VERSION ""

NS_ :

BS_:

BU_: LMFS RMFS TPMS TCU_ERAGLONASS E_APU PCCM NOX_2 NOX_1 ENGINE_CONTROL_MODULE TRANSMISSION INTARDER EBS TACHOGRAPH INSTRUMENT_CLUSTER CAMERA RADAR BCM

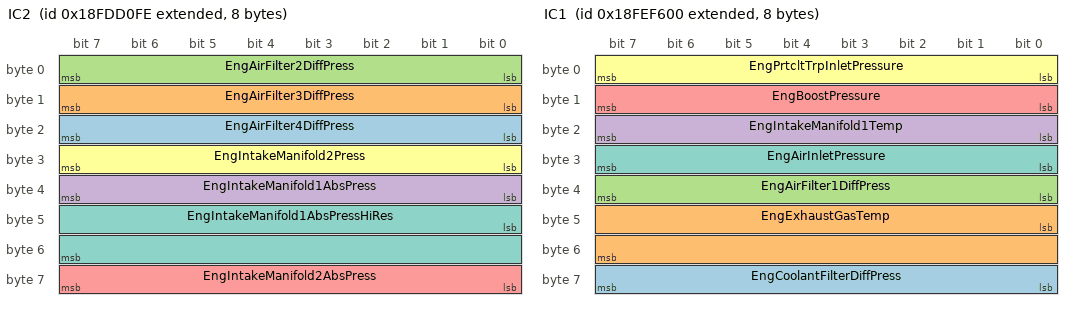
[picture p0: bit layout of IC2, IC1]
BO_ 2566770942 IC2: 8 Vector__XXX
 SG_ EngAirFilter4DiffPress : 16|8@1+ (0.05,0) [0|12.5] "kPa" Vector__XXX
 SG_ EngAirFilter3DiffPress : 8|8@1+ (0.05,0) [0|12.5] "kPa" Vector__XXX
 SG_ EngAirFilter2DiffPress : 0|8@1+ (0.05,0) [0|12.5] "kPa" Vector__XXX
 SG_ EngIntakeManifold1AbsPress : 32|8@1+ (0.1,0) [0|25.5] "kPa" Vector__XXX
 SG_ EngIntakeManifold2AbsPress : 56|8@1+ (2,0) [0|500] "kPa" Vector__XXX
 SG_ EngIntakeManifold2Press : 24|8@1+ (2,0) [0|500] "kPa" Vector__XXX
 SG_ EngIntakeManifold1AbsPressHiRes : 40|16@1+ (0.1,0) [0|6425.5] "kPa" Vector__XXX

BO_ 2566845952 IC1: 8 ENGINE_CONTROL_MODULE
 SG_ EngCoolantFilterDiffPress : 56|8@1+ (0.5,0) [0|125] "kPa"  PCCM,BCM
 SG_ EngExhaustGasTemp : 40|16@1+ (0.03125,-271) [-271|1715] "deg C"  PCCM,BCM
 SG_ EngAirFilter1DiffPress : 32|8@1+ (0.05,0) [0|12.5] "kPa"  PCCM,BCM
 SG_ EngIntakeManifold1Temp : 16|8@1+ (1,-40) [-40|210] "deg C"  PCCM,BCM
 SG_ EngBoostPressure : 8|8@1+ (2,0) [0|500] "kPa"  PCCM,BCM
 SG_ EngPrtcltTrpInletPressure : 0|8@1+ (0.5,0) [0|125] "kPa"  PCCM,BCM
 SG_ EngAirInletPressure : 24|8@1+ (2,0) [0|500] "kPa"  PCCM,BCM

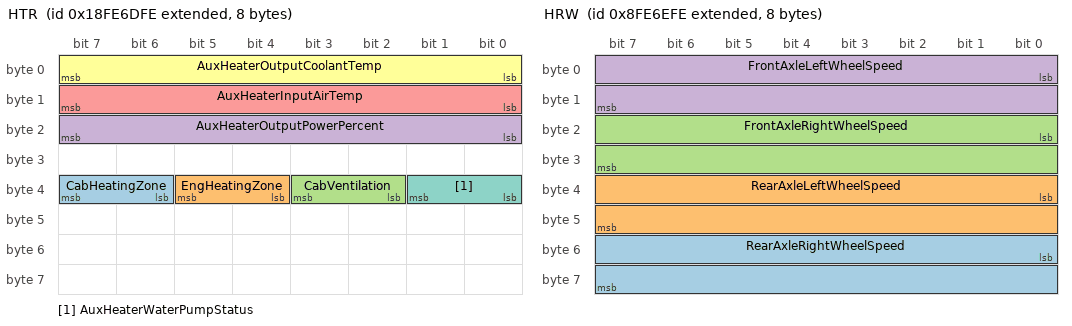
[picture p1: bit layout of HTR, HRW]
BO_ 2566811134 HTR: 8 Vector__XXX
 SG_ CabHeatingZone : 38|2@1+ (1,0) [0|3] "" Vector__XXX
 SG_ EngHeatingZone : 36|2@1+ (1,0) [0|3] "" Vector__XXX
 SG_ CabVentilation : 34|2@1+ (1,0) [0|3] "" Vector__XXX
 SG_ AuxHeaterOutputPowerPercent : 16|8@1+ (0.4,0) [0|100] "%" Vector__XXX
 SG_ AuxHeaterInputAirTemp : 8|8@1+ (1,-40) [-40|210] "deg C" Vector__XXX
 SG_ AuxHeaterOutputCoolantTemp : 0|8@1+ (1,-40) [-40|210] "deg C" Vector__XXX
 SG_ AuxHeaterWaterPumpStatus : 32|2@1+ (1,0) [0|3] "" Vector__XXX

BO_ 2298375934 HRW: 8 Vector__XXX
 SG_ RearAxleRightWheelSpeed : 48|16@1+ (0.00390625,0) [0|250.996] "km/h" Vector__XXX
 SG_ RearAxleLeftWheelSpeed : 32|16@1+ (0.00390625,0) [0|250.996] "km/h" Vector__XXX
 SG_ FrontAxleRightWheelSpeed : 16|16@1+ (0.00390625,0) [0|250.996] "km/h" Vector__XXX
 SG_ FrontAxleLeftWheelSpeed : 0|16@1+ (0.00390625,0) [0|250.996] "km/h" Vector__XXX

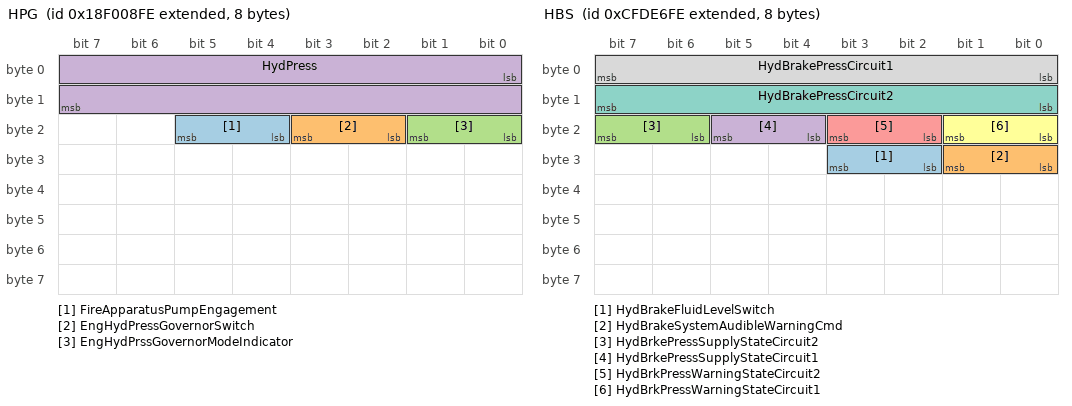
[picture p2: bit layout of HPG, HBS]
BO_ 2565867774 HPG: 8 Vector__XXX
 SG_ FireApparatusPumpEngagement : 20|2@1+ (1,0) [0|3] "" Vector__XXX
 SG_ EngHydPressGovernorSwitch : 18|2@1+ (1,0) [0|3] "" Vector__XXX
 SG_ EngHydPrssGovernorModeIndicator : 16|2@1+ (1,0) [0|3] "" Vector__XXX
 SG_ HydPress : 0|16@1+ (2,0) [0|128510] "kPa" Vector__XXX

BO_ 2566841600 HOURS: 8 ENGINE_CONTROL_MODULE
 SG_ EngTotalRevolutions : 32|32@1+ (1000,0) [0|2013264920] "r"  PCCM,BCM,INSTRUMENT_CLUSTER
 SG_ EngTotalHoursOfOperation : 0|32@1+ (0.05,0) [0|210554060.75] "hr"  PCCM,BCM,INSTRUMENT_CLUSTER

BO_ 2365449982 HBS: 8 Vector__XXX
 SG_ HydBrakeFluidLevelSwitch : 26|2@1+ (1,0) [0|3] "" Vector__XXX
 SG_ HydBrakeSystemAudibleWarningCmd : 24|2@1+ (1,0) [0|3] "" Vector__XXX
 SG_ HydBrkePressSupplyStateCircuit2 : 22|2@1+ (1,0) [0|3] "" Vector__XXX
 SG_ HydBrkePressSupplyStateCircuit1 : 20|2@1+ (1,0) [0|3] "" Vector__XXX
 SG_ HydBrkPressWarningStateCircuit2 : 18|2@1+ (1,0) [0|3] "" Vector__XXX
 SG_ HydBrkPressWarningStateCircuit1 : 16|2@1+ (1,0) [0|3] "" Vector__XXX
 SG_ HydBrakePressCircuit2 : 8|8@1+ (100,0) [0|25] "MPa" Vector__XXX
 SG_ HydBrakePressCircuit1 : 0|8@1+ (100,0) [0|25] "MPa" Vector__XXX

BO_ 2633939198 GTFI: 22 Vector__XXX
 SG_ TripDriveFuelEconomy : 160|16@1+ (0.001953125,0) [0|125.5] "km/kg" Vector__XXX
 SG_ TrpPTOGovernorNonmovingFuelUsed : 64|32@1+ (0.5,0) [0|2105540607.5] "kg" Vector__XXX
 SG_ TripVehicleIdleFuelUsed : 96|32@1+ (0.5,0) [0|2105540607.5] "kg" Vector__XXX
 SG_ TripCruiseFuelUsed : 128|32@1+ (0.5,0) [0|2105540607.5] "kg" Vector__XXX
 SG_ TripDriveFuelUsed : 0|32@1+ (0.5,0) [0|2105540607.5] "kg" Vector__XXX
 SG_ TripPTOGovernorMovingFuelUsed : 32|32@1+ (0.5,0) [0|2105540607.5] "kg" Vector__XXX

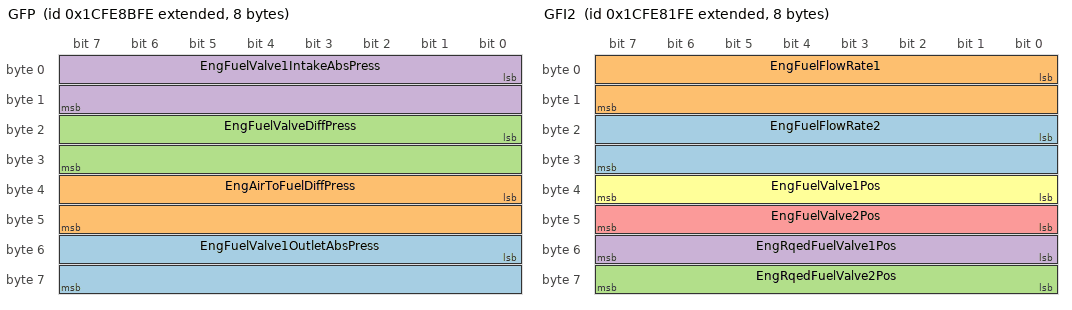
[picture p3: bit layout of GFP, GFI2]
BO_ 2633927678 GFP: 8 Vector__XXX
 SG_ EngFuelValve1OutletAbsPress : 48|16@1+ (0.1,0) [0|6425.5] "kPa" Vector__XXX
 SG_ EngAirToFuelDiffPress : 32|16@1+ (0.1,0) [0|6425.5] "kPa" Vector__XXX
 SG_ EngFuelValveDiffPress : 16|16@1+ (0.1,0) [0|6425.5] "kPa" Vector__XXX
 SG_ EngFuelValve1IntakeAbsPress : 0|16@1+ (0.1,0) [0|6425.5] "kPa" Vector__XXX

BO_ 2633925118 GFI2: 8 Vector__XXX
 SG_ EngFuelFlowRate2 : 16|16@1+ (0.1,0) [0|6425.5] "m³/h" Vector__XXX
 SG_ EngFuelFlowRate1 : 0|16@1+ (0.1,0) [0|6425.5] "m³/h" Vector__XXX
 SG_ EngRqedFuelValve2Pos : 56|8@1+ (0.4,0) [0|100] "%" Vector__XXX
 SG_ EngRqedFuelValve1Pos : 48|8@1+ (0.4,0) [0|100] "%" Vector__XXX
 SG_ EngFuelValve2Pos : 40|8@1+ (0.4,0) [0|100] "%" Vector__XXX
 SG_ EngFuelValve1Pos : 32|8@1+ (0.4,0) [0|100] "%" Vector__XXX

BO_ 2633937662 GFI1: 8 Vector__XXX
 SG_ TotalEngPTOGovernorFuelUsed : 0|32@1+ (0.5,0) [0|2105540607.5] "kg" Vector__XXX
 SG_ TripAverageFuelRate : 32|16@1+ (0.05,0) [0|3212.75] "kg/h" Vector__XXX
 SG_ EngFuelSpecificGravity : 48|16@1+ (0.0001,0) [0|6.4255] "" Vector__XXX

BO_ 2566804990 GFD: 8 Vector__XXX
 SG_ SpecificHeatRatio : 0|16@1+ (0.001,0) [0|64.255] "" Vector__XXX

BO_ 2633936894 GFC: 8 Vector__XXX
 SG_ TotalFuelUsed : 32|32@1+ (0.5,0) [0|2105540607.5] "kg" Vector__XXX
 SG_ TripFuel : 0|32@1+ (0.5,0) [0|2105540607.5] "kg" Vector__XXX

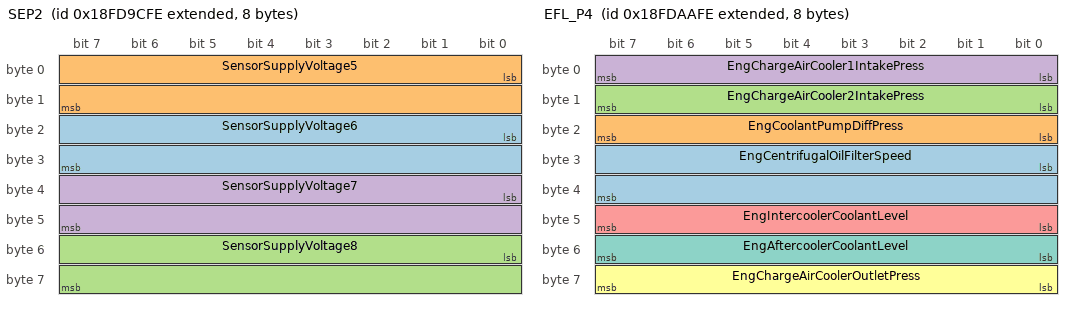
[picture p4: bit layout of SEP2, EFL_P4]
BO_ 2566757630 SEP2: 8 Vector__XXX
 SG_ SensorSupplyVoltage6 : 16|16@1+ (0.05,0) [0|3212.75] "V" Vector__XXX
 SG_ SensorSupplyVoltage5 : 0|16@1+ (0.05,0) [0|3212.75] "V" Vector__XXX
 SG_ SensorSupplyVoltage8 : 48|16@1+ (0.05,0) [0|3212.75] "V" Vector__XXX
 SG_ SensorSupplyVoltage7 : 32|16@1+ (0.05,0) [0|3212.75] "V" Vector__XXX

BO_ 2566757886 SEP1: 8 Vector__XXX
 SG_ SensorSupplyVoltage4 : 48|16@1+ (0.05,0) [0|3212.75] "V" Vector__XXX
 SG_ SensorSupplyVoltage3 : 32|16@1+ (0.05,0) [0|3212.75] "V" Vector__XXX
 SG_ SensorSupplyVoltage2 : 16|16@1+ (0.05,0) [0|3212.75] "V" Vector__XXX
 SG_ SensorSupplyVoltage1 : 0|16@1+ (0.05,0) [0|3212.75] "V" Vector__XXX

BO_ 2566759678 PTODE: 8 Vector__XXX
 SG_ EnggmntSttusTransInputShaftPTO1 : 38|2@1+ (1,0) [0|3] "" Vector__XXX
 SG_ EnggmntSttusTransInputShaftPTO2 : 36|2@1+ (1,0) [0|3] "" Vector__XXX
 SG_ EnggmntSttusTransOutputShaftPTO : 34|2@1+ (1,0) [0|3] "" Vector__XXX
 SG_ EnggmntSttsTrnsfrCsOtptShaftPTO : 32|2@1+ (1,0) [0|3] "" Vector__XXX
 SG_ EnggmntCnsntTransInputShaftPTO1 : 22|2@1+ (1,0) [0|3] "" Vector__XXX
 SG_ EnggmntCnsntTransInputShaftPTO2 : 20|2@1+ (1,0) [0|3] "" Vector__XXX
 SG_ EnggmntCnsntTransOutputShaftPTO : 18|2@1+ (1,0) [0|3] "" Vector__XXX
 SG_ EnggmntCnsntTrnsfrCsOtptShftPTO : 16|2@1+ (1,0) [0|3] "" Vector__XXX
 SG_ EnableSwitchTransInputShaftPTO1 : 6|2@1+ (1,0) [0|3] "" Vector__XXX
 SG_ EnableSwitchTransInputShaftPTO2 : 4|2@1+ (1,0) [0|3] "" Vector__XXX
 SG_ EnableSwitchTransOutputShaftPTO : 2|2@1+ (1,0) [0|3] "" Vector__XXX
 SG_ EnblSwtchTrnsfrCsOutputShaftPTO : 0|2@1+ (1,0) [0|3] "" Vector__XXX
 SG_ EnggmntSttsPTOEngAccssoryDrive2 : 44|2@1+ (1,0) [0|3] "" Vector__XXX
 SG_ EnggmntSttsPTOEngAccssoryDrive1 : 42|2@1+ (1,0) [0|3] "" Vector__XXX
 SG_ EnggmntCnsntPTOEngAccssryDrive2 : 28|2@1+ (1,0) [0|3] "" Vector__XXX
 SG_ EnggmntCnsntPTOEngAccssryDrive1 : 26|2@1+ (1,0) [0|3] "" Vector__XXX
 SG_ EngagementStatusPTOEngFlywheel : 40|2@1+ (1,0) [0|3] "" Vector__XXX
 SG_ EngagementConsentPTOEngFlywheel : 24|2@1+ (1,0) [0|3] "" Vector__XXX
 SG_ EnblSwitchPTOEngAccessoryDrive2 : 12|2@1+ (1,0) [0|3] "" Vector__XXX
 SG_ EnblSwitchPTOEngAccessoryDrive1 : 10|2@1+ (1,0) [0|3] "" Vector__XXX
 SG_ EnableSwitchPTOEngFlywheel : 8|2@1+ (1,0) [0|3] "" Vector__XXX
 SG_ AtLeastOnePTOEngaged : 48|2@1+ (1,0) [0|3] "" Vector__XXX

BO_ 2432541438 GFI3: 8 Vector__XXX
 SG_ EngFuelValve2OutletAbsPress : 48|16@1+ (0.1,0) [0|6425.5] "kPa" Vector__XXX
 SG_ EngFuelTemp2 : 32|8@1+ (1,-40) [-40|210] "deg C" Vector__XXX
 SG_ EngGas2MassFlowRate : 16|16@1+ (0.05,0) [0|3212.75] "kg/h" Vector__XXX
 SG_ EngFuelValve2IntakeAbsPress : 0|16@1+ (0.1,0) [0|6425.5] "kPa" Vector__XXX

BO_ 2566761214 EFL_P4: 8 Vector__XXX
 SG_ EngCentrifugalOilFilterSpeed : 24|16@1+ (4,0) [0|257020] "rpm" Vector__XXX
 SG_ EngCoolantPumpDiffPress : 16|8@1+ (1.64,-7) [-7|403] "kPa" Vector__XXX
 SG_ EngChargeAirCooler2IntakePress : 8|8@1+ (2,0) [0|500] "kPa" Vector__XXX
 SG_ EngChargeAirCooler1IntakePress : 0|8@1+ (2,0) [0|500] "kPa" Vector__XXX
 SG_ EngIntercoolerCoolantLevel : 40|8@1+ (0.4,0) [0|100] "%" Vector__XXX
 SG_ EngChargeAirCoolerOutletPress : 56|8@1+ (2,0) [0|500] "kPa" Vector__XXX
 SG_ EngAftercoolerCoolantLevel : 48|8@1+ (0.4,0) [0|100] "%" Vector__XXX

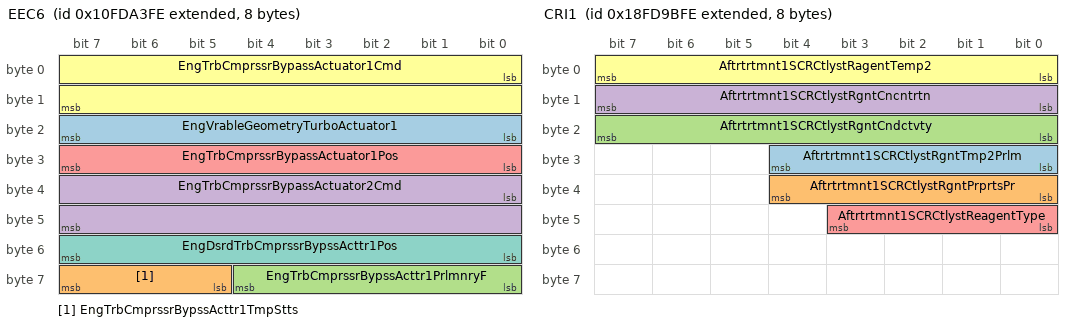
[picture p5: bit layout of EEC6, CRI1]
BO_ 2432541694 EEC6: 8 Vector__XXX
 SG_ EngVrableGeometryTurboActuator1 : 16|8@1+ (0.4,0) [0|100] "%" Vector__XXX
 SG_ EngTrbCmprssrBypssActtr1TmpStts : 61|3@1+ (1,0) [0|7] "" Vector__XXX
 SG_ EngTrbCmprssrBypssActtr1PrlmnryF : 56|5@1+ (1,0) [0|31] "" Vector__XXX
 SG_ EngTrbCmprssrBypassActuator2Cmd : 32|16@1+ (0.0025,0) [0|160.6375] "%" Vector__XXX
 SG_ EngTrbCmprssrBypassActuator1Pos : 24|8@1+ (0.4,0) [0|100] "%" Vector__XXX
 SG_ EngTrbCmprssrBypassActuator1Cmd : 0|16@1+ (0.0025,0) [0|160.6375] "%" Vector__XXX
 SG_ EngDsrdTrbCmprssrBypssActtr1Pos : 48|8@1+ (0.4,0) [0|100] "%" Vector__XXX

BO_ 2566759934 DC2: 8 Vector__XXX
 SG_ EnableStatusOfDoor10 : 58|2@1+ (1,0) [0|3] "" Vector__XXX
 SG_ OpenStatusOfDoor10 : 56|2@1+ (1,0) [0|3] "" Vector__XXX
 SG_ LockStatusOfDoor10 : 54|2@1+ (1,0) [0|3] "" Vector__XXX
 SG_ EnableStatusOfDoor9 : 52|2@1+ (1,0) [0|3] "" Vector__XXX
 SG_ OpenStatusOfDoor9 : 50|2@1+ (1,0) [0|3] "" Vector__XXX
 SG_ LockStatusOfDoor9 : 48|2@1+ (1,0) [0|3] "" Vector__XXX
 SG_ EnableStatusOfDoor8 : 46|2@1+ (1,0) [0|3] "" Vector__XXX
 SG_ OpenStatusOfDoor8 : 44|2@1+ (1,0) [0|3] "" Vector__XXX
 SG_ LockStatusOfDoor8 : 42|2@1+ (1,0) [0|3] "" Vector__XXX
 SG_ EnableStatusOfDoor7 : 40|2@1+ (1,0) [0|3] "" Vector__XXX
 SG_ OpenStatusOfDoor7 : 38|2@1+ (1,0) [0|3] "" Vector__XXX
 SG_ LockStatusOfDoor7 : 36|2@1+ (1,0) [0|3] "" Vector__XXX
 SG_ EnableStatusOfDoor6 : 34|2@1+ (1,0) [0|3] "" Vector__XXX
 SG_ OpenStatusOfDoor6 : 32|2@1+ (1,0) [0|3] "" Vector__XXX
 SG_ LockStatusOfDoor6 : 30|2@1+ (1,0) [0|3] "" Vector__XXX
 SG_ EnableStatusOfDoor5 : 28|2@1+ (1,0) [0|3] "" Vector__XXX
 SG_ OpenStatusOfDoor5 : 26|2@1+ (1,0) [0|3] "" Vector__XXX
 SG_ LockStatusOfDoor5 : 24|2@1+ (1,0) [0|3] "" Vector__XXX
 SG_ EnableStatusOfDoor4 : 22|2@1+ (1,0) [0|3] "" Vector__XXX
 SG_ OpenStatusOfDoor4 : 20|2@1+ (1,0) [0|3] "" Vector__XXX
 SG_ LockStatusOfDoor4 : 18|2@1+ (1,0) [0|3] "" Vector__XXX
 SG_ EnableStatusOfDoor3 : 16|2@1+ (1,0) [0|3] "" Vector__XXX
 SG_ OpenStatusOfDoor3 : 14|2@1+ (1,0) [0|3] "" Vector__XXX
 SG_ LockStatusOfDoor3 : 12|2@1+ (1,0) [0|3] "" Vector__XXX
 SG_ EnableStatusOfDoor2 : 10|2@1+ (1,0) [0|3] "" Vector__XXX
 SG_ OpenStatusOfDoor2 : 8|2@1+ (1,0) [0|3] "" Vector__XXX
 SG_ LockStatusOfDoor2 : 6|2@1+ (1,0) [0|3] "" Vector__XXX
 SG_ EnableStatusOfDoor1 : 4|2@1+ (1,0) [0|3] "" Vector__XXX
 SG_ OpenStatusOfDoor1 : 2|2@1+ (1,0) [0|3] "" Vector__XXX
 SG_ LockStatusOfDoor1 : 0|2@1+ (1,0) [0|3] "" Vector__XXX

BO_ 2566757374 CRI1: 8 Vector__XXX
 SG_ Aftrtrtmnt1SCRCtlystRgntTmp2Prlm : 24|5@1+ (1,0) [0|31] "" Vector__XXX
 SG_ Aftrtrtmnt1SCRCtlystRgntPrprtsPr : 32|5@1+ (1,0) [0|31] "" Vector__XXX
 SG_ Aftrtrtmnt1SCRCtlystRgntCndctvty : 16|8@1+ (5,0) [0|1250] "microSiemens/mm" Vector__XXX
 SG_ Aftrtrtmnt1SCRCtlystRgntCncntrtn : 8|8@1+ (0.25,0) [0|62.5] "%" Vector__XXX
 SG_ Aftrtrtmnt1SCRCtlystReagentType : 40|4@1+ (1,0) [0|15] "" Vector__XXX
 SG_ Aftrtrtmnt1SCRCtlystRagentTemp2 : 0|8@1+ (1,-40) [-40|210] "deg C" Vector__XXX

BO_ 2364546302 RGAAQ: 8 Vector__XXX
 SG_ RqdGnrtrAvrgLneLineACRMSVoltage : 0|32@1+ (0.0078125,0) [0|32899071] "V" Vector__XXX

BO_ 2431654654 TFAC: 8 Vector__XXX
 SG_ EngThrottleActuator2CtrlCmd : 16|16@1+ (0.0025,0) [0|160.6375] "%" Vector__XXX
 SG_ EngThrottleActuator1CtrlCmd : 0|16@1+ (0.0025,0) [0|160.6375] "%" Vector__XXX
 SG_ EngFuelActuator2CtrlCmd : 48|16@1+ (0.0025,0) [0|160.6375] "%" Vector__XXX
 SG_ EngFuelActuator1CtrlCmd : 32|16@1+ (0.0025,0) [0|160.6375] "%" Vector__XXX

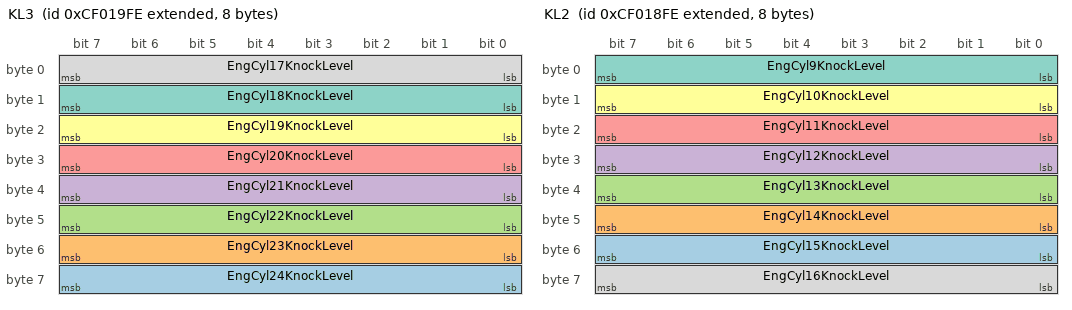
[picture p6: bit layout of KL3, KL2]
BO_ 2364545534 KL3: 8 Vector__XXX
 SG_ EngCyl24KnockLevel : 56|8@1+ (1,0) [0|250] "%" Vector__XXX
 SG_ EngCyl23KnockLevel : 48|8@1+ (1,0) [0|250] "%" Vector__XXX
 SG_ EngCyl22KnockLevel : 40|8@1+ (1,0) [0|250] "%" Vector__XXX
 SG_ EngCyl21KnockLevel : 32|8@1+ (1,0) [0|250] "%" Vector__XXX
 SG_ EngCyl20KnockLevel : 24|8@1+ (1,0) [0|250] "%" Vector__XXX
 SG_ EngCyl19KnockLevel : 16|8@1+ (1,0) [0|250] "%" Vector__XXX
 SG_ EngCyl18KnockLevel : 8|8@1+ (1,0) [0|250] "%" Vector__XXX
 SG_ EngCyl17KnockLevel : 0|8@1+ (1,0) [0|250] "%" Vector__XXX

BO_ 2364545278 KL2: 8 Vector__XXX
 SG_ EngCyl15KnockLevel : 48|8@1+ (1,0) [0|250] "%" Vector__XXX
 SG_ EngCyl14KnockLevel : 40|8@1+ (1,0) [0|250] "%" Vector__XXX
 SG_ EngCyl13KnockLevel : 32|8@1+ (1,0) [0|250] "%" Vector__XXX
 SG_ EngCyl12KnockLevel : 24|8@1+ (1,0) [0|250] "%" Vector__XXX
 SG_ EngCyl11KnockLevel : 16|8@1+ (1,0) [0|250] "%" Vector__XXX
 SG_ EngCyl10KnockLevel : 8|8@1+ (1,0) [0|250] "%" Vector__XXX
 SG_ EngCyl9KnockLevel : 0|8@1+ (1,0) [0|250] "%" Vector__XXX
 SG_ EngCyl16KnockLevel : 56|8@1+ (1,0) [0|250] "%" Vector__XXX

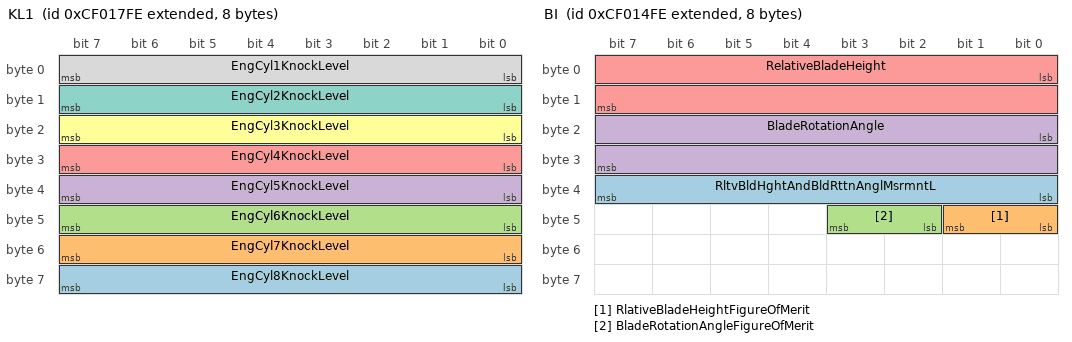
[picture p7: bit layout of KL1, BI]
BO_ 2364545022 KL1: 8 Vector__XXX
 SG_ EngCyl8KnockLevel : 56|8@1+ (1,0) [0|250] "%" Vector__XXX
 SG_ EngCyl7KnockLevel : 48|8@1+ (1,0) [0|250] "%" Vector__XXX
 SG_ EngCyl6KnockLevel : 40|8@1+ (1,0) [0|250] "%" Vector__XXX
 SG_ EngCyl5KnockLevel : 32|8@1+ (1,0) [0|250] "%" Vector__XXX
 SG_ EngCyl4KnockLevel : 24|8@1+ (1,0) [0|250] "%" Vector__XXX
 SG_ EngCyl3KnockLevel : 16|8@1+ (1,0) [0|250] "%" Vector__XXX
 SG_ EngCyl2KnockLevel : 8|8@1+ (1,0) [0|250] "%" Vector__XXX
 SG_ EngCyl1KnockLevel : 0|8@1+ (1,0) [0|250] "%" Vector__XXX

BO_ 2364544766 CCS: 8 Vector__XXX
 SG_ EngCyl9CombustionStatus : 16|2@1+ (1,0) [0|3] "" Vector__XXX
 SG_ EngCyl8CombustionStatus : 14|2@1+ (1,0) [0|3] "" Vector__XXX
 SG_ EngCyl7CombustionStatus : 12|2@1+ (1,0) [0|3] "" Vector__XXX
 SG_ EngCyl6CombustionStatus : 10|2@1+ (1,0) [0|3] "" Vector__XXX
 SG_ EngCyl5CombustionStatus : 8|2@1+ (1,0) [0|3] "" Vector__XXX
 SG_ EngCyl4CombustionStatus : 6|2@1+ (1,0) [0|3] "" Vector__XXX
 SG_ EngCyl3CombustionStatus : 4|2@1+ (1,0) [0|3] "" Vector__XXX
 SG_ EngCyl2CombustionStatus : 2|2@1+ (1,0) [0|3] "" Vector__XXX
 SG_ EngCyl24CombustionStatus : 46|2@1+ (1,0) [0|3] "" Vector__XXX
 SG_ EngCyl23CombustionStatus : 44|2@1+ (1,0) [0|3] "" Vector__XXX
 SG_ EngCyl22CombustionStatus : 42|2@1+ (1,0) [0|3] "" Vector__XXX
 SG_ EngCyl21CombustionStatus : 40|2@1+ (1,0) [0|3] "" Vector__XXX
 SG_ EngCyl20CombustionStatus : 38|2@1+ (1,0) [0|3] "" Vector__XXX
 SG_ EngCyl1CombustionStatus : 0|2@1+ (1,0) [0|3] "" Vector__XXX
 SG_ EngCyl19CombustionStatus : 36|2@1+ (1,0) [0|3] "" Vector__XXX
 SG_ EngCyl18CombustionStatus : 34|2@1+ (1,0) [0|3] "" Vector__XXX
 SG_ EngCyl17CombustionStatus : 32|2@1+ (1,0) [0|3] "" Vector__XXX
 SG_ EngCyl16CombustionStatus : 30|2@1+ (1,0) [0|3] "" Vector__XXX
 SG_ EngCyl15CombustionStatus : 28|2@1+ (1,0) [0|3] "" Vector__XXX
 SG_ EngCyl14CombustionStatus : 26|2@1+ (1,0) [0|3] "" Vector__XXX
 SG_ EngCyl13CombustionStatus : 24|2@1+ (1,0) [0|3] "" Vector__XXX
 SG_ EngCyl12CombustionStatus : 22|2@1+ (1,0) [0|3] "" Vector__XXX
 SG_ EngCyl11CombustionStatus : 20|2@1+ (1,0) [0|3] "" Vector__XXX
 SG_ EngCyl10CombustionStatus : 18|2@1+ (1,0) [0|3] "" Vector__XXX

BO_ 2364544510 RGTARP: 8 Vector__XXX
 SG_ RqGenOverallPowerFactorLagging : 48|2@1+ (1,0) [0|4] "" Vector__XXX
 SG_ RqGeneratorOverallPowerFactor : 32|16@1+ (6.103515625E-005,-1) [-1|2.921814] "" Vector__XXX
 SG_ RqGeneratorTotalACReactivePower : 0|32@1+ (1,-2000000000) [-2000000000|2000000000] "VA" Vector__XXX

BO_ 2364544254 BI: 8 Vector__XXX
 SG_ RltvBldHghtAndBldRttnAnglMsrmntL : 32|8@1+ (0.5,0) [0|125] "ms" Vector__XXX
 SG_ RlativeBladeHeightFigureOfMerit : 40|2@1+ (1,0) [0|3] "" Vector__XXX
 SG_ BladeRotationAngleFigureOfMerit : 42|2@1+ (1,0) [0|3] "" Vector__XXX
 SG_ BladeRotationAngle : 16|16@1+ (0.0078125,-200) [-200|301.99] "deg" Vector__XXX
 SG_ RelativeBladeHeight : 0|16@1+ (0.1,-3200) [-3200|3225.5] "mm" Vector__XXX

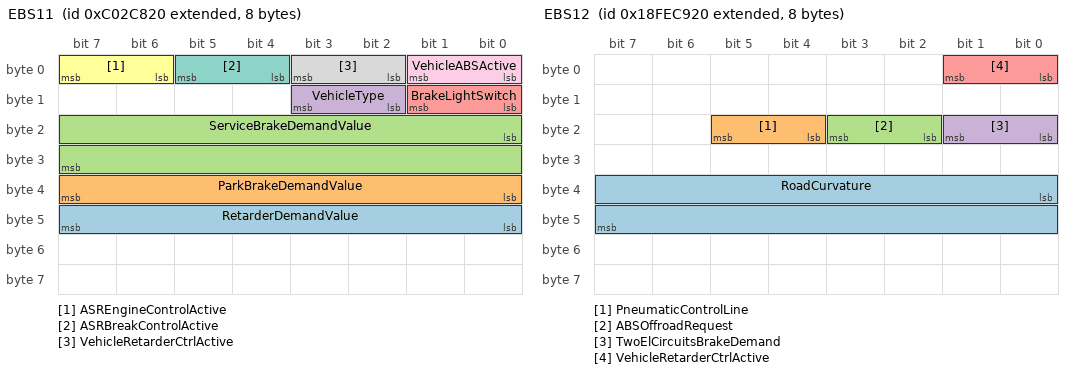
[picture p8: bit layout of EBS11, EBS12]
BO_ 2348992544 EBS11: 8 Vector__XXX
 SG_ RetarderDemandValue : 40|8@1+ (1,-125) [-125|125] "%" Vector__XXX
 SG_ ParkBrakeDemandValue : 32|8@1+ (0.4,0) [0|100] "%" Vector__XXX
 SG_ ServiceBrakeDemandValue : 16|16@1+ (0.01953125,0) [0|1255] "kPa" Vector__XXX
 SG_ VehicleType : 10|2@1+ (1,0) [0|3] "" Vector__XXX
 SG_ BrakeLightSwitch : 8|2@1+ (1,0) [0|3] "" Vector__XXX
 SG_ ASREngineControlActive : 6|2@1+ (1,0) [0|3] "" Vector__XXX
 SG_ ASRBreakControlActive : 4|2@1+ (1,0) [0|3] "" Vector__XXX
 SG_ VehicleRetarderCtrlActive : 2|2@1+ (1,0) [0|3] "" Vector__XXX
 SG_ VehicleABSActive : 0|2@1+ (1,0) [0|1] "" Vector__XXX

BO_ 2566834464 EBS12: 8 Vector__XXX
 SG_ RoadCurvature : 32|16@1+ (0.0078125,-250) [-250|251.992] "1/km" Vector__XXX
 SG_ PneumaticControlLine : 20|2@1+ (1,0) [0|1] "" Vector__XXX
 SG_ ABSOffroadRequest : 18|2@1+ (1,0) [0|1] "" Vector__XXX
 SG_ TwoElCircuitsBrakeDemand : 16|2@1+ (1,0) [0|1] "" Vector__XXX
 SG_ VehicleRetarderCtrlActive : 0|2@1+ (1,0) [0|3] "" Vector__XXX

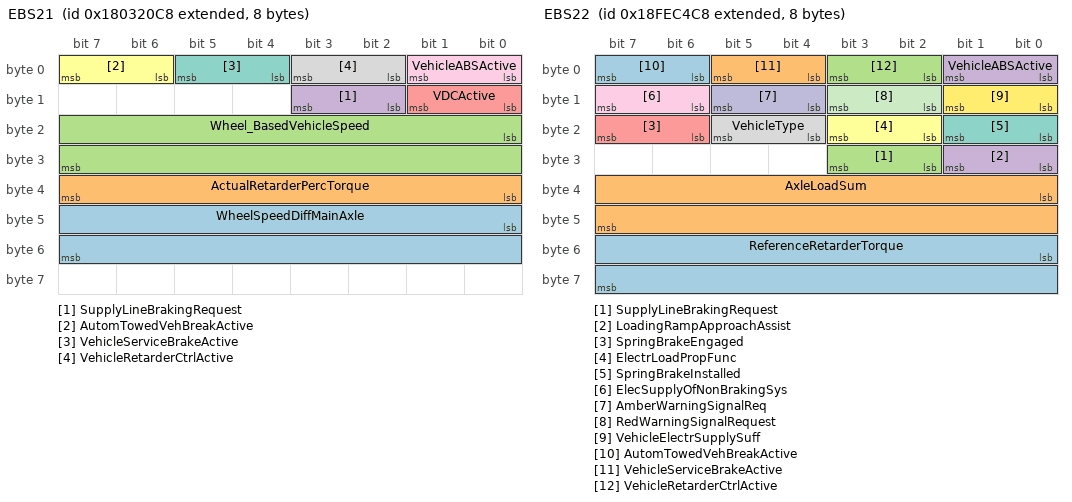
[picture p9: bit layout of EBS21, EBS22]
BO_ 2550341832 EBS21: 8 Vector__XXX
 SG_ WheelSpeedDiffMainAxle : 40|16@1+ (0.00390625,-125) [-125|125] "km/hr" Vector__XXX
 SG_ ActualRetarderPercTorque : 32|8@1+ (1,-125) [-125|125] "%" Vector__XXX
 SG_ Wheel_BasedVehicleSpeed : 16|16@1+ (0.00390625,0) [0|251] "km/hr" Vector__XXX
 SG_ SupplyLineBrakingRequest : 10|2@1+ (1,0) [0|1] "" Vector__XXX
 SG_ VDCActive : 8|2@1+ (1,0) [0|1] "" Vector__XXX
 SG_ AutomTowedVehBreakActive : 6|2@1+ (1,0) [0|1] "" Vector__XXX
 SG_ VehicleServiceBrakeActive : 4|2@1+ (1,0) [0|1] "" Vector__XXX
 SG_ VehicleRetarderCtrlActive : 2|2@1+ (1,0) [0|3] "" Vector__XXX
 SG_ VehicleABSActive : 0|2@1+ (1,0) [0|1] "" Vector__XXX

BO_ 2566833352 EBS22: 8 Vector__XXX
 SG_ ReferenceRetarderTorque : 48|16@1+ (1,0) [0|64255] "Nm" Vector__XXX
 SG_ AxleLoadSum : 32|16@1+ (2,0) [0|128510] "kg" Vector__XXX
 SG_ SupplyLineBrakingRequest : 26|2@1+ (1,0) [0|1] "" Vector__XXX
 SG_ LoadingRampApproachAssist : 24|2@1+ (1,0) [0|1] "" Vector__XXX
 SG_ SpringBrakeEngaged : 22|2@1+ (1,0) [0|1] "" Vector__XXX
 SG_ ElectrLoadPropFunc : 18|2@1+ (1,0) [0|1] "" Vector__XXX
 SG_ SpringBrakeInstalled : 16|2@1+ (1,0) [0|1] "" Vector__XXX
 SG_ VehicleType : 20|2@1+ (1,0) [0|3] "" Vector__XXX
 SG_ ElecSupplyOfNonBrakingSys : 14|2@1+ (1,0) [0|1] "" Vector__XXX
 SG_ AmberWarningSignalReq : 12|2@1+ (1,0) [0|1] "" Vector__XXX
 SG_ RedWarningSignalRequest : 10|2@1+ (1,0) [0|1] "" Vector__XXX
 SG_ VehicleElectrSupplySuff : 8|2@1+ (1,0) [0|1] "" Vector__XXX
 SG_ AutomTowedVehBreakActive : 6|2@1+ (1,0) [0|1] "" Vector__XXX
 SG_ VehicleServiceBrakeActive : 4|2@1+ (1,0) [0|1] "" Vector__XXX
 SG_ VehicleRetarderCtrlActive : 2|2@1+ (1,0) [0|3] "" Vector__XXX
 SG_ VehicleABSActive : 0|2@1+ (1,0) [0|1] "" Vector__XXX

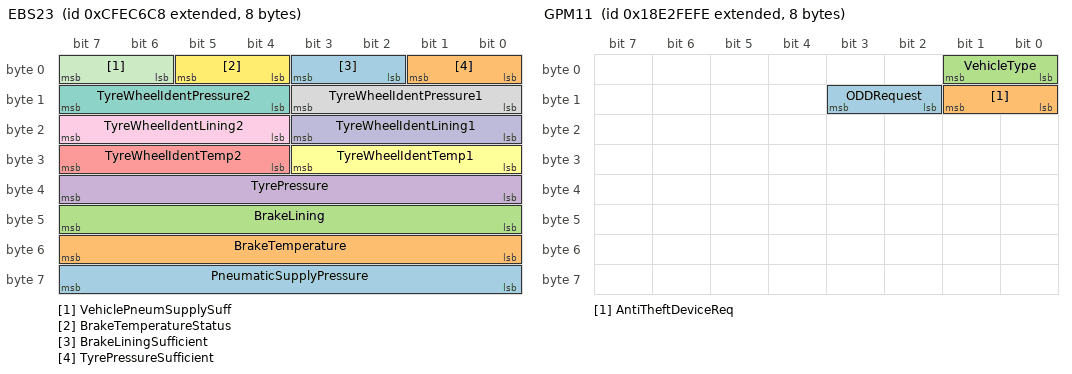
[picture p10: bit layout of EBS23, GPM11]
BO_ 2365507272 EBS23: 8 Vector__XXX
 SG_ PneumaticSupplyPressure : 56|8@1+ (5,0) [0|1250] "kPa" Vector__XXX
 SG_ BrakeTemperature : 48|8@1+ (10,0) [0|2500] "°C" Vector__XXX
 SG_ BrakeLining : 40|8@1+ (0.4,0) [0|100] "%" Vector__XXX
 SG_ TyrePressure : 32|8@1+ (10,0) [0|2500] "kPa" Vector__XXX
 SG_ TyreWheelIdentTemp2 : 28|4@1+ (1,0) [0|15] "" Vector__XXX
 SG_ TyreWheelIdentTemp1 : 24|4@1+ (1,0) [0|15] "" Vector__XXX
 SG_ TyreWheelIdentPressure2 : 12|4@1+ (1,0) [0|15] "" Vector__XXX
 SG_ TyreWheelIdentPressure1 : 8|4@1+ (1,0) [0|15] "" Vector__XXX
 SG_ TyreWheelIdentLining2 : 20|4@1+ (1,0) [0|15] "" Vector__XXX
 SG_ TyreWheelIdentLining1 : 16|4@1+ (1,0) [0|15] "" Vector__XXX
 SG_ VehiclePneumSupplySuff : 6|2@1+ (1,0) [0|1] "" Vector__XXX
 SG_ BrakeTemperatureStatus : 4|2@1+ (1,0) [0|1] "" Vector__XXX
 SG_ BrakeLiningSufficient : 2|2@1+ (1,0) [0|1] "" Vector__XXX
 SG_ TyrePressureSufficient : 0|2@1+ (1,0) [0|1] "" Vector__XXX

BO_ 2565013246 GPM11: 8 Vector__XXX
 SG_ ODDRequest : 10|2@1+ (1,0) [0|3] "" Vector__XXX
 SG_ AntiTheftDeviceReq : 8|2@1+ (1,0) [0|3] "" Vector__XXX
 SG_ VehicleType : 0|2@1+ (1,0) [0|3] "" Vector__XXX

BO_ 2566807038 GPM12: 8 Vector__XXX
 SG_ MaxVehicleSpeedLimit : 32|8@1+ (1,0) [0|250] "km/h" Vector__XXX
 SG_ EngineSpeedUpperLimit : 0|16@1+ (0.125,0) [0|8031.875] "rpm" Vector__XXX
 SG_ EngineSpeedLowerLimit : 16|16@1+ (0.125,0) [0|8191.875] "rpm" Vector__XXX

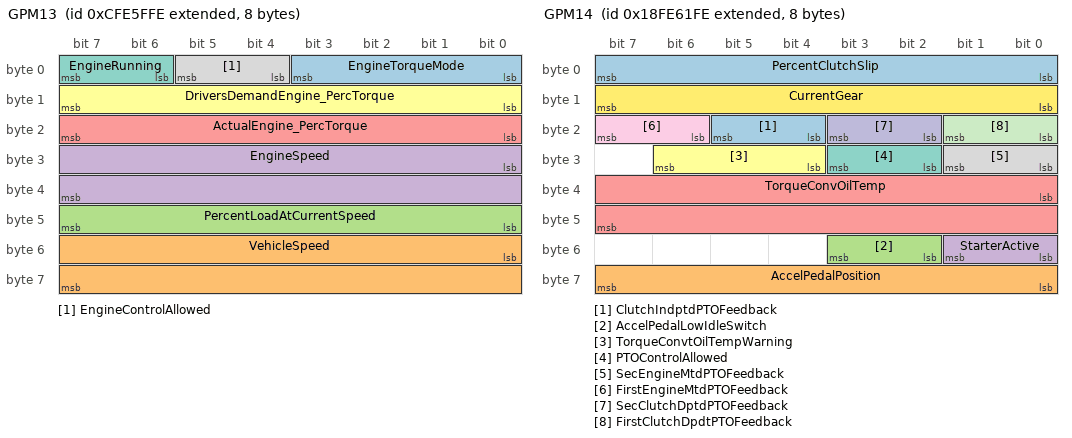
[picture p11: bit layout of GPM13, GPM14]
BO_ 2365480958 GPM13: 8 Vector__XXX
 SG_ EngineTorqueMode : 0|4@1+ (1,0) [0|15] "" Vector__XXX
 SG_ VehicleSpeed : 48|16@1+ (0.00390625,0) [0|250.996] "km/hr" Vector__XXX
 SG_ PercentLoadAtCurrentSpeed : 40|8@1+ (1,0) [0|125] "%" Vector__XXX
 SG_ EngineSpeed : 24|16@1+ (0.125,0) [0|8031.88] "rpm" Vector__XXX
 SG_ ActualEngine_PercTorque : 16|8@1+ (1,-125) [-125|125] "%" Vector__XXX
 SG_ DriversDemandEngine_PercTorque : 8|8@1+ (1,-125) [-125|125] "%" Vector__XXX
 SG_ EngineRunning : 6|2@1+ (1,0) [0|1] "" Vector__XXX
 SG_ EngineControlAllowed : 4|2@1+ (1,0) [0|1] "" Vector__XXX

BO_ 2566808062 GPM14: 8 Vector__XXX
 SG_ ClutchIndptdPTOFeedback : 20|2@1+ (1,0) [0|1] "" Vector__XXX
 SG_ AccelPedalPosition : 56|8@1+ (0.4,0) [0|100] "%" Vector__XXX
 SG_ AccelPedalLowIdleSwitch : 50|2@1+ (1,0) [0|1] "" Vector__XXX
 SG_ StarterActive : 48|2@1+ (1,0) [0|1] "" Vector__XXX
 SG_ TorqueConvOilTemp : 32|16@1+ (0.03125,-273) [-273|1735] "°C" Vector__XXX
 SG_ TorqueConvtOilTempWarning : 28|3@1+ (1,0) [0|2] "" Vector__XXX
 SG_ PTOControlAllowed : 26|2@1+ (1,0) [0|1] "" Vector__XXX
 SG_ SecEngineMtdPTOFeedback : 24|2@1+ (1,0) [0|1] "" Vector__XXX
 SG_ FirstEngineMtdPTOFeedback : 22|2@1+ (1,0) [0|1] "" Vector__XXX
 SG_ SecClutchDptdPTOFeedback : 18|2@1+ (1,0) [0|1] "" Vector__XXX
 SG_ FirstClutchDpdtPTOFeedback : 16|2@1+ (1,0) [0|1] "" Vector__XXX
 SG_ CurrentGear : 8|8@1+ (1,-125) [-125|125] "" Vector__XXX
 SG_ PercentClutchSlip : 0|8@1+ (0.4,0) [0|100] "%" Vector__XXX

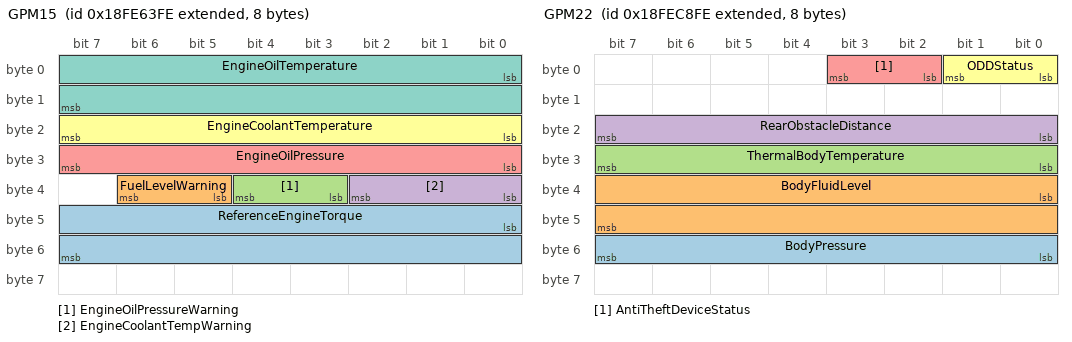
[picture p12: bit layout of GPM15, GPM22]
BO_ 2566808574 GPM15: 8 Vector__XXX
 SG_ ReferenceEngineTorque : 40|16@1+ (1,0) [0|64255] "Nm" Vector__XXX
 SG_ FuelLevelWarning : 37|2@1+ (1,0) [0|1] "" Vector__XXX
 SG_ EngineOilPressureWarning : 35|2@1+ (1,0) [0|1] "" Vector__XXX
 SG_ EngineCoolantTempWarning : 32|3@1+ (1,0) [0|2] "" Vector__XXX
 SG_ EngineOilPressure : 24|8@1+ (4,0) [0|1000] "kPa" Vector__XXX
 SG_ EngineCoolantTemperature : 16|8@1+ (1,-40) [-40|210] "°C" Vector__XXX
 SG_ EngineOilTemperature : 0|16@1+ (0.03125,-273) [-273|1735] "°C" Vector__XXX

BO_ 2566809086 GPM16: 8 Vector__XXX
 SG_ AmbientAirTemperature : 0|16@1+ (0.03125,-273) [-273|1735] "°C" Vector__XXX

BO_ 2564947710 GPM21: 8 Vector__XXX
 SG_ VehicleType : 0|2@1+ (1,0) [0|3] "" Vector__XXX

BO_ 2566834430 GPM22: 8 Vector__XXX
 SG_ BodyPressure : 48|8@1+ (0.1,0) [0|25] "bar" Vector__XXX
 SG_ BodyFluidLevel : 32|16@1+ (2,0) [0|128510] "L" Vector__XXX
 SG_ ThermalBodyTemperature : 24|8@1+ (1,-125) [-125|125] "°C" Vector__XXX
 SG_ RearObstacleDistance : 16|8@1+ (2,0) [0|500] "cm" Vector__XXX
 SG_ AntiTheftDeviceStatus : 2|2@1+ (1,0) [0|1] "" Vector__XXX
 SG_ ODDStatus : 0|2@1+ (1,0) [0|1] "" Vector__XXX

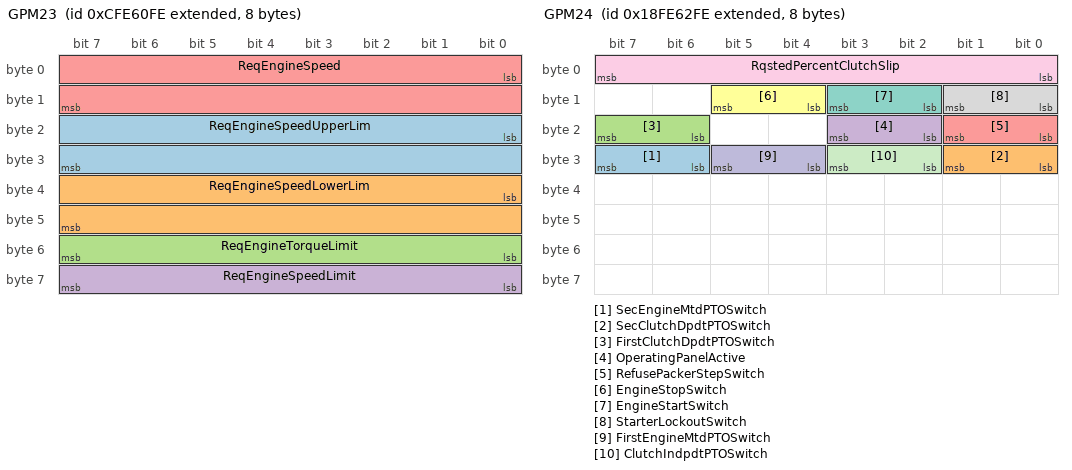
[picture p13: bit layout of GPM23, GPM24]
BO_ 2365481214 GPM23: 8 Vector__XXX
 SG_ ReqEngineSpeedUpperLim : 16|16@1+ (0.125,0) [0|8031.875] "rpm" Vector__XXX
 SG_ ReqEngineSpeedLowerLim : 32|16@1+ (0.125,0) [0|8031.875] "rpm" Vector__XXX
 SG_ ReqEngineTorqueLimit : 48|8@1+ (1,-125) [-125|125] "%" Vector__XXX
 SG_ ReqEngineSpeedLimit : 56|8@1+ (1,0) [0|250] "km/hr" Vector__XXX
 SG_ ReqEngineSpeed : 0|16@1+ (0.125,0) [0|8031.875] "rpm" Vector__XXX

BO_ 2566808318 GPM24: 8 Vector__XXX
 SG_ SecEngineMtdPTOSwitch : 30|2@1+ (1,0) [0|1] "" Vector__XXX
 SG_ SecClutchDpdtPTOSwitch : 24|2@1+ (1,0) [0|1] "" Vector__XXX
 SG_ FirstClutchDpdtPTOSwitch : 22|2@1+ (1,0) [0|1] "" Vector__XXX
 SG_ OperatingPanelActive : 18|2@1+ (1,0) [0|1] "" Vector__XXX
 SG_ RefusePackerStepSwitch : 16|2@1+ (1,0) [0|1] "" Vector__XXX
 SG_ EngineStopSwitch : 12|2@1+ (1,0) [0|1] "" Vector__XXX
 SG_ EngineStartSwitch : 10|2@1+ (1,0) [0|3] "" Vector__XXX
 SG_ StarterLockoutSwitch : 8|2@1+ (1,0) [0|1] "" Vector__XXX
 SG_ RqstedPercentClutchSlip : 0|8@1+ (0.4,0) [0|100] "%" Vector__XXX
 SG_ FirstEngineMtdPTOSwitch : 28|2@1+ (1,0) [0|1] "" Vector__XXX
 SG_ ClutchIndpdtPTOSwitch : 26|2@1+ (1,0) [0|1] "" Vector__XXX

BO_ 2566808830 GPM25: 8 Vector__XXX
 SG_ TrailerLeftSideMarkerLight : 20|2@1+ (1,0) [0|3] "" Vector__XXX
 SG_ TrailerLeftReversingLight : 16|2@1+ (1,0) [0|3] "" Vector__XXX
 SG_ TrailerLeftRearWidIndLight : 24|2@1+ (1,0) [0|3] "" Vector__XXX
 SG_ TrailerLeftRearRegPltLight : 32|2@1+ (1,0) [0|3] "" Vector__XXX
 SG_ TrailerLeftRearLight : 8|2@1+ (1,0) [0|3] "" Vector__XXX
 SG_ TrailerLeftRearFogLight : 12|2@1+ (1,0) [0|3] "" Vector__XXX
 SG_ TrailerLeftDirIndLight : 4|2@1+ (1,0) [0|3] "" Vector__XXX
 SG_ TrailerLeftCrnMarkerLight : 28|2@1+ (1,0) [0|3] "" Vector__XXX
 SG_ TrailerInteriorLight : 40|2@1+ (1,0) [0|3] "" Vector__XXX
 SG_ TrailerWorkLamp : 42|2@1+ (1,0) [0|3] "" Vector__XXX
 SG_ TrailerRotatingIdentLight : 38|2@1+ (1,0) [0|3] "" Vector__XXX
 SG_ TrailerRightStopLight : 2|2@1+ (1,0) [0|3] "" Vector__XXX
 SG_ TrailerRightSideMrkLight : 22|2@1+ (1,0) [0|3] "" Vector__XXX
 SG_ TrailerRightReversingLight : 18|2@1+ (1,0) [0|3] "" Vector__XXX
 SG_ TrailRightRearWidIndLight : 26|2@1+ (1,0) [0|3] "" Vector__XXX
 SG_ TrailerRightRearRegPltLight : 34|2@1+ (1,0) [0|3] "" Vector__XXX
 SG_ TrailerRightRearLight : 10|2@1+ (1,0) [0|3] "" Vector__XXX
 SG_ TrailerRightRearFogLight : 14|2@1+ (1,0) [0|3] "" Vector__XXX
 SG_ TrailerRightDirIndLight : 6|2@1+ (1,0) [0|3] "" Vector__XXX
 SG_ TrailerRightCrnMarkerLight : 30|2@1+ (1,0) [0|3] "" Vector__XXX
 SG_ TrailerRearWarningLight : 36|2@1+ (1,0) [0|3] "" Vector__XXX
 SG_ TrailerLeftStopLight : 0|2@1+ (1,0) [0|3] "" Vector__XXX

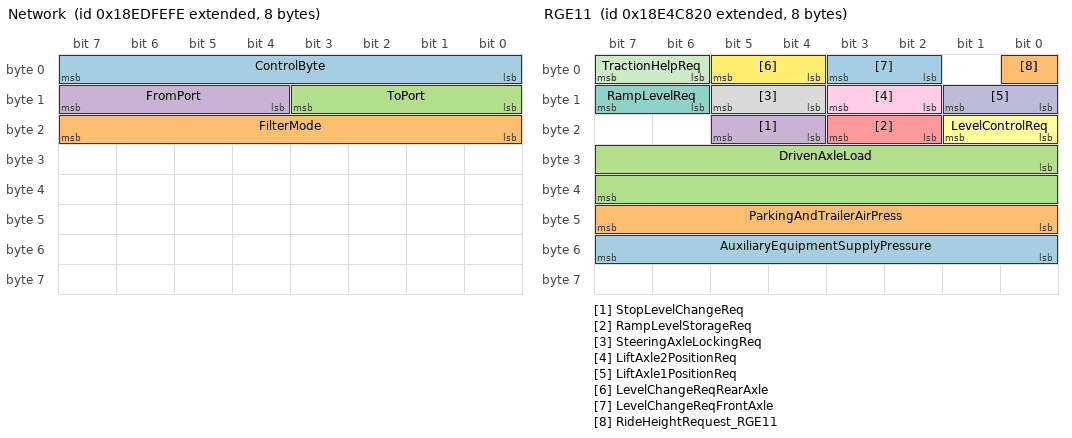
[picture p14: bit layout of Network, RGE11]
BO_ 2565734142 Network: 8 Vector__XXX
 SG_ ControlByte : 0|8@1+ (1,0) [0|255] "" Vector__XXX
 SG_ FilterMode : 16|8@1+ (1,0) [0|255] "" Vector__XXX
 SG_ ToPort : 8|4@1+ (1,0) [0|15] "" Vector__XXX
 SG_ FromPort : 12|4@1+ (1,0) [0|15] "" Vector__XXX

BO_ 2565130272 RGE11: 8 BCM
 SG_ AuxiliaryEquipmentSupplyPressure : 48|8@1+ (8,0) [0|2000] "kPa" Vector__XXX
 SG_ ParkingAndTrailerAirPress : 40|8@1+ (8,0) [0|2000] "kPa" Vector__XXX
 SG_ DrivenAxleLoad : 24|16@1+ (2,0) [0|128510] "kg" Vector__XXX
 SG_ StopLevelChangeReq : 20|2@1+ (1,0) [0|3] "" Vector__XXX
 SG_ RampLevelStorageReq : 18|2@1+ (1,0) [0|3] "" Vector__XXX
 SG_ LevelControlReq : 16|2@1+ (1,0) [0|3] "" Vector__XXX
 SG_ RampLevelReq : 14|2@1+ (1,0) [0|3] "" Vector__XXX
 SG_ SteeringAxleLockingReq : 12|2@1+ (1,0) [0|3] "" Vector__XXX
 SG_ LiftAxle2PositionReq : 10|2@1+ (1,0) [0|3] "" Vector__XXX
 SG_ LiftAxle1PositionReq : 8|2@1+ (1,0) [0|3] "" Vector__XXX
 SG_ TractionHelpReq : 6|2@1+ (1,0) [0|3] "" Vector__XXX
 SG_ LevelChangeReqRearAxle : 4|2@1+ (1,0) [0|3] "" Vector__XXX
 SG_ LevelChangeReqFrontAxle : 2|2@1+ (1,0) [0|3] "" Vector__XXX
 SG_ RideHeightRequest_RGE11 : 0|1@1+ (1,0) [0|1] "" Vector__XXX

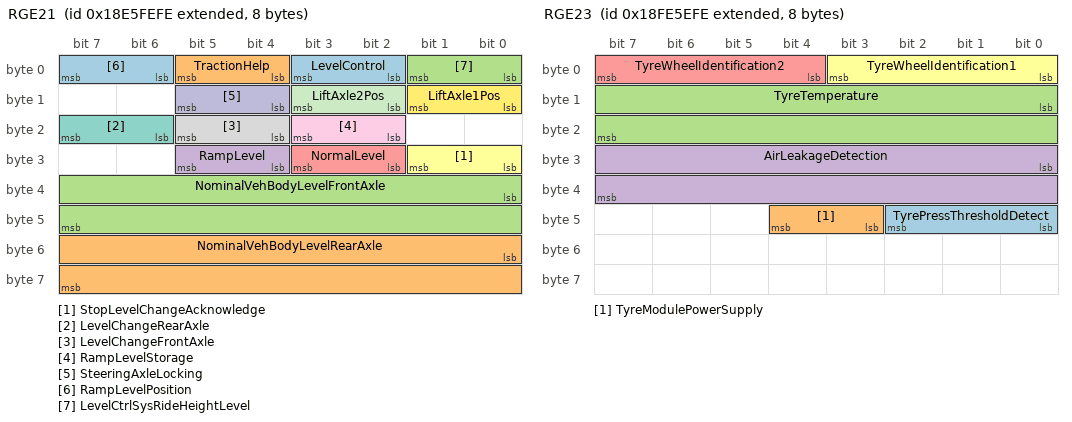
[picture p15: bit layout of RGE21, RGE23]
BO_ 2565209854 RGE21: 8 Vector__XXX
 SG_ LevelControl : 2|2@1+ (1,0) [0|1] "" Vector__XXX
 SG_ NominalVehBodyLevelRearAxle : 48|16@1+ (1,0) [0|64255] "mm" Vector__XXX
 SG_ NominalVehBodyLevelFrontAxle : 32|16@1+ (1,0) [0|64255] "mm" Vector__XXX
 SG_ RampLevel : 28|2@1+ (1,0) [0|1] "" Vector__XXX
 SG_ NormalLevel : 26|2@1+ (1,0) [0|3] "" Vector__XXX
 SG_ StopLevelChangeAcknowledge : 24|2@1+ (1,0) [0|1] "" Vector__XXX
 SG_ LevelChangeRearAxle : 22|2@1+ (1,0) [0|1] "" Vector__XXX
 SG_ LevelChangeFrontAxle : 20|2@1+ (1,0) [0|1] "" Vector__XXX
 SG_ RampLevelStorage : 18|2@1+ (1,0) [0|1] "" Vector__XXX
 SG_ SteeringAxleLocking : 12|2@1+ (1,0) [0|3] "" Vector__XXX
 SG_ LiftAxle2Pos : 10|2@1+ (1,0) [0|3] "" Vector__XXX
 SG_ LiftAxle1Pos : 8|2@1+ (1,0) [0|3] "" Vector__XXX
 SG_ RampLevelPosition : 6|2@1+ (1,0) [0|3] "" Vector__XXX
 SG_ TractionHelp : 4|2@1+ (1,0) [0|1] "" Vector__XXX
 SG_ LevelCtrlSysRideHeightLevel : 0|2@1+ (1,0) [0|1] "" Vector__XXX

BO_ 2566806782 RGE22: 8 Vector__XXX
 SG_ RelVehBodyLevelRearAxle : 16|16@1+ (1,0) [0|64255] "mm" Vector__XXX
 SG_ RelVehBodyLevelFrontAxle : 0|16@1+ (1,-32000) [-32000|32255] "mm" Vector__XXX

BO_ 2566807294 RGE23: 8 Vector__XXX
 SG_ TyrePressThresholdDetect : 40|3@1+ (1,0) [0|7] "" Vector__XXX
 SG_ TyreModulePowerSupply : 43|2@1+ (1,0) [0|1] "" Vector__XXX
 SG_ TyreTemperature : 8|16@1+ (0.03125,-273) [-273|1735] "°C" Vector__XXX
 SG_ AirLeakageDetection : 24|16@1+ (0.1,0) [0|6425.5] "Pa/s" Vector__XXX
 SG_ TyreWheelIdentification2 : 4|4@1+ (1,0) [0|15] "" Vector__XXX
 SG_ TyreWheelIdentification1 : 0|4@1+ (1,0) [0|15] "" Vector__XXX

BO_ 2566764798 DM26: 8 Vector__XXX
 SG_ NMHCConvertingCatalystCompleted : 60|1@1+ (1,0) [0|1] "" Vector__XXX
 SG_ NMHCConvertingCatalystEnabled : 44|1@1+ (1,0) [0|1] "" Vector__XXX
 SG_ NOxConvertingCatalystAdsorberCom : 59|1@1+ (1,0) [0|1] "" Vector__XXX
 SG_ NOxConvertingCatalystAdsorberEna : 43|1@1+ (1,0) [0|1] "" Vector__XXX
 SG_ DieselParticulateFilterCompleted : 58|1@1+ (1,0) [0|1] "" Vector__XXX
 SG_ DieselParticulateFilterEnabled : 42|1@1+ (1,0) [0|1] "" Vector__XXX
 SG_ BoostPressureControlSystemComple : 57|1@1+ (1,0) [0|1] "" Vector__XXX
 SG_ BoostPressureCtrlSystemEnabled : 41|1@1+ (1,0) [0|1] "" Vector__XXX
 SG_ MisfireMonitoringComplete : 28|1@1+ (1,0) [0|1] "" Vector__XXX
 SG_ MisfireMonitoringEnabled : 24|1@1+ (1,0) [0|0] "" Vector__XXX
 SG_ FuelSystemMonitoringEnabled : 25|1@1+ (1,0) [0|1] "" Vector__XXX
 SG_ ComprehensiveComptMonComplete : 30|1@1+ (1,0) [0|1] "" Vector__XXX
 SG_ ComprehensiveCompMonEnabled : 26|1@1+ (1,0) [0|1] "" Vector__XXX
 SG_ SecondAirSystemMonComplete : 51|1@1+ (1,0) [0|1] "" Vector__XXX
 SG_ SecondAirSystemMonEnabled : 35|1@1+ (1,0) [0|1] "" Vector__XXX
 SG_ OxygenSensorMonComplete : 53|1@1+ (1,0) [0|1] "" Vector__XXX
 SG_ OxygenSensorMonEnabled : 37|1@1+ (1,0) [0|1] "" Vector__XXX
 SG_ OxygenSensorHeaterMonComplete : 54|1@1+ (1,0) [0|1] "" Vector__XXX
 SG_ OxygenSensorHeaterMonEnabled : 38|1@1+ (1,0) [0|1] "" Vector__XXX
 SG_ HeatedCatalystMonComplete : 49|1@1+ (1,0) [0|1] "" Vector__XXX
 SG_ HeatedCatalystMonEnabled : 33|1@1+ (1,0) [0|1] "" Vector__XXX
 SG_ EvaporativeSystemMonComplete : 50|1@1+ (1,0) [0|1] "" Vector__XXX
 SG_ EvaporativeSystemMonEnabled : 34|1@1+ (1,0) [0|1] "" Vector__XXX
 SG_ EGRSystemMonitoringComplete : 55|1@1+ (1,0) [0|1] "" Vector__XXX
 SG_ EGRSystemMonitoringEnabled : 39|1@1+ (1,0) [0|1] "" Vector__XXX
 SG_ ColdStartAidSystemMonComplete : 56|1@1+ (1,0) [0|1] "" Vector__XXX
 SG_ ColdStartAidSystemMonEnabled : 40|1@1+ (1,0) [0|1] "" Vector__XXX
 SG_ CatalystMonComplete : 48|1@1+ (1,0) [0|1] "" Vector__XXX
 SG_ CatalystMonEnabled : 32|1@1+ (1,0) [0|1] "" Vector__XXX
 SG_ ACSystemRefrigerantMonComplete : 52|1@1+ (1,0) [0|1] "" Vector__XXX
 SG_ ACSystemRefrigerantMonEnabled : 36|1@1+ (1,0) [0|1] "" Vector__XXX
 SG_ FuelSystemMonitoringComplete : 29|1@1+ (1,0) [0|1] "" Vector__XXX
 SG_ NumOfWarmUpsSinceDTCsCleared : 16|8@1+ (1,0) [0|250] "" Vector__XXX
 SG_ TimeSinceEngineStart : 0|16@1+ (1,0) [0|64255] "sec" Vector__XXX

BO_ 2564095742 DM18: 8 Vector__XXX
 SG_ SecurityEntityLengthHigh : 12|4@1+ (1,0) [0|255] "Byte" Vector__XXX
 SG_ SecurityEntityType : 8|4@1+ (1,0) [0|15] "" Vector__XXX
 SG_ SecurityEntityLength : 0|8@1+ (1,0) [0|1785] "Byte" Vector__XXX

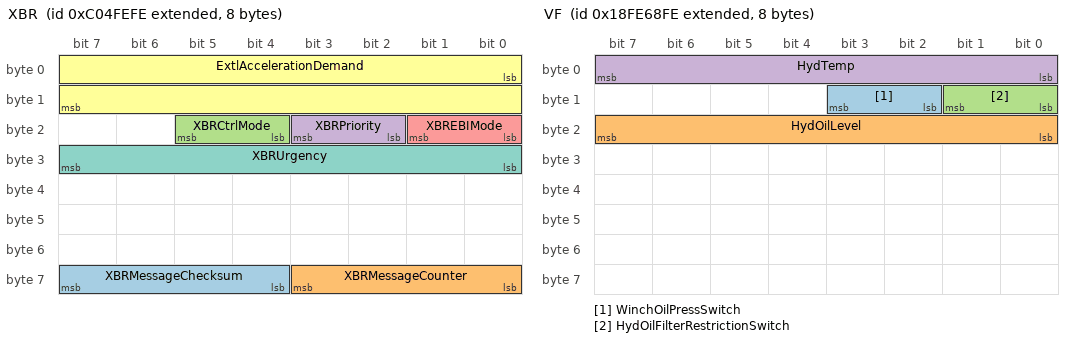
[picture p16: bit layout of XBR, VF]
BO_ 2349137662 XBR: 8 Vector__XXX
 SG_ XBRMessageChecksum : 60|4@1+ (1,0) [0|15] "" Vector__XXX
 SG_ XBRMessageCounter : 56|4@1+ (1,0) [0|15] "" Vector__XXX
 SG_ XBRCtrlMode : 20|2@1+ (1,0) [0|3] "" Vector__XXX
 SG_ XBRPriority : 18|2@1+ (1,0) [0|3] "" Vector__XXX
 SG_ XBREBIMode : 16|2@1+ (1,0) [0|3] "" Vector__XXX
 SG_ ExtlAccelerationDemand : 0|16@1+ (0.00048828125,-15.687) [-15.687|15.687] "m/s²" Vector__XXX
 SG_ XBRUrgency : 24|8@1+ (0.4,0) [0|100] "%" Vector__XXX

BO_ 2566848510 WFI: 8 Vector__XXX
 SG_ WaterInFuelIndicator : 0|2@1+ (1,0) [0|3] "" Vector__XXX

BO_ 2566842927 VW_BCM_ECAS: 8 BCM
 SG_ AxleLocation M : 0|8@1+ (1,0) [0|255] ""  PCCM,EBS,INSTRUMENT_CLUSTER
 SG_ CargoWeight_30 m48 : 40|16@1+ (2,0) [0|128510] "kg"  PCCM,EBS,INSTRUMENT_CLUSTER
 SG_ CargoWeight_20 m32 : 40|16@1+ (2,0) [0|128510] "kg"  PCCM,EBS,INSTRUMENT_CLUSTER
 SG_ CargoWeight_10 m16 : 40|16@1+ (2,0) [0|128510] "kg"  PCCM,EBS,INSTRUMENT_CLUSTER
 SG_ CargoWeight_00 m0 : 40|16@1+ (2,0) [0|128510] "kg"  PCCM,EBS,INSTRUMENT_CLUSTER
 SG_ TrailerWeight_30 m48 : 24|16@1+ (2,0) [0|128510] "kg"  PCCM,EBS,INSTRUMENT_CLUSTER
 SG_ TrailerWeight_20 m32 : 24|16@1+ (2,0) [0|128510] "kg"  PCCM,EBS,INSTRUMENT_CLUSTER
 SG_ TrailerWeight_10 m16 : 24|16@1+ (2,0) [0|128510] "kg"  PCCM,EBS,INSTRUMENT_CLUSTER
 SG_ TrailerWeight_00 m0 : 24|16@1+ (2,0) [0|128510] "kg"  PCCM,EBS,INSTRUMENT_CLUSTER
 SG_ AxleWeight_00 : 8|16@1+ (0.5,0) [0|32127.5] "kg"  PCCM,EBS,INSTRUMENT_CLUSTER

BO_ 2566804222 VEP3: 8 Vector__XXX
 SG_ NetBatteryCurrentHiRes : 16|16@1+ (0.05,-1600) [-1600|1612.75] "A" Vector__XXX
 SG_ AltCurrentHiRes : 0|16@1+ (0.05,-1600) [-1600|1676.75] "A" Vector__XXX

BO_ 2633928190 VEP2: 8 Vector__XXX
 SG_ ECUPowerOutputSupplyVoltage3 : 48|16@1+ (0.05,0) [0|3212.75] "V" Vector__XXX
 SG_ ECUPowerOutputSupplyVoltage2 : 32|16@1+ (0.05,0) [0|3212.75] "V" Vector__XXX
 SG_ ECUPowerOutputSupplyVoltage1 : 16|16@1+ (0.05,0) [0|3212.75] "V" Vector__XXX
 SG_ BatteryPotential_PowerInput2 : 0|16@1+ (0.05,0) [0|3212.75] "V" Vector__XXX

BO_ 2566845438 VP: 8 Vector__XXX
 SG_ Longitude : 32|32@1+ (10,-210) [-210|211.1008122] "deg" Vector__XXX
 SG_ Latitude : 0|32@1+ (10,-210) [-210|211.1008122] "deg" Vector__XXX

BO_ 2566843646 VI: 8 Vector__XXX
 SG_ VehicleIdentificationNumber : 0|8@1+ (1,0) [0|255] "" Vector__XXX

BO_ 2566842112 VH: 8 ENGINE_CONTROL_MODULE
 SG_ TotalPowerTakeoffHours : 32|32@1+ (0.05,0) [0|210554060.75] "hr"  PCCM
 SG_ TotalVehicleHours : 0|32@1+ (0.05,0) [0|210554060.75] "hr"  PCCM

BO_ 2566809854 VF: 8 Vector__XXX
 SG_ WinchOilPressSwitch : 10|2@1+ (1,0) [0|3] "" Vector__XXX
 SG_ HydOilLevel : 16|8@1+ (0.4,0) [0|100] "%" Vector__XXX
 SG_ HydOilFilterRestrictionSwitch : 8|2@1+ (1,0) [0|3] "" Vector__XXX
 SG_ HydTemp : 0|8@1+ (1,-40) [-40|210] "deg C" Vector__XXX

BO_ 2566842622 VDS: 8 Vector__XXX
 SG_ Altitude : 48|16@1+ (0.125,-2500) [-2500|5531.875] "m" Vector__XXX
 SG_ Pitch : 32|16@1+ (0.0078125,-200) [-200|301.99] "deg" Vector__XXX
 SG_ NavigationBasedVehicleSpeed : 16|16@1+ (0.00390625,0) [0|250.996] "km/h" Vector__XXX
 SG_ CompassBearing : 0|16@1+ (0.0078125,0) [0|501.99] "deg" Vector__XXX

BO_ 2566832638 VDHR: 8 Vector__XXX
 SG_ HighResolutionTripDistance : 32|32@1+ (5,0) [0|1410065403] "km" Vector__XXX
 SG_ HghRslutionTotalVehicleDistance : 0|32@1+ (5,0) [0|1410065403] "km" Vector__XXX

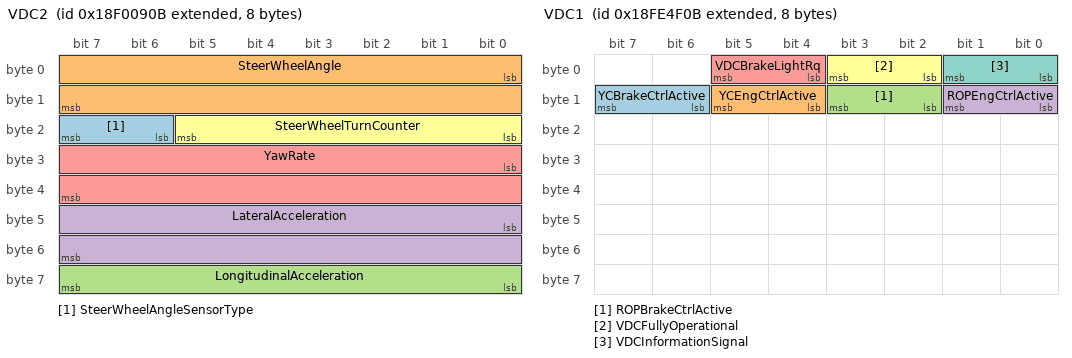
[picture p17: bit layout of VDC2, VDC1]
BO_ 2565867787 VDC2: 8 EBS
 SG_ SteerWheelAngleSensorType : 22|2@1+ (1,0) [0|3] ""  ENGINE_CONTROL_MODULE,PCCM,CAMERA,RADAR,BCM
 SG_ SteerWheelAngle : 0|16@1+ (0.0009765625,-31.374) [-31.374|31.374] "rad"  ENGINE_CONTROL_MODULE,PCCM,CAMERA,RADAR,BCM
 SG_ LongitudinalAcceleration : 56|8@1+ (0.1,-12.5) [-12.5|12.5] "m/s²"  ENGINE_CONTROL_MODULE,PCCM,CAMERA,RADAR,BCM
 SG_ LateralAcceleration : 40|16@1+ (0.00048828125,-15.687) [-15.687|15.687] "m/s²"  ENGINE_CONTROL_MODULE,PCCM,CAMERA,RADAR,BCM
 SG_ YawRate : 24|16@1+ (0.0001220703125,-3.92) [-3.92|3.92] "rad/s"  ENGINE_CONTROL_MODULE,PCCM,CAMERA,RADAR,BCM
 SG_ SteerWheelTurnCounter : 16|6@1+ (1,-32) [-32|29] "turns"  ENGINE_CONTROL_MODULE,PCCM,CAMERA,RADAR,BCM

BO_ 2566803211 VDC1: 8 EBS
 SG_ YCBrakeCtrlActive : 14|2@1+ (1,0) [0|3] ""  ENGINE_CONTROL_MODULE,PCCM,TRANSMISSION,RADAR,INSTRUMENT_CLUSTER
 SG_ YCEngCtrlActive : 12|2@1+ (1,0) [0|3] ""  ENGINE_CONTROL_MODULE,PCCM,TRANSMISSION,RADAR,INSTRUMENT_CLUSTER
 SG_ ROPBrakeCtrlActive : 10|2@1+ (1,0) [0|3] ""  ENGINE_CONTROL_MODULE,PCCM,TRANSMISSION,RADAR,INSTRUMENT_CLUSTER
 SG_ ROPEngCtrlActive : 8|2@1+ (1,0) [0|3] ""  ENGINE_CONTROL_MODULE,PCCM,TRANSMISSION,RADAR,INSTRUMENT_CLUSTER
 SG_ VDCBrakeLightRq : 4|2@1+ (1,0) [0|3] ""  ENGINE_CONTROL_MODULE,PCCM,TRANSMISSION,RADAR,INSTRUMENT_CLUSTER
 SG_ VDCFullyOperational : 2|2@1+ (1,0) [0|3] ""  ENGINE_CONTROL_MODULE,PCCM,TRANSMISSION,RADAR,INSTRUMENT_CLUSTER
 SG_ VDCInformationSignal : 0|2@1+ (1,0) [0|3] ""  ENGINE_CONTROL_MODULE,PCCM,TRANSMISSION,RADAR,INSTRUMENT_CLUSTER

BO_ 2566840574 VD: 8 Vector__XXX
 SG_ TotalVehicleDistance : 32|32@1+ (0.125,0) [0|526385151.9] "km" Vector__XXX
 SG_ TripDistance : 0|32@1+ (0.125,0) [0|526385151.9] "km" Vector__XXX

BO_ 2633938686 TVI: 8 Vector__XXX
 SG_ TripCruiseDistance : 16|32@1+ (0.125,0) [0|526385151.9] "km" Vector__XXX
 SG_ TripMaxVehicleSpeed : 0|16@1+ (0.00390625,0) [0|250.996] "km/h" Vector__XXX

BO_ 2633937150 TTI2: 20 Vector__XXX
 SG_ TripAirCompressorOnTime : 128|32@1+ (0.05,0) [0|210554060.75] "hr" Vector__XXX
 SG_ TripIdleTime : 96|32@1+ (0.05,0) [0|210554060.75] "hr" Vector__XXX
 SG_ TripEngRunningTime : 64|32@1+ (0.05,0) [0|210554060.75] "hr" Vector__XXX
 SG_ TripCruiseTime : 0|32@1+ (0.05,0) [0|210554060.75] "hr" Vector__XXX
 SG_ TripPTOGovernorTime : 32|32@1+ (0.05,0) [0|210554060.75] "hr" Vector__XXX

BO_ 2633938174 TTI1: 16 Vector__XXX
 SG_ TripTimeInDerateByEng : 96|32@1+ (0.05,0) [0|210554060.75] "hr" Vector__XXX
 SG_ TripTimeInGearDown : 64|32@1+ (0.05,0) [0|210554060.75] "hr" Vector__XXX
 SG_ TripTimeInTopGear : 32|32@1+ (0.05,0) [0|210554060.75] "hr" Vector__XXX
 SG_ TripTimeInVSL : 0|32@1+ (0.05,0) [0|210554060.75] "hr" Vector__XXX

BO_ 2633938430 TSI: 8 Vector__XXX
 SG_ TripSuddenDecelerations : 48|16@1+ (1,0) [0|64255] "counts" Vector__XXX
 SG_ TrpNmberOfIdleShutdownOverrides : 32|16@1+ (1,0) [0|64255] "counts" Vector__XXX
 SG_ TripNumberOfIdleShutdowns : 16|16@1+ (1,0) [0|64255] "counts" Vector__XXX
 SG_ TripNumberOfHotShutdowns : 0|16@1+ (1,0) [0|64255] "counts" Vector__XXX

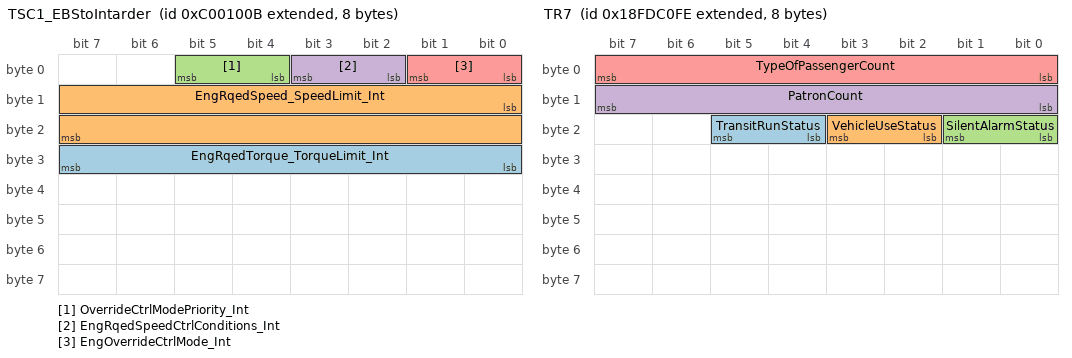
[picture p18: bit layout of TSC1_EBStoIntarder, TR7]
BO_ 2348814347 TSC1_EBStoIntarder: 8 EBS
 SG_ EngRqedTorque_TorqueLimit_Int : 24|8@1+ (1,-125) [-125|125] "%"  PCCM,INTARDER
 SG_ EngRqedSpeed_SpeedLimit_Int : 8|16@1+ (0.125,0) [0|8031.875] "rpm"  PCCM,INTARDER
 SG_ OverrideCtrlModePriority_Int : 4|2@1+ (1,0) [0|3] ""  PCCM,INTARDER
 SG_ EngRqedSpeedCtrlConditions_Int : 2|2@1+ (1,0) [0|3] ""  PCCM,INTARDER
 SG_ EngOverrideCtrlMode_Int : 0|2@1+ (1,0) [0|3] ""  PCCM,INTARDER

BO_ 2566766846 TR7: 8 Vector__XXX
 SG_ TransitRunStatus : 20|2@1+ (1,0) [0|3] "" Vector__XXX
 SG_ VehicleUseStatus : 18|2@1+ (1,0) [0|3] "" Vector__XXX
 SG_ SilentAlarmStatus : 16|2@1+ (1,0) [0|3] "" Vector__XXX
 SG_ PatronCount : 8|8@1+ (1,0) [0|250] "" Vector__XXX
 SG_ TypeOfPassengerCount : 0|8@1+ (1,0) [0|255] "" Vector__XXX

BO_ 2566765310 TR6: 8 Vector__XXX
 SG_ FareboxAlarmIdentifier : 8|7@1+ (1,0) [0|127] "" Vector__XXX
 SG_ FareboxEmergencyStatus : 0|2@1+ (1,0) [0|3] "" Vector__XXX

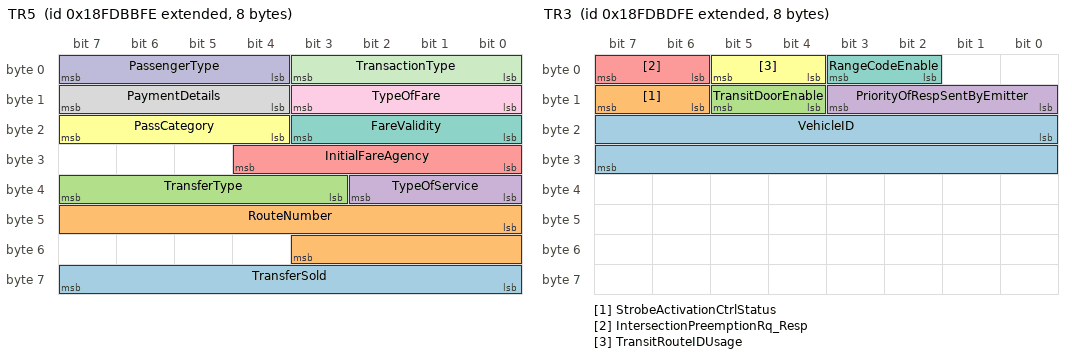
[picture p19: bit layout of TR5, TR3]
BO_ 2566765566 TR5: 8 Vector__XXX
 SG_ TransferSold : 56|8@1+ (1,0) [0|255] "" Vector__XXX
 SG_ RouteNumber : 40|12@1+ (1,0) [0|4095] "" Vector__XXX
 SG_ TransferType : 35|5@1+ (1,0) [0|31] "" Vector__XXX
 SG_ TypeOfService : 32|3@1+ (1,0) [0|7] "" Vector__XXX
 SG_ InitialFareAgency : 24|5@1+ (1,0) [0|31] "" Vector__XXX
 SG_ PassCategory : 20|4@1+ (1,0) [0|15] "" Vector__XXX
 SG_ FareValidity : 16|4@1+ (1,0) [0|15] "" Vector__XXX
 SG_ PaymentDetails : 12|4@1+ (1,0) [0|15] "" Vector__XXX
 SG_ TypeOfFare : 8|4@1+ (1,0) [0|15] "" Vector__XXX
 SG_ PassengerType : 4|4@1+ (1,0) [0|15] "" Vector__XXX
 SG_ TransactionType : 0|4@1+ (1,0) [0|15] "" Vector__XXX

BO_ 2566765822 TR4: 15 Vector__XXX
 SG_ DriversFareboxSecurityCode : 104|16@1+ (1,0) [0|65535] "counts" Vector__XXX
 SG_ AssignedBlock : 88|16@1+ (1,0) [0|65535] "counts" Vector__XXX
 SG_ AssignedRun : 72|16@1+ (1,0) [0|65535] "counts" Vector__XXX
 SG_ AssignedRoute : 56|16@1+ (1,0) [0|65535] "counts" Vector__XXX
 SG_ PatternNumber : 40|16@1+ (1,0) [0|65535] "counts" Vector__XXX
 SG_ TripNumber : 24|16@1+ (1,0) [0|65535] "counts" Vector__XXX
 SG_ FarePresets : 16|8@1+ (1,0) [0|255] "" Vector__XXX
 SG_ TripDirection : 8|4@1+ (1,0) [0|15] "" Vector__XXX
 SG_ TripStatus : 2|3@1+ (1,0) [0|7] "" Vector__XXX
 SG_ FareboxServiceStatus : 0|2@1+ (1,0) [0|3] "" Vector__XXX

BO_ 2566766078 TR3: 8 Vector__XXX
 SG_ VehicleID : 16|16@1+ (1,0) [0|65535] "counts" Vector__XXX
 SG_ StrobeActivationCtrlStatus : 14|2@1+ (1,0) [0|3] "" Vector__XXX
 SG_ TransitDoorEnable : 12|2@1+ (1,0) [0|3] "" Vector__XXX
 SG_ PriorityOfRespSentByEmitter : 8|4@1+ (1,0) [0|15] "" Vector__XXX
 SG_ IntersectionPreemptionRq_Resp : 6|2@1+ (1,0) [0|3] "" Vector__XXX
 SG_ TransitRouteIDUsage : 4|2@1+ (1,0) [0|3] "" Vector__XXX
 SG_ RangeCodeEnable : 2|2@1+ (1,0) [0|3] "" Vector__XXX

BO_ 2566766590 TR2: 8 Vector__XXX
 SG_ NmbrOfBytsInMlpstIdentification : 0|8@1+ (1,0) [0|250] "" Vector__XXX

CM_ BO_ 2566770942 "Intake/Exhaust Conditions 2";
CM_ SG_ 2566770942 EngAirFilter4DiffPress "Change in engine air system pressure, measured across the fourth air filter, due to the filter and any accumulation of solid";
CM_ SG_ 2566770942 EngAirFilter3DiffPress "Change in engine air system pressure, measured across the third air filter, due to the filter and any accumulation of solid";
CM_ SG_ 2566770942 EngAirFilter2DiffPress "Change in engine air system pressure, measured across the second air filter, due to the filter and any accumulation of";
CM_ SG_ 2566770942 EngIntakeManifold1AbsPress "The absolute pressure measurement of the air intake manifold.The absolute pressure measurement of the air intake manifold.";
CM_ SG_ 2566770942 EngIntakeManifold2AbsPress "The absolute pressure measurement of the air intake manifold for bank 2 or the second air intake manifold.";
CM_ SG_ 2566770942 EngIntakeManifold2Press "The gage pressure measurement of the air intake manifold for bank #2 or the second air intake manifold.";
CM_ SG_ 2566770942 EngIntakeManifold1AbsPressHiRes "The absolute pressure measurement of the air intake manifold.The absolute pressure measurement of the air intake manifold.";
CM_ BO_ 2566845952 "Intake/Exhaust Conditions 1";
CM_ SG_ 2566845952 EngCoolantFilterDiffPress "Change in coolant pressure, measured across the filter, due to the filter and any accumulation of solid or semisolid matter";
CM_ SG_ 2566845952 EngExhaustGasTemp "Temperature of combustion byproducts leaving the engine.";
CM_ SG_ 2566845952 EngAirFilter1DiffPress "Change in engine air system pressure, measured across the filter, due to the filter and any accumulation of solid foreign";
CM_ SG_ 2566845952 EngIntakeManifold1Temp "Temperature of pre-combustion air found in intake manifold of engine air supply system.";
CM_ SG_ 2566845952 EngBoostPressure "The gage pressure measurement of the air intake manifold.";
CM_ SG_ 2566845952 EngPrtcltTrpInletPressure "Exhaust back pressure as a result of particle accumulation on filter media placed in the exhaust stream.";
CM_ SG_ 2566845952 EngAirInletPressure "Absolute air pressure at input port to intake manifold or air box.";
CM_ BO_ 2566811134 "Heater Information";
CM_ SG_ 2566811134 CabHeatingZone "Parameter indicating whether the cab zone is being heated.";
CM_ SG_ 2566811134 EngHeatingZone "Parameter indicating whether the engine zone is being heated.";
CM_ SG_ 2566811134 CabVentilation "Indicates whether the cab is being ventilated or not.";
CM_ SG_ 2566811134 AuxHeaterOutputPowerPercent "Current auxiliary heater output power, relative to the auxiliary heater maximum output power.";
CM_ SG_ 2566811134 AuxHeaterInputAirTemp "Temperature of the input air in an auxiliary heater system.";
CM_ SG_ 2566811134 AuxHeaterOutputCoolantTemp "Temperature of the auxiliary heater output coolant (I.";
CM_ SG_ 2566811134 AuxHeaterWaterPumpStatus "Parameter indicating whether the auxiliary heater water pump is running";
CM_ BO_ 2298375934 "High Resolution Wheel Speed";
CM_ SG_ 2298375934 RearAxleRightWheelSpeed "High resolution measurement of the speed of the right wheel on the rear axle.";
CM_ SG_ 2298375934 RearAxleLeftWheelSpeed "High resolution measurement of the speed of the left wheel on the rear axle.";
CM_ SG_ 2298375934 FrontAxleRightWheelSpeed "High resolution measurement of the speed of the right wheel on the front axle.";
CM_ SG_ 2298375934 FrontAxleLeftWheelSpeed "High resolution measurement of the speed of the left wheel on the front axle.";
CM_ BO_ 2565867774 "Hydraulic Pressure Governor Info";
CM_ SG_ 2565867774 FireApparatusPumpEngagement "The measured status of the pump used to provide water in fire fighting apparatus for distribution of water through water";
CM_ SG_ 2565867774 EngHydPressGovernorSwitch "Switch that sets the mode of hydraulic governor";
CM_ SG_ 2565867774 EngHydPrssGovernorModeIndicator "Mode for governor operation is hydraulic pressure control.";
CM_ SG_ 2565867774 HydPress "Hydraulic pressure measured at the output of the hydraulic pump.";
CM_ BO_ 2566841600 "Engine Hours, Revolutions";
CM_ SG_ 2566841600 EngTotalRevolutions "Accumulated number of revolutions of engine crankshaft during its operation.";
CM_ SG_ 2566841600 EngTotalHoursOfOperation "Accumulated time of operation of engine.";
CM_ BO_ 2365449982 "Hydraulic Braking System";
CM_ SG_ 2365449982 HydBrakeFluidLevelSwitch "Signal which indicates whether the hydraulic fluid level in the reservoir(s) is sufficient.";
CM_ SG_ 2365449982 HydBrakeSystemAudibleWarningCmd "Signal which commands an audible warning by the hydraulic braking system.";
CM_ SG_ 2365449982 HydBrkePressSupplyStateCircuit2 "Signal which indicates whether the hydraulic brake pressure supply of circuit 2 is reliable; that is, able to support";
CM_ SG_ 2365449982 HydBrkePressSupplyStateCircuit1 "Signal which indicates whether the hydraulic brake pressure supply of circuit 1 is reliable; that is, able to support";
CM_ SG_ 2365449982 HydBrkPressWarningStateCircuit2 "Signal which indicates whether the hydraulic brake pressure of circuit 2 is below the warning level";
CM_ SG_ 2365449982 HydBrkPressWarningStateCircuit1 "Signal which indicates whether the hydraulic brake pressure of circuit 1 is below the warning level";
CM_ SG_ 2365449982 HydBrakePressCircuit2 "Gage hydraulic pressure in circuit 2 of the hydraulic brake system";
CM_ SG_ 2365449982 HydBrakePressCircuit1 "Gage hydraulic pressure in circuit 1 of the hydraulic brake system";
CM_ BO_ 2633939198 "Trip Fuel Information (Gaseous)";
CM_ SG_ 2633939198 TripDriveFuelEconomy "Trip drive fuel economy is equal to the distance traveled by vehicle in the drive state (engine speed greater than zero,";
CM_ SG_ 2633939198 TrpPTOGovernorNonmovingFuelUsed "Total fuel consumed while the PTO or remote PTO governors are in the hold state, the engine speed is greater than zero,";
CM_ SG_ 2633939198 TripVehicleIdleFuelUsed "Total fuel consumed while neither the PTO or remote PTO governors are active, the engine speed is greater than zero,";
CM_ SG_ 2633939198 TripCruiseFuelUsed "Total fuel consumed while the engine is in the cruise hold state since the last trip reset.";
CM_ SG_ 2633939198 TripDriveFuelUsed "Total fuel consumed while the engine speed is greater than zero, vehicle speed is greater than or equal to 2 km/h, and";
CM_ SG_ 2633939198 TripPTOGovernorMovingFuelUsed "Total fuel consumed while either the PTO or remote PTO governors are in the hold state, the engine speed is greater";
CM_ BO_ 2633927678 "Gaseous Fuel Pressure";
CM_ SG_ 2633927678 EngFuelValve1OutletAbsPress "Absolute Pressure of gas on outlet side of the first or only fuel system control valve.";
CM_ SG_ 2633927678 EngAirToFuelDiffPress "The differential pressure between the gaseous fuel and the air intake manifold.";
CM_ SG_ 2633927678 EngFuelValveDiffPress "The differential pressure between the intake and the outlet of a gaseous fuel valve.";
CM_ SG_ 2633927678 EngFuelValve1IntakeAbsPress "The absolute pressure of gas on the intake side of the first system control valve.";
CM_ BO_ 2633925118 "Fuel Information 2 (Gaseous)";
CM_ SG_ 2633925118 EngFuelFlowRate2 "The rate at which the fuel is flowing through a fuel valve.";
CM_ SG_ 2633925118 EngFuelFlowRate1 "The rate at which the fuel is flowing through a fuel valve.";
CM_ SG_ 2633925118 EngRqedFuelValve2Pos "The requested position of a gaseous fuel valve 2 that is metering the fuel flow to the engine, as requested by the Engine";
CM_ SG_ 2633925118 EngRqedFuelValve1Pos "The requested position of a gaseous fuel valve 1 that is metering the fuel flow to the engine.";
CM_ SG_ 2633925118 EngFuelValve2Pos "The position of a gaseous fuel valve that is metering the fuel flow to the engine.";
CM_ SG_ 2633925118 EngFuelValve1Pos "The position of a gaseous fuel valve that is metering the fuel flow to the engine.";
CM_ BO_ 2633937662 "Fuel Information 1 (Gaseous)";
CM_ SG_ 2633937662 TotalEngPTOGovernorFuelUsed "Total fuel used while the PTO or remote PTO governors are in the hold state and engine speed is above zero, over the";
CM_ SG_ 2633937662 TripAverageFuelRate "Average fuel rate, equal to trip fuel divided by trip time while the engine speed is above zero, since the last trip reset.";
CM_ SG_ 2633937662 EngFuelSpecificGravity "This parameter conveys the specific gravity of the gaseous fuel being used by the engine.";
CM_ BO_ 2566804990 "Gaseous Fuel Properties";
CM_ SG_ 2566804990 SpecificHeatRatio "The specific heat ratio of the fuel.";
CM_ BO_ 2633936894 "Fuel Consumption (Gaseous)";
CM_ SG_ 2633936894 TotalFuelUsed "Total fuel consumed (trip drive fuel + trip PTO moving fuel + trip PTO non-moving fuel + trip idle fuel) over the life of the engine.";
CM_ SG_ 2633936894 TripFuel "Total fuel consumed (trip drive fuel + trip PTO moving fuel + trip PTO non-moving fuel + trip idle fuel) since the last trip reset.";
CM_ BO_ 2566757630 "Sensor Electrical Power #2";
CM_ SG_ 2566757630 SensorSupplyVoltage6 "Sensor ECU supply voltage 6";
CM_ SG_ 2566757630 SensorSupplyVoltage5 "Sensor ECU supply voltage 5";
CM_ SG_ 2566757630 SensorSupplyVoltage8 "Sensor ECU supply voltage 8";
CM_ SG_ 2566757630 SensorSupplyVoltage7 "Sensor ECU supply voltage 7";
CM_ BO_ 2566757886 "Sensor Electrical Power #1";
CM_ SG_ 2566757886 SensorSupplyVoltage4 "Sensor ECU supply voltage 4";
CM_ SG_ 2566757886 SensorSupplyVoltage3 "Sensor ECU supply voltage 3";
CM_ SG_ 2566757886 SensorSupplyVoltage2 "Sensor ECU supply voltage 2";
CM_ SG_ 2566757886 SensorSupplyVoltage1 "Sensor ECU supply voltage 1";
CM_ BO_ 2566759678 "PTO Drive Engagement";
CM_ SG_ 2566759678 EnggmntSttusTransInputShaftPTO1 "Reports if this specific PTO drive is engaged.";
CM_ SG_ 2566759678 EnggmntSttusTransInputShaftPTO2 "Reports if this specific PTO drive is engaged.";
CM_ SG_ 2566759678 EnggmntSttusTransOutputShaftPTO "Reports if this specific PTO drive is engaged.";
CM_ SG_ 2566759678 EnggmntSttsTrnsfrCsOtptShaftPTO "Reports if this specific PTO drive is engaged.";
CM_ SG_ 2566759678 EnggmntCnsntTransInputShaftPTO1 "Status of the transmission controller’s consent to engage the first or sole PTO drive mounted on the transmission case.";
CM_ SG_ 2566759678 EnggmntCnsntTransInputShaftPTO2 "Status of the transmission controller’s consent to engage the second PTO drive mounted on the transmission case.";
CM_ SG_ 2566759678 EnggmntCnsntTransOutputShaftPTO "Status of the transmission controller’s consent to engage the PTO drive connected to the transmission output shaft.";
CM_ SG_ 2566759678 EnggmntCnsntTrnsfrCsOtptShftPTO "Status of the transmission controller’s consent to engage the PTO drive connected to the transfer case output shaft.";
CM_ SG_ 2566759678 EnableSwitchTransInputShaftPTO1 "Status of the operator’s switch or other input which indicates the desire for engaging the first PTO drive mounted on the";
CM_ SG_ 2566759678 EnableSwitchTransInputShaftPTO2 "Status of the operator’s switch or other input which indicates the desire for engaging the second PTO drive mounted on";
CM_ SG_ 2566759678 EnableSwitchTransOutputShaftPTO "Status of the operator’s switch or other input which indicates the desire for engaging the PTO drive mounted on the";
CM_ SG_ 2566759678 EnblSwtchTrnsfrCsOutputShaftPTO "Status of the operator’s switch or other input which indicates the desire for engaging the PTO drive mounted on the output";
CM_ SG_ 2566759678 EnggmntSttsPTOEngAccssoryDrive2 "Engagement status of the PTO engine accessory drive 2";
CM_ SG_ 2566759678 EnggmntSttsPTOEngAccssoryDrive1 "Engagement status of the PTO engine accessory drive 1";
CM_ SG_ 2566759678 EnggmntCnsntPTOEngAccssryDrive2 "Engagement Consent status for the PTO engine accessory drive 2";
CM_ SG_ 2566759678 EnggmntCnsntPTOEngAccssryDrive1 "Engagement consent status for the PTO engine accessory drive 1";
CM_ SG_ 2566759678 EngagementStatusPTOEngFlywheel "Engagement status of the PTO Engine Flywheel";
CM_ SG_ 2566759678 EngagementConsentPTOEngFlywheel "Engagement Consent status for the PTO Engine Flywheel";
CM_ SG_ 2566759678 EnblSwitchPTOEngAccessoryDrive2 "Status of the PTO engine accessory drive 2 enable switch";
CM_ SG_ 2566759678 EnblSwitchPTOEngAccessoryDrive1 "Status of the PTO engine accessory drive 1 enable switch";
CM_ SG_ 2566759678 EnableSwitchPTOEngFlywheel "Status of the PTO Engine Flywheel enable switch";
CM_ SG_ 2566759678 AtLeastOnePTOEngaged "Indicates that at least one PTO is engaged";
CM_ BO_ 2432541438 "Fuel Information 3 (Gaseous)";
CM_ SG_ 2432541438 EngFuelValve2OutletAbsPress "Absolute pressure of gas on outlet side of the second fuel system control valve.";
CM_ SG_ 2432541438 EngFuelTemp2 "Temperature 2 of fuel (or gas).";
CM_ SG_ 2432541438 EngGas2MassFlowRate "Gas mass flow rate delivered to an engine through its second fuel control system, using standard convention for";
CM_ SG_ 2432541438 EngFuelValve2IntakeAbsPress "Absolute pressure of gas on intake side of the second fuel system control valve, using standard convention for";
CM_ BO_ 2566761214 "Engine Fluid Level/Pressure 4";
CM_ SG_ 2566761214 EngCentrifugalOilFilterSpeed "The speed of a rotating (centrifugal) engine oil filter.";
CM_ SG_ 2566761214 EngCoolantPumpDiffPress "The differential pressure measured across the input and output of the engine coolant pump.";
CM_ SG_ 2566761214 EngChargeAirCooler2IntakePress "Pressure of air at intake to 2nd charge air cooler, from multiple first stage turbochargers being cooled and feeding multiple";
CM_ SG_ 2566761214 EngChargeAirCooler1IntakePress "Pressure of air at intake to 1st or only charge air cooler, from multiple first stage turbochargers being cooled and feeding";
CM_ SG_ 2566761214 EngIntercoolerCoolantLevel "Ratio of volume of liquid found in an engine intercooler cooling system to total engine intercooler cooling system volume.";
CM_ SG_ 2566761214 EngChargeAirCoolerOutletPress "Measures pressure of air at outlet from charge air cooler";
CM_ SG_ 2566761214 EngAftercoolerCoolantLevel "Ratio of aftercooler coolant system volume of liquid to total cooling system volume.";
CM_ BO_ 2432541694 "Electronic Engine Controller 6";
CM_ SG_ 2432541694 EngVrableGeometryTurboActuator1 "Actuator that controls the variable geometry turbocharger geometry.";
CM_ SG_ 2432541694 EngTrbCmprssrBypssActtr1TmpStts "Used to identify the status of the Engine Turbocharger Compresssor Bypass Actuator 1 drive circuitry temperature.";
CM_ SG_ 2432541694 EngTrbCmprssrBypssActtr1PrlmnryF "Used to identify the appplicable J1939-73 FMI detected in the Engine Turbocharger Compressor Bypass Actuator 1 by";
CM_ SG_ 2432541694 EngTrbCmprssrBypassActuator2Cmd "The command to a compressor bypass actuator 2, normalized to percent, where 0% nominally represents fully closed and";
CM_ SG_ 2432541694 EngTrbCmprssrBypassActuator1Pos "Measures the position of the turbocharger compressor bypass actuator, where 0% represents bypass fully closed and";
CM_ SG_ 2432541694 EngTrbCmprssrBypassActuator1Cmd "The command to a compressor bypass actuator, normalized to percent, where 0% nominally represents fully closed and";
CM_ SG_ 2432541694 EngDsrdTrbCmprssrBypssActtr1Pos "The requested position of the Engine Turbocharger Compressor Bypass actuator by the engine ECM, where 0%";
CM_ BO_ 2566759934 "Door Control 2";
CM_ SG_ 2566759934 EnableStatusOfDoor10 "Enable status of bus door 10.";
CM_ SG_ 2566759934 OpenStatusOfDoor10 "Open status of bus door 10";
CM_ SG_ 2566759934 LockStatusOfDoor10 "Lock status of bus door 10";
CM_ SG_ 2566759934 EnableStatusOfDoor9 "Enable status of bus door 9.";
CM_ SG_ 2566759934 OpenStatusOfDoor9 "Open status of bus door 9";
CM_ SG_ 2566759934 LockStatusOfDoor9 "Lock status of bus door 9";
CM_ SG_ 2566759934 EnableStatusOfDoor8 "Enable status of bus door 8.";
CM_ SG_ 2566759934 OpenStatusOfDoor8 "Open status of bus door 8";
CM_ SG_ 2566759934 LockStatusOfDoor8 "Lock status of bus door 8";
CM_ SG_ 2566759934 EnableStatusOfDoor7 "Enable status of bus door 7.";
CM_ SG_ 2566759934 OpenStatusOfDoor7 "Open status of bus door 7";
CM_ SG_ 2566759934 LockStatusOfDoor7 "Lock status of bus door 7";
CM_ SG_ 2566759934 EnableStatusOfDoor6 "Enable status of bus door 6.";
CM_ SG_ 2566759934 OpenStatusOfDoor6 "Open status of bus door 6";
CM_ SG_ 2566759934 LockStatusOfDoor6 "Lock status of bus door 6";
CM_ SG_ 2566759934 EnableStatusOfDoor5 "Enable status of bus door 5.";
CM_ SG_ 2566759934 OpenStatusOfDoor5 "Open status of bus door 5";
CM_ SG_ 2566759934 LockStatusOfDoor5 "Lock status of bus door 5";
CM_ SG_ 2566759934 EnableStatusOfDoor4 "Enable status of bus door 4.";
CM_ SG_ 2566759934 OpenStatusOfDoor4 "Open status of bus door 4";
CM_ SG_ 2566759934 LockStatusOfDoor4 "Lock status of bus door 4";
CM_ SG_ 2566759934 EnableStatusOfDoor3 "Enable status of bus door 3.";
CM_ SG_ 2566759934 OpenStatusOfDoor3 "Open status of bus door 3";
CM_ SG_ 2566759934 LockStatusOfDoor3 "Lock status of bus door 3";
CM_ SG_ 2566759934 EnableStatusOfDoor2 "Enable status of bus door 2.";
CM_ SG_ 2566759934 OpenStatusOfDoor2 "Open status of bus door 2";
CM_ SG_ 2566759934 LockStatusOfDoor2 "Lock status of bus door 2";
CM_ SG_ 2566759934 EnableStatusOfDoor1 "Enable status of bus door 1.";
CM_ SG_ 2566759934 OpenStatusOfDoor1 "Open status of bus door 1";
CM_ SG_ 2566759934 LockStatusOfDoor1 "Lock status of bus door 1";
CM_ BO_ 2566757374 "Aftertreatment 1 SCR Reagent Information";
CM_ SG_ 2566757374 Aftrtrtmnt1SCRCtlystRgntTmp2Prlm "Used to identify the applicable J1939-73 FMI that applies to the most significant failure of the catalyst temperature sensor.";
CM_ SG_ 2566757374 Aftrtrtmnt1SCRCtlystRgntPrprtsPr "Used to identify the applicable J1939-73 FMI that applies to the most significant failure of the catalyst reagent properties";
CM_ SG_ 2566757374 Aftrtrtmnt1SCRCtlystRgntCndctvty "A measure of the conductivity of the reagent or fluid at the sensor.";
CM_ SG_ 2566757374 Aftrtrtmnt1SCRCtlystRgntCncntrtn "A measure of the concentration of urea in water.";
CM_ SG_ 2566757374 Aftrtrtmnt1SCRCtlystReagentType "This parameter indicates what reagent is in the tank.";
CM_ SG_ 2566757374 Aftrtrtmnt1SCRCtlystRagentTemp2 "Temperature of the catalyst reagent at the device measuring reagent quality";
CM_ BO_ 2364546302 "Requested Generator Average Basic AC Quantities";
CM_ SG_ 2364546302 RqdGnrtrAvrgLneLineACRMSVoltage "The requested average AC RMS voltage to be delivered by the generator.";
CM_ BO_ 2431654654 "Engine Throttle / Fuel Actuator Control Command";
CM_ SG_ 2431654654 EngThrottleActuator2CtrlCmd "The control command to throttle actuator 2, normalized to percent, where 0% represents fully closed and 100%";
CM_ SG_ 2431654654 EngThrottleActuator1CtrlCmd "The control command to throttle actuator 1, normalized to percent, where 0% represents fully closed and 100%";
CM_ SG_ 2431654654 EngFuelActuator2CtrlCmd "The control command to fuel actuator 2, normalized to percent, where 0% represents fully closed and 100% represents";
CM_ SG_ 2431654654 EngFuelActuator1CtrlCmd "The control command to fuel actuator 1, normalized to percent, where 0% represents fully closed and 100% represents";
CM_ BO_ 2364545534 "Engine Knock Level #3";
CM_ SG_ 2364545534 EngCyl24KnockLevel "Used to indicate the level of knock for engine cylinder 24.";
CM_ SG_ 2364545534 EngCyl23KnockLevel "Used to indicate the level of knock for engine cylinder 23.";
CM_ SG_ 2364545534 EngCyl22KnockLevel "Used to indicate the level of knock for engine cylinder 22.";
CM_ SG_ 2364545534 EngCyl21KnockLevel "Used to indicate the level of knock for engine cylinder 21.";
CM_ SG_ 2364545534 EngCyl20KnockLevel "Used to indicate the level of knock for engine cylinder 20.";
CM_ SG_ 2364545534 EngCyl19KnockLevel "Used to indicate the level of knock for engine cylinder 19.";
CM_ SG_ 2364545534 EngCyl18KnockLevel "Used to indicate the level of knock for engine cylinder 18.";
CM_ SG_ 2364545534 EngCyl17KnockLevel "Used to indicate the level of knock for engine cylinder 17.";
CM_ BO_ 2364545278 "Engine Knock Level #2";
CM_ SG_ 2364545278 EngCyl15KnockLevel "Used to indicate the level of knock for engine cylinder 15.";
CM_ SG_ 2364545278 EngCyl14KnockLevel "Used to indicate the level of knock for engine cylinder 14.";
CM_ SG_ 2364545278 EngCyl13KnockLevel "Used to indicate the level of knock for engine cylinder 13.";
CM_ SG_ 2364545278 EngCyl12KnockLevel "Used to indicate the level of knock for engine cylinder 12.";
CM_ SG_ 2364545278 EngCyl11KnockLevel "Used to indicate the level of knock for engine cylinder 11.";
CM_ SG_ 2364545278 EngCyl10KnockLevel "Used to indicate the level of knock for engine cylinder 10.";
CM_ SG_ 2364545278 EngCyl9KnockLevel "Used to indicate the level of knock for engine cylinder 9.";
CM_ SG_ 2364545278 EngCyl16KnockLevel "Used to indicate the level of knock for engine cylinder 16.";
CM_ BO_ 2364545022 "Engine Knock Level #1";
CM_ SG_ 2364545022 EngCyl8KnockLevel "Used to indicate the level of knock for engine cylinder 8.";
CM_ SG_ 2364545022 EngCyl7KnockLevel "Used to indicate the level of knock for engine cylinder 7.";
CM_ SG_ 2364545022 EngCyl6KnockLevel "Used to indicate the level of knock for engine cylinder 6.";
CM_ SG_ 2364545022 EngCyl5KnockLevel "Used to indicate the level of knock for engine cylinder 5.";
CM_ SG_ 2364545022 EngCyl4KnockLevel "Used to indicate the level of knock for engine cylinder 4.";
CM_ SG_ 2364545022 EngCyl3KnockLevel "Used to indicate the level of knock for engine cylinder 3.";
CM_ SG_ 2364545022 EngCyl2KnockLevel "Used to indicate the level of knock for engine cylinder 2.";
CM_ SG_ 2364545022 EngCyl1KnockLevel "Used to indicate the level of knock for engine cylinder 1.";
CM_ BO_ 2364544766 "Cylinder Combustion Status";
CM_ SG_ 2364544766 EngCyl9CombustionStatus "This parameter is used to indicate state of combustion in engine cylinder #9";
CM_ SG_ 2364544766 EngCyl8CombustionStatus "This parameter is used to indicate state of combustion in engine cylinder #8";
CM_ SG_ 2364544766 EngCyl7CombustionStatus "This parameter is used to indicate state of combustion in engine cylinder #7";
CM_ SG_ 2364544766 EngCyl6CombustionStatus "This parameter is used to indicate state of combustion in engine cylinder #6";
CM_ SG_ 2364544766 EngCyl5CombustionStatus "This parameter is used to indicate state of combustion in engine cylinder #5";
CM_ SG_ 2364544766 EngCyl4CombustionStatus "This parameter is used to indicate state of combustion in engine cylinder #4";
CM_ SG_ 2364544766 EngCyl3CombustionStatus "This parameter is used to indicate state of combustion in engine cylinder #3";
CM_ SG_ 2364544766 EngCyl2CombustionStatus "This parameter is used to indicate state of combustion in engine cylinder #2";
CM_ SG_ 2364544766 EngCyl24CombustionStatus "This parameter is used to indicate state of combustion in engine cylinder #24";
CM_ SG_ 2364544766 EngCyl23CombustionStatus "This parameter is used to indicate state of combustion in engine cylinder #23";
CM_ SG_ 2364544766 EngCyl22CombustionStatus "This parameter is used to indicate state of combustion in engine cylinder #22";
CM_ SG_ 2364544766 EngCyl21CombustionStatus "This parameter is used to indicate state of combustion in engine cylinder #21";
CM_ SG_ 2364544766 EngCyl20CombustionStatus "This parameter is used to indicate state of combustion in engine cylinder #20";
CM_ SG_ 2364544766 EngCyl1CombustionStatus "This parameter is used to indicate state of combustion in engine cylinder #1";
CM_ SG_ 2364544766 EngCyl19CombustionStatus "This parameter is used to indicate state of combustion in engine cylinder #19";
CM_ SG_ 2364544766 EngCyl18CombustionStatus "This parameter is used to indicate state of combustion in engine cylinder #18";
CM_ SG_ 2364544766 EngCyl17CombustionStatus "This parameter is used to indicate state of combustion in engine cylinder #17";
CM_ SG_ 2364544766 EngCyl16CombustionStatus "This parameter is used to indicate state of combustion in engine cylinder #16";
CM_ SG_ 2364544766 EngCyl15CombustionStatus "This parameter is used to indicate state of combustion in engine cylinder #15";
CM_ SG_ 2364544766 EngCyl14CombustionStatus "This parameter is used to indicate state of combustion in engine cylinder #14";
CM_ SG_ 2364544766 EngCyl13CombustionStatus "This parameter is used to indicate state of combustion in engine cylinder #13";
CM_ SG_ 2364544766 EngCyl12CombustionStatus "This parameter is used to indicate state of combustion in engine cylinder #12";
CM_ SG_ 2364544766 EngCyl11CombustionStatus "This parameter is used to indicate state of combustion in engine cylinder #11";
CM_ SG_ 2364544766 EngCyl10CombustionStatus "This parameter is used to indicate state of combustion in engine cylinder #10";
CM_ BO_ 2364544510 "Requested Generator Total AC Reactive Power";
CM_ SG_ 2364544510 RqGenOverallPowerFactorLagging "The requested lead/lag status for the generator average AC power factor";
CM_ SG_ 2364544510 RqGeneratorOverallPowerFactor "The requested average power factor of the generator.";
CM_ SG_ 2364544510 RqGeneratorTotalACReactivePower "The total reactive power requested to be delivered by the generator";
CM_ BO_ 2364544254 "Blade Information";
CM_ SG_ 2364544254 RltvBldHghtAndBldRttnAnglMsrmntL "The estimated measurement latency of the measurement.";
CM_ SG_ 2364544254 RlativeBladeHeightFigureOfMerit "Figure of merit for blade height measurement.";
CM_ SG_ 2364544254 BladeRotationAngleFigureOfMerit "Figure of merit for blade rotation measurement.";
CM_ SG_ 2364544254 BladeRotationAngle "The blade rotation angle measurement around the yaw (z-axis).";
CM_ SG_ 2364544254 RelativeBladeHeight "The measured vertical distance from a fixed location on the machine blade to a ground-based reference.";
CM_ BO_ 2348992544 "ISO 11992: Towing vehicle message, electronic brake system #1/1";
CM_ SG_ 2348992544 RetarderDemandValue "The demanded value of the retarder on the towed vehicle(s) as a percentage of the absolute peak torque of retarder.";
CM_ SG_ 2348992544 ParkBrakeDemandValue "The requested brake pressure value of the parking brake as a percentage of maximum.";
CM_ SG_ 2348992544 ServiceBrakeDemandValue "The requested brake pressure value of the service brake demanded by the driver.";
CM_ SG_ 2348992544 VehicleType "Information to identify a dolly axle within the road train.";
CM_ SG_ 2348992544 BrakeLightSwitch "Signal which indicates that the brake pedal is being pressed.";
CM_ SG_ 2348992544 ASREngineControlActive "Signal which indicates that ASR engine control is active/passive.";
CM_ SG_ 2348992544 ASRBreakControlActive "Signal which indicates that ASR brake control is active/passive.";
CM_ SG_ 2348992544 VehicleRetarderCtrlActive "This signal indicates the active/passive state in all cases when the installed retarder is applied by the driver’s demand or by other systems (brakes).";
CM_ SG_ 2348992544 VehicleABSActive "Signal indicating the ABS is active/passive.";
CM_ BO_ 2566834464 "ISO 11992: Towing vehicle message, electronic brake system #1/2";
CM_ SG_ 2566834464 RoadCurvature "Estimated value of the current road curvature for use by the adaptive cruise control system.";
CM_ SG_ 2566834464 PneumaticControlLine "Signal which indicates that the towing vehicle has a pneumatic control line for the towed vehicle service braking system";
CM_ SG_ 2566834464 ABSOffroadRequest "Request to activate the ABS off-road function. The switch signal is independent of an actual ABS control situation.";
CM_ SG_ 2566834464 TwoElCircuitsBrakeDemand "Signal which indicates that the service brake demand value sent by the towing vehicle can be generated by one or two independent electrical braking circuit(s).";
CM_ SG_ 2566834464 VehicleRetarderCtrlActive "This signal indicates the active/passive state in all cases when the installed retarder is applied by the driver’s demand or by other systems (brakes).";
CM_ BO_ 2550341832 "ISO 11992: Towed vehicle message, electronic brake system #2/1";
CM_ SG_ 2550341832 WheelSpeedDiffMainAxle "Difference between the wheel speed at the right side and and the left side of the main axle.";
CM_ SG_ 2550341832 ActualRetarderPercTorque "Actual torque of the retarder as negative percentage of maximum.";
CM_ SG_ 2550341832 Wheel_BasedVehicleSpeed "Actual speed of the vehicle (positive value for forward and backward speed) calculated as the average of the wheel speeds of one axle influenced by slip and filtered by a frequency range of 5 Hz to 20 Hz.";
CM_ SG_ 2550341832 SupplyLineBrakingRequest "Signal indicating the trailer is requesting to be braked by the commercial vehicle by means of bleeding the pneumatic supply line.";
CM_ SG_ 2550341832 VDCActive "Signal which indicates that Vehicle Dynamic Control (VDC) is active/passive.";
CM_ SG_ 2550341832 AutomTowedVehBreakActive "Signal indicating the automatic towed vehicle braking is active/passive.";
CM_ SG_ 2550341832 VehicleServiceBrakeActive "Signal indicating the service brake of the towed vehicle is active/passive, by observing the brake pressure.";
CM_ SG_ 2550341832 VehicleRetarderCtrlActive "This signal indicates the active/passive state in all cases when the installed retarder is applied by the driver’s demand or by other systems (brakes).";
CM_ SG_ 2550341832 VehicleABSActive "Signal indicating the ABS is active/passive.";
CM_ BO_ 2566833352 "ISO 11992: Towed vehicle message, electronic brake system #2/2";
CM_ SG_ 2566833352 ReferenceRetarderTorque "This parameter is the 100% reference value for all defined indicated retarder torque parameters.";
CM_ SG_ 2566833352 AxleLoadSum "Sum of the static vertical loads of the vehicle axles.";
CM_ SG_ 2566833352 SupplyLineBrakingRequest "Signal indicating the trailer is requesting to be braked by the commercial vehicle by means of bleeding the pneumatic supply line.";
CM_ SG_ 2566833352 LoadingRampApproachAssist "The parameter indicates whether the loading ramp approach assistance is activated.";
CM_ SG_ 2566833352 SpringBrakeEngaged "Signal indicating the vehicle spring brake is engaged.";
CM_ SG_ 2566833352 ElectrLoadPropFunc "Signal indicating the vehicle is equipped with an electrical load proportional function.";
CM_ SG_ 2566833352 SpringBrakeInstalled "Signal indicating the vehicle has one or more axle(s) fitted with spring brakes.";
CM_ SG_ 2566833352 VehicleType "Information to identify a dolly axle within the road train.";
CM_ SG_ 2566833352 ElecSupplyOfNonBrakingSys "Signal which indicates the status of the supply of non-braking systems.";
CM_ SG_ 2566833352 AmberWarningSignalReq "Request from the towed vehicle to the commercial vehicle to activate the amber warning signal on the commercial vehicle.";
CM_ SG_ 2566833352 RedWarningSignalRequest "Request from the towed vehicle to the commercial vehicle to activate the red warning signal on the commercial vehicle, which indicates certain specified failures within the braking equipment of the towed vehicles.";
CM_ SG_ 2566833352 VehicleElectrSupplySuff "Signal indicating the actual supply voltage is sufficient/insufficient for proper brake function (including over voltage).";
CM_ SG_ 2566833352 AutomTowedVehBreakActive "Signal indicating the automatic towed vehicle braking is active/passive.";
CM_ SG_ 2566833352 VehicleServiceBrakeActive "Signal indicating the service brake of the towed vehicle is active/passive, by observing the brake pressure.";
CM_ SG_ 2566833352 VehicleRetarderCtrlActive "This signal indicates the active/passive state in all cases when the installed retarder is applied by the driver’s demand or by other systems (brakes).";
CM_ SG_ 2566833352 VehicleABSActive "Signal indicating the ABS is active/passive.";
CM_ BO_ 2365507272 "ISO 11992: Towed vehicle message, electronic brake system #2/3";
CM_ SG_ 2365507272 PneumaticSupplyPressure "Actual supply pressure of the reservoir of the braking system.";
CM_ SG_ 2365507272 BrakeTemperature "Actual brake temperature.";
CM_ SG_ 2365507272 BrakeLining "Actual relative value of brake lining of a specific brake.";
CM_ SG_ 2365507272 TyrePressure "Actual tyre pressure without corrections.";
CM_ SG_ 2365507272 TyreWheelIdentTemp2 "Second part of identification number of the tyre or wheel (the number of axles).";
CM_ SG_ 2365507272 TyreWheelIdentTemp1 "First part of identification number of the tyre or wheel (position on each axle).";
CM_ SG_ 2365507272 TyreWheelIdentPressure2 "Second part of identification number of the tyre or wheel (the number of axles).";
CM_ SG_ 2365507272 TyreWheelIdentPressure1 "First part of identification number of the tyre or wheel (position on each axle).";
CM_ SG_ 2365507272 TyreWheelIdentLining2 "Second part of identification number of the tyre or wheel (the number of axles).";
CM_ SG_ 2365507272 TyreWheelIdentLining1 "First part of identification number of the tyre or wheel (position on each axle).";
CM_ SG_ 2365507272 VehiclePneumSupplySuff "Signal indicating the actual supply pressure of the reservoir of the braking system is insufficient or sufficient.";
CM_ SG_ 2365507272 BrakeTemperatureStatus "Signal which indicates that the brake temperature is higher than a specific level.";
CM_ SG_ 2365507272 BrakeLiningSufficient "Signal which indicates that the brake lining is sufficient/insufficient.";
CM_ SG_ 2365507272 TyrePressureSufficient "Signal which indicates that the tyre pressure is insufficient";
CM_ BO_ 2565013246 "ISO 11992: Towing vehicle message, general purpose message #1/1

GPM 11 replaces GFM 11 in ISO 11992:1998 part 3";
CM_ SG_ 2565013246 ODDRequest "Command signal to switch on or off the obstacle detection device (ODD).";
CM_ SG_ 2565013246 AntiTheftDeviceReq "Command signal to activate the anti-theft device.";
CM_ SG_ 2565013246 VehicleType "Information to identify a dolly axle within the road train.";
CM_ BO_ 2566807038 "ISO 11992: Towing vehicle message, general purpose message #1/2";
CM_ SG_ 2566807038 MaxVehicleSpeedLimit "Maximum vehicle velocity allowed.";
CM_ SG_ 2566807038 EngineSpeedUpperLimit "The engine speed which cannot be exceeded.";
CM_ SG_ 2566807038 EngineSpeedLowerLimit "The minimum engine speed which the engine is allowed to reach.";
CM_ BO_ 2365480958 "ISO 11992: Towing vehicle message, general purpose message #1/3";
CM_ SG_ 2365480958 EngineTorqueMode "State signal which indicates which engine torque mode is currently generating, limiting, or controlling the torque";
CM_ SG_ 2365480958 PercentLoadAtCurrentSpeed "The ratio of actual engine percent torque to maximum indicated torque available at the current engine speed, clipped to zero torque during engine braking.";
CM_ SG_ 2365480958 EngineSpeed "Actual engine speed which is calculated over a minimum crankshaft angle of 720 degrees divided by
the number of cylinders.";
CM_ SG_ 2365480958 ActualEngine_PercTorque "The calculated output torque of the engine.";
CM_ SG_ 2365480958 DriversDemandEngine_PercTorque "The torque output of the engine requested by the driver.";
CM_ SG_ 2365480958 EngineRunning "Signal which indicates whether the engine is running.";
CM_ SG_ 2365480958 EngineControlAllowed "Switch signal which indicates that engine control is allowed.";
CM_ BO_ 2566808062 "ISO 11992: Towing vehicle message, general purpose message #1/4";
CM_ SG_ 2566808062 ClutchIndptdPTOFeedback "Signal which indicates the current state of the clutch independent power take off.";
CM_ SG_ 2566808062 AccelPedalPosition "The ratio of actual accelerator pedal position to maximum pedal position.";
CM_ SG_ 2566808062 AccelPedalLowIdleSwitch "Switch signal which indicates whether the accelerator pedal low idle switch is opened or closed.";
CM_ SG_ 2566808062 StarterActive "Signal which indicates whether the starter is in use.";
CM_ SG_ 2566808062 TorqueConvOilTemp "Temperature of the torque converter lubricant.";
CM_ SG_ 2566808062 TorqueConvtOilTempWarning "Signal which indicates that the torque converter oil temperature has reached its warning level.";
CM_ SG_ 2566808062 PTOControlAllowed "Switch signal which indicates that PTO control is allowed.";
CM_ SG_ 2566808062 SecEngineMtdPTOFeedback "Signal which indicates the current state of the second engine mounted power take off.";
CM_ SG_ 2566808062 FirstEngineMtdPTOFeedback "Signal which indicates the current state of the first engine mounted power take off.";
CM_ SG_ 2566808062 SecClutchDptdPTOFeedback "Signal which indicates the current state of the second clutch dependent power take off.";
CM_ SG_ 2566808062 FirstClutchDpdtPTOFeedback "Signal which indicates the current state of the first clutch dependent power take off.";
CM_ SG_ 2566808062 CurrentGear "The gear currently engaged in the transmission or the last gear engaged while the transmission is in process of shifting to the new or selected gear.";
CM_ SG_ 2566808062 PercentClutchSlip "Parameter which represents the ratio of input shaft speed to current engine speed (in percent).";
CM_ BO_ 2566808574 "ISO 11992: Towing vehicle message, general purpose message #1/5";
CM_ SG_ 2566808574 ReferenceEngineTorque "The 100 % reference value for all defined indicated engine torque parameters.";
CM_ SG_ 2566808574 FuelLevelWarning "This signal indicates the decrease of the fuel level to a certain minimum.";
CM_ SG_ 2566808574 EngineOilPressureWarning "Signal which indicates that the engine oil pressure has reached its warning level.";
CM_ SG_ 2566808574 EngineCoolantTempWarning "Signal which indicates that the engine coolant temperature has reached its warning level.";
CM_ SG_ 2566808574 EngineOilPressure "Gauge pressure of the oil in the engine lubrication system as provided by the oil pump.";
CM_ SG_ 2566808574 EngineOilTemperature "Temperature of the engine lubricant.";
CM_ BO_ 2566809086 "ISO 11992: Towing vehicle message, general purpose message #1/6";
CM_ SG_ 2566809086 AmbientAirTemperature "Temperature of air surrounding vehicle.";
CM_ BO_ 2564947710 "ISO 11992: Towed vehicle message, general purpose message #2/1

GPM 21 replaces GFM 21 in ISO 11992:1998 part 3";
CM_ SG_ 2564947710 VehicleType "Information to identify a dolly axle within the road train.";
CM_ BO_ 2566834430 "ISO 11992: Towed vehicle message, general purpose message #2/2

GPM22 replaces GFM 24 in ISO 11992:1998 part 3";
CM_ SG_ 2566834430 BodyPressure "The actual pressure in a body on the towed vehicle.";
CM_ SG_ 2566834430 BodyFluidLevel "The actual fluid level in a body on the towed vehicle.";
CM_ SG_ 2566834430 ThermalBodyTemperature "The actual temperature in a thermal body on the towed vehicle.";
CM_ SG_ 2566834430 RearObstacleDistance "The actual distance between the back of the towed vehicle and any obstacle.";
CM_ SG_ 2566834430 AntiTheftDeviceStatus "Signal which indicates that the anti-theft device is switched on or off.";
CM_ SG_ 2566834430 ODDStatus "Signal which indicates that an obstacle detection device (ODD) is active/inactive.";
CM_ BO_ 2365481214 "ISO 11992: Towed vehicle message, general purpose message #2/3";
CM_ SG_ 2365481214 ReqEngineSpeedUpperLim "The requested engine speed which is not to be exceeded.";
CM_ SG_ 2365481214 ReqEngineSpeedLowerLim "The requested minimum engine speed which the engine is to allow.";
CM_ SG_ 2365481214 ReqEngineTorqueLimit "The requested engine torque that the engine is not allowed to exceed, indicated as a ratio of the reference engine torque.";
CM_ SG_ 2365481214 ReqEngineSpeedLimit "The requested vehicle speed which the vehicle is not allowed to exceed.";
CM_ SG_ 2365481214 ReqEngineSpeed "This is the engine speed which the engine is expected to operate at.";
CM_ BO_ 2566808318 "ISO 11992: Towed vehicle message, general purpose message #2/4";
CM_ SG_ 2566808318 SecEngineMtdPTOSwitch "Signal which indicates the state of the second engine mounted power take off switch.";
CM_ SG_ 2566808318 SecClutchDpdtPTOSwitch "Signal which indicates the state of the second clutch dependent power take off switch.";
CM_ SG_ 2566808318 FirstClutchDpdtPTOSwitch "Signal which indicates the state of the first clutch dependent power take off switch.";
CM_ SG_ 2566808318 OperatingPanelActive "Signal which indicates that the operating panel is active.";
CM_ SG_ 2566808318 RefusePackerStepSwitch "Signal which indicates the state of the refuse packer step switch.";
CM_ SG_ 2566808318 EngineStopSwitch "Signal which indicates the state of the engine stop switch.";
CM_ SG_ 2566808318 EngineStartSwitch "Signal which indicates the state of the engine start switch.";
CM_ SG_ 2566808318 StarterLockoutSwitch "Signal which indicates the state of the starter lockout switch.";
CM_ SG_ 2566808318 RqstedPercentClutchSlip "Command signal to influence the clutch.";
CM_ SG_ 2566808318 FirstEngineMtdPTOSwitch "Signal which indicates the state of the first engine mounted power take off switch.";
CM_ SG_ 2566808318 ClutchIndpdtPTOSwitch "Signal which indicates the state of the clutch independent power take off switch.";
CM_ BO_ 2566808830 "ISO 11992: Towed vehicle message, general purpose message #2/5";
CM_ SG_ 2566808830 TrailerLeftSideMarkerLight "This signal indicates the state of the trailer left-hand side marker light(s).";
CM_ SG_ 2566808830 TrailerLeftReversingLight "This signal indicates the state of the trailer left-hand reversing light(s).";
CM_ SG_ 2566808830 TrailerLeftRearWidIndLight "This signal indicates the state of the trailer left-hand rear width indicator light(s).";
CM_ SG_ 2566808830 TrailerLeftRearRegPltLight "This signal indicates the state of the trailer left-hand rear registration-plate light(s).";
CM_ SG_ 2566808830 TrailerLeftRearLight "This signal indicates the state of the trailer left-hand rear light(s).";
CM_ SG_ 2566808830 TrailerLeftRearFogLight "This signal indicates the state of the trailer left-hand rear fog light(s).";
CM_ SG_ 2566808830 TrailerLeftDirIndLight "This signal indicates the state of the trailer left-hand direction indicator light(s).";
CM_ SG_ 2566808830 TrailerLeftCrnMarkerLight "This signal indicates the state of the trailer left-hand corner marker light(s).";
CM_ SG_ 2566808830 TrailerInteriorLight "This signal indicates the state of the trailer interior light(s).";
CM_ SG_ 2566808830 TrailerWorkLamp "This signal indicates the state of the trailer work lamp(s).";
CM_ SG_ 2566808830 TrailerRotatingIdentLight "This signal indicates the state of the trailer rotating identification light(s).";
CM_ SG_ 2566808830 TrailerRightStopLight "This signal indicates the state of the trailer right-hand stop light(s).";
CM_ SG_ 2566808830 TrailerRightSideMrkLight "This signal indicates the state of the trailer right-hand side marker light(s).";
CM_ SG_ 2566808830 TrailerRightReversingLight "This signal indicates the state of the trailer right-hand reversing light(s).";
CM_ SG_ 2566808830 TrailRightRearWidIndLight "This signal indicates the state of the trailer right-hand rear width indicator light(s).";
CM_ SG_ 2566808830 TrailerRightRearRegPltLight "This signal indicates the state of the trailer right-hand rear registration-plate light(s).";
CM_ SG_ 2566808830 TrailerRightRearLight "This signal indicates the state of the trailer right-hand rear light(s).";
CM_ SG_ 2566808830 TrailerRightRearFogLight "This signal indicates the state of the trailer right-hand rear fog light(s).";
CM_ SG_ 2566808830 TrailerRightDirIndLight "This signal indicates the state of the trailer right-hand direction indicator light(s).";
CM_ SG_ 2566808830 TrailerRightCrnMarkerLight "This signal indicates the state of the trailer right-hand corner marker light(s).";
CM_ SG_ 2566808830 TrailerRearWarningLight "This signal indicates the state of the trailer rear warning light(s).";
CM_ SG_ 2566808830 TrailerLeftStopLight "This signal indicates the state of the trailer left-hand stop light(s).";
CM_ BO_ 2565734142 "Used to access network interconnection ECU parametrics and database";
CM_ SG_ 2565734142 FilterMode "Filter mode for Network PG";
CM_ SG_ 2565734142 ToPort "Destination port for network PG";
CM_ SG_ 2565734142 FromPort "Source port for Network PG";
CM_ BO_ 2565130272 "ISO 11992: Towing vehicle message, running gear equipment #1/1

RGE11 replaces GFM 12 in ISO 11992:1998 part 3";
CM_ SG_ 2565130272 ParkingAndTrailerAirPress "The pneumatic pressure in the circuit or reservoir for the parking brake and the trailer supply.";
CM_ SG_ 2565130272 DrivenAxleLoad "Actual static vertical load on driven axle of the commercial vehicle. In case of more than one driven axle the value of the axle with the highest vertical load is transmitted.";
CM_ SG_ 2565130272 StopLevelChangeReq "Command signal to stop immediately any change of the actual body height level.";
CM_ SG_ 2565130272 RampLevelStorageReq "Command signal to store the actual body height level as new programmed and memorised ramp levels 1 or 2 in the ECU";
CM_ SG_ 2565130272 LevelControlReq "Command signal to enable or disable the automatic level control.";
CM_ SG_ 2565130272 RampLevelReq "Command signal to control the body height to a level programmed and memorised in the ECU.";
CM_ SG_ 2565130272 SteeringAxleLockingReq "Command signal to lock the steering axle.";
CM_ SG_ 2565130272 LiftAxle2PositionReq "Command signal to control the lift axle position / tag axle load condition.";
CM_ SG_ 2565130272 LiftAxle1PositionReq "Command signal to control the lift axle position / tag axle load condition.";
CM_ SG_ 2565130272 TractionHelpReq "Command signal to control the lift axle position / tag axle load condition to transfer more load on the driven axle of the commercial vehicle.";
CM_ SG_ 2565130272 LevelChangeReqRearAxle "Command signal to control the body height [up (lifting)/down (lowering)] for the rear axle.";
CM_ SG_ 2565130272 LevelChangeReqFrontAxle "Command signal to control the body height [up (lifting)/down (lowering)] for the front axle.";
CM_ SG_ 2565130272 RideHeightRequest_RGE11 "Command signal to activate a normal ride body height. The normal levels 1 and 2 are trailer specific body heights.";
CM_ BO_ 2565209854 "ISO 11992: Towed vehicle message, running gear equipment #2/1

RGE21 replaces GFM 22 in ISO 11992:1998 part 3";
CM_ SG_ 2565209854 LevelControl "Signal which indicates that the automatic level control is enabled or disabled.";
CM_ SG_ 2565209854 NominalVehBodyLevelRearAxle "Actual nominal vehicle body height.";
CM_ SG_ 2565209854 NominalVehBodyLevelFrontAxle "Actual nominal vehicle body height.";
CM_ SG_ 2565209854 RampLevel "Signal which indicates the level of the body height as an anser to 'ramp level request'.";
CM_ SG_ 2565209854 NormalLevel "Signal which indicates the normal levels of the vehicle independently of a specific request.";
CM_ SG_ 2565209854 StopLevelChangeAcknowledge "Signal which indicates the stop of any level change due to a 'stop request'.";
CM_ SG_ 2565209854 LevelChangeRearAxle "Signal which indicates the level change of the body height at the rear axle due to any external requests.";
CM_ SG_ 2565209854 LevelChangeFrontAxle "Signal which indicates the level change of the body height at the front axle due to any external requests.";
CM_ SG_ 2565209854 RampLevelStorage "Signal which indicates the storage of a new ramp level in the ECU.";
CM_ SG_ 2565209854 SteeringAxleLocking "Signal which indicates the actual steering axle locking status.";
CM_ SG_ 2565209854 LiftAxle2Pos "Signal which indicates the position / load condition of lift axle / tag axle #2.";
CM_ SG_ 2565209854 LiftAxle1Pos "Signal which indicates the position / load condition of lift axle / tag axle #1.";
CM_ SG_ 2565209854 RampLevelPosition "Signal which indicates the ramp level positions of the vehicle independently of a specific request.";
CM_ SG_ 2565209854 TractionHelp "Signal which indicates that a load transfer is active.";
CM_ SG_ 2565209854 LevelCtrlSysRideHeightLevel "Signal which indicates the body height position of the vehicle as an answer to 'ride height request'.";
CM_ BO_ 2566806782 "ISO 11992: Towed vehicle message, running gear equipment #2/2";
CM_ SG_ 2566806782 RelVehBodyLevelRearAxle "Actual relative vehicle body height.";
CM_ SG_ 2566806782 RelVehBodyLevelFrontAxle "Actual relative vehicle body height.";
CM_ BO_ 2566807294 "ISO 11992: Towed vehicle message, running gear equipment #2/3";
CM_ SG_ 2566807294 TyrePressThresholdDetect "Signal indicating the pressure level of the tyre.";
CM_ SG_ 2566807294 TyreModulePowerSupply "Signal indicating the power supply of the tyre module is sufficient to achieve the specified performance of the module.";
CM_ SG_ 2566807294 TyreTemperature "The temperature measured by the tyre module.";
CM_ SG_ 2566807294 AirLeakageDetection "The pressure loss of a tyre.";
CM_ SG_ 2566807294 TyreWheelIdentification2 "First part of the identification number of the tyre or whee (number of axles).";
CM_ SG_ 2566807294 TyreWheelIdentification1 "First part of the identification number of the tyre or whee (position on each axle).";
CM_ BO_ 2566764798 "Diagnostic readiness 3";
CM_ BO_ 2564095742 "Data security";
CM_ BO_ 2349137662 "External Brake Request";
CM_ SG_ 2349137662 XBRMessageChecksum "The XBR message checksum is used to verify the signal path from the demanding device to the brake controller on";
CM_ SG_ 2349137662 XBRMessageCounter "The XBR message counter is to verify the signal path from the demanding device to the brake controller on electronic";
CM_ SG_ 2349137662 XBRCtrlMode "The XBR Control Mode is used as an input to the brake system and defines how the external acceleration demand has to";
CM_ SG_ 2349137662 XBRPriority "The XBR Priority is used as an input to the brake system to manage the priority of overlapping external and internal requests.";
CM_ SG_ 2349137662 XBREBIMode "The XBR EBI (Endurance Brake Integration) Mode is used as an input for the brake system to prescribe the use of";
CM_ SG_ 2349137662 ExtlAccelerationDemand "Parameter provided to the brake system from external sources.";
CM_ SG_ 2349137662 XBRUrgency "The idea of the urgency value is to adjust the endurance brake integration behavior in the EBS system according to the";
CM_ BO_ 2566848510 "Water in Fuel Indicator";
CM_ SG_ 2566848510 WaterInFuelIndicator "Signal which indicates the presence of water in the fuel.";
CM_ BO_ 2566842927 "Vehicle Weight";
CM_ SG_ 2566842927 AxleLocation "To identify to which of several similar devices (such as tires or fuel tanks) the information applies.";
CM_ SG_ 2566842927 CargoWeight_30 "The mass of freight carried.";
CM_ SG_ 2566842927 CargoWeight_20 "The mass of freight carried.";
CM_ SG_ 2566842927 CargoWeight_10 "The mass of freight carried.";
CM_ SG_ 2566842927 CargoWeight_00 "The mass of freight carried.";
CM_ SG_ 2566842927 TrailerWeight_30 "Total mass of freight-carrying vehicle designed to be pulled by truck, including the weight of the contents.";
CM_ SG_ 2566842927 TrailerWeight_20 "Total mass of freight-carrying vehicle designed to be pulled by truck, including the weight of the contents.";
CM_ SG_ 2566842927 TrailerWeight_10 "Total mass of freight-carrying vehicle designed to be pulled by truck, including the weight of the contents.";
CM_ SG_ 2566842927 TrailerWeight_00 "Total mass of freight-carrying vehicle designed to be pulled by truck, including the weight of the contents.";
CM_ SG_ 2566842927 AxleWeight_00 "Total mass imposed by the tires on the road surface at the specified axle.";
CM_ BO_ 2566804222 "Vehicle Electrical Power #3";
CM_ SG_ 2566804222 NetBatteryCurrentHiRes "Net flow of electrical current into/out-of the battery or batteries.";
CM_ SG_ 2566804222 AltCurrentHiRes "This parameter indicates the amount of electrical current output from the alternator of the main vehicle.";
CM_ BO_ 2633928190 "Vehicle Electrical Power 2";
CM_ SG_ 2633928190 ECUPowerOutputSupplyVoltage3 "The third power output from an ECM.";
CM_ SG_ 2633928190 ECUPowerOutputSupplyVoltage2 "The second power output from an ECM.";
CM_ SG_ 2633928190 ECUPowerOutputSupplyVoltage1 "The first power output from an ECM";
CM_ SG_ 2633928190 BatteryPotential_PowerInput2 "This parameter measures the second source of battery potential as measured at the input of the ECM/actuator etc.";
CM_ BO_ 2566845438 "Vehicle Position";
CM_ SG_ 2566845438 Longitude "Longitude position of the vehicle.";
CM_ SG_ 2566845438 Latitude "Latitude position of the vehicle.";
CM_ BO_ 2566843646 "Vehicle Identification";
CM_ SG_ 2566843646 VehicleIdentificationNumber "Vehicle Identification Number";
CM_ BO_ 2566842112 "Vehicle Hours";
CM_ SG_ 2566842112 TotalPowerTakeoffHours "Accumulated time of operation of power takeoff device.";
CM_ SG_ 2566842112 TotalVehicleHours "Accumulated time of operation of vehicle.";
CM_ BO_ 2566809854 "Vehicle Fluids";
CM_ SG_ 2566809854 WinchOilPressSwitch "State of switch used to determine if Winch Oil Pressure is above desired minimum";
CM_ SG_ 2566809854 HydOilLevel "This parameter indicates the level of the hydraulic fluid in tank as a ratio of current volume to total tank volume.";
CM_ SG_ 2566809854 HydOilFilterRestrictionSwitch "This switch indicates whether hydraulic oil filter is clogged.";
CM_ SG_ 2566809854 HydTemp "Temperature of hydraulic fluid.";
CM_ BO_ 2566842622 "Vehicle Direction/Speed";
CM_ SG_ 2566842622 Altitude "Altitude of the vehicle referenced to sea level at standard atmospheric pressure and temperature.";
CM_ SG_ 2566842622 Pitch "Pitch of the vehicle as calculated by the navigation device(s).";
CM_ SG_ 2566842622 NavigationBasedVehicleSpeed "Speed of the vehicle as calculated from a device such as a Global Positioning System (GPS).";
CM_ SG_ 2566842622 CompassBearing "Present compass bearing of vehicle.";
CM_ BO_ 2566832638 "High Resolution Vehicle Distance";
CM_ SG_ 2566832638 HighResolutionTripDistance "Distance traveled during all or part of a journey.";
CM_ SG_ 2566832638 HghRslutionTotalVehicleDistance "Accumulated distance traveled by the vehicle during its operation.";
CM_ BO_ 2565867787 "Vehicle Dynamic Stability Control 2";
CM_ SG_ 2565867787 SteerWheelAngleSensorType "Indicates whether the steering wheel angle sensor is capable of absolute measuring of the number of steering wheel";
CM_ SG_ 2565867787 SteerWheelAngle "The main operator`s steering wheel angle (on the steering column, not the actual wheel angle).";
CM_ SG_ 2565867787 LongitudinalAcceleration "Indicates the longitudinal acceleration of the vehicle.";
CM_ SG_ 2565867787 LateralAcceleration "Indicates a lateral acceleration of the vehicle.";
CM_ SG_ 2565867787 YawRate "Indicates the rotation about the vertical axis.";
CM_ SG_ 2565867787 SteerWheelTurnCounter "Indicates number of steering wheel turns, absolute position or relative position at ignition on.";
CM_ BO_ 2566803211 "Vehicle Dynamic Stability Control 1";
CM_ SG_ 2566803211 YCBrakeCtrlActive "State signal which indicates that Yaw Control (YC) has activated brake control.";
CM_ SG_ 2566803211 YCEngCtrlActive "State Signal which indicates that the Yaw Control (YC) has commanded engine control to be active.";
CM_ SG_ 2566803211 ROPBrakeCtrlActive "State signal which indicates that Roll over Prevention (ROP) has activated brake control.";
CM_ SG_ 2566803211 ROPEngCtrlActive "State Signal which indicates that the Roll Over Prevention (ROP) has commanded engine control to be active.";
CM_ SG_ 2566803211 VDCBrakeLightRq "Indicates whether VDC requests to turn the vehicle brake lights on";
CM_ SG_ 2566803211 VDCFullyOperational "Signal that indicates whether VDC is fully operational or whether its functionality is reduced by a permanent or temporary";
CM_ SG_ 2566803211 VDCInformationSignal "This parameter commands the VDC information signal, for example a dash lamp.";
CM_ BO_ 2566840574 "Vehicle Distance";
CM_ SG_ 2566840574 TotalVehicleDistance "Accumulated distance traveled by vehicle during its operation.";
CM_ SG_ 2566840574 TripDistance "Distance traveled during all or part of a journey.";
CM_ BO_ 2633938686 "Trip Vehicle Speed/Cruise Distance Information";
CM_ SG_ 2633938686 TripCruiseDistance "Total distance that the engine has operated in the cruise hold state, excluding time in accelerator override, since the last";
CM_ SG_ 2633938686 TripMaxVehicleSpeed "Maximum vehicle speed achieved while the engine speed is greater than zero and the accelerator pedal position (APS) is";
CM_ BO_ 2633937150 "Trip Time Information 2";
CM_ SG_ 2633937150 TripAirCompressorOnTime "Total time that the air compressor is on and compressing air since the last trip reset.";
CM_ SG_ 2633937150 TripIdleTime "Total time accumulated while the engine speed is greater than zero, both the PTO and remote PTO governors are";
CM_ SG_ 2633937150 TripEngRunningTime "Total time accumulated while the engine speed is greater than zero since the last trip reset.";
CM_ SG_ 2633937150 TripCruiseTime "Total time accumulated while the engine is in the cruise hold state, excluding time in accelerator override, since the last trip reset.";
CM_ SG_ 2633937150 TripPTOGovernorTime "Total time accumulated while the engine is in the PTO or remote PTO governor hold state since the last trip reset.";
CM_ BO_ 2633938174 "Trip Time Information 1";
CM_ SG_ 2633938174 TripTimeInDerateByEng "Total time accumulated when the engine final fueling has been derated due to an engine protection algorithm, since the last reset.";
CM_ SG_ 2633938174 TripTimeInGearDown "Total time accumulated when the vehicle has operated in one gear down from the top gear for a calibrated minimum time,";
CM_ SG_ 2633938174 TripTimeInTopGear "Total time accumulated when the vehicle has operated in top gear for a calibrated minimum time, since the last trip reset.";
CM_ SG_ 2633938174 TripTimeInVSL "Total time accumulated when the engine has operated on the vehicle speed limiter (VSL) while not in the cruise hold";
CM_ BO_ 2633938430 "Trip Shutdown Information";
CM_ SG_ 2633938430 TripSuddenDecelerations "Total number of decelerations whenever the vehicle deceleration is more than XYZ km/h/sec (where XYZ is a calibratible";
CM_ SG_ 2633938430 TrpNmberOfIdleShutdownOverrides "Total number of times an operator disables idle shutdown to prevent an engine shutdown, since the last trip reset.";
CM_ SG_ 2633938430 TripNumberOfIdleShutdowns "Total number of times the engine has been shutdown due to idling too long (at normal idle or fast idle) since the last trip reset.";
CM_ SG_ 2633938430 TripNumberOfHotShutdowns "Total number of hot shutdowns since the last trip reset.";
CM_ BO_ 2348814347 "Torque/Speed Control 1";
CM_ SG_ 2348814347 EngRqedTorque_TorqueLimit_Int "Parameter provided to the engine or retarder in the torque/speed control message for controlling or limiting the output torque.";
CM_ SG_ 2348814347 EngRqedSpeed_SpeedLimit_Int "Parameter provided to the engine from external sources in the torque/speed control message.";
CM_ SG_ 2348814347 EngRqedSpeedCtrlConditions_Int "This mode tells the engine control system the governor characteristics that are desired during speed control.";
CM_ BO_ 2566766846 "Passenger Counter";
CM_ SG_ 2566766846 TransitRunStatus "Status of the run switch for the vehicle.";
CM_ SG_ 2566766846 VehicleUseStatus "Used to indicate the proper or unauthorized use of the vehicle.";
CM_ SG_ 2566766846 SilentAlarmStatus "Used to report silent alarm push button status.";
CM_ SG_ 2566766846 PatronCount "Count of the number of passengers on a transit vehicle.";
CM_ SG_ 2566766846 TypeOfPassengerCount "Used to notify transit link devices of the type of passenger counting system used in the vehicle.";
CM_ BO_ 2566765310 "Farebox Status";
CM_ SG_ 2566765310 FareboxAlarmIdentifier "Indicates the nature of the farebox alarm condition.";
CM_ SG_ 2566765310 FareboxEmergencyStatus "Indicates if a farebox emergency condition exists.";
CM_ BO_ 2566765566 "Farebox Point of Sale";
CM_ SG_ 2566765566 TransferSold "Indicates that a transfer was sold or issued on this transaction including its type and/or restrictions.";
CM_ SG_ 2566765566 RouteNumber "The route number issuing the transfer.";
CM_ SG_ 2566765566 TransferType "The kind of transfer used";
CM_ SG_ 2566765566 TypeOfService "The type of service provided";
CM_ SG_ 2566765566 InitialFareAgency "Identifies where the initial fare is paid";
CM_ SG_ 2566765566 PassCategory "Agency defined value indicating the category of the passenger associated with this fare";
CM_ SG_ 2566765566 FareValidity "Agency defined value indicating validity of this fare";
CM_ SG_ 2566765566 PaymentDetails "Payment details.";
CM_ SG_ 2566765566 TypeOfFare "Type of Fare";
CM_ SG_ 2566765566 PassengerType "Enumerated value representing the type/class of passenger, as defined by the agency.";
CM_ SG_ 2566765566 TransactionType "Enumerated value representing the type of transaction completed";
CM_ BO_ 2566765822 "Farebox Service Detail";
CM_ SG_ 2566765822 DriversFareboxSecurityCode "Security code for the farebox, numerical only.";
CM_ SG_ 2566765822 AssignedBlock "The agency defined block number for this trip";
CM_ SG_ 2566765822 AssignedRun "The agency defined run number for this trip";
CM_ SG_ 2566765822 AssignedRoute "The identity number assigned to this route.";
CM_ SG_ 2566765822 PatternNumber "The agency defined pattern number for this trip";
CM_ SG_ 2566765822 TripNumber "The identity number assigned to this trip.";
CM_ SG_ 2566765822 FarePresets "Fare Presets";
CM_ SG_ 2566765822 TripDirection "The general direction of travel for this trip.";
CM_ SG_ 2566765822 TripStatus "Trip Status";
CM_ SG_ 2566765822 FareboxServiceStatus "Indicates if the farebox is in or out of service.";
CM_ BO_ 2566766078 "Signal Preemption";
CM_ SG_ 2566766078 VehicleID "Numerical designation of the vehicle.";
CM_ SG_ 2566766078 StrobeActivationCtrlStatus "Strobe activation control status";
CM_ SG_ 2566766078 TransitDoorEnable "Transit door enable";
CM_ SG_ 2566766078 PriorityOfRespSentByEmitter "Priority of response sent by emitter";
CM_ SG_ 2566766078 IntersectionPreemptionRq_Resp "Status of the intersection signal preemption";
CM_ SG_ 2566766078 TransitRouteIDUsage "Transit route ID usage";
CM_ SG_ 2566766078 RangeCodeEnable "Range code enable";
CM_ BO_ 2566766590 "Transit Milepost";
CM_ SG_ 2566766590 NmbrOfBytsInMlpstIdentification "Number of bytes in the Milepost Identification.";
BA_DEF_ SG_  "SigType" ENUM  "Default","Range","RangeSigned","ASCII","Discrete","Control","ReferencePGN","DTC","StringDelimiter","StringLength","StringLengthControl";
BA_DEF_ SG_  "GenSigStartValue" INT 0 10000;
BA_DEF_ SG_  "GenSigSendType" ENUM  "Cyclic","OnWrite","reserved","OnChange","reserved","reserved","reserved","NoSigSendType";
BA_DEF_ SG_  "GenSigILSupport" ENUM  "Yes","No";
BA_DEF_ SG_  "GenSigEVName" STRING ;
BA_DEF_ SG_  "SPN" INT 0 524287;
BA_DEF_ BO_  "GenMsgStartDelayTime" INT 0 100000;
BA_DEF_ BO_  "GenMsgILSupport" ENUM  "Yes","No";
BA_DEF_ BO_  "GenMsgDelayTime" INT 0 1000;
BA_DEF_ BO_  "GenMsgRequestable" INT 0 1;
BA_DEF_ BO_  "GenMsgSendType" ENUM  "cyclic","Spontaneus","cyclicIfActive","reserved","reserved","reserved","reserved","reserved","noMsgSendType","OnRequest";
BA_DEF_ BO_  "VFrameFormat" ENUM  "StandardCAN","ExtendedCAN","reserved","J1939PG";
BA_DEF_ BO_  "GenMsgCycleTime" INT 0 3600000;
BA_DEF_ SG_  "SystemSignalLongSymbol" STRING ;
BA_DEF_DEF_  "SigType" "Default";
BA_DEF_DEF_  "GenSigStartValue" 0;
BA_DEF_DEF_  "GenSigSendType" "NoSigSendType";
BA_DEF_DEF_  "GenSigILSupport" "Yes";
BA_DEF_DEF_  "GenSigEVName" "Env@Nodename_@Signame";
BA_DEF_DEF_  "SPN" 0;
BA_DEF_DEF_  "GenMsgStartDelayTime" 0;
BA_DEF_DEF_  "GenMsgILSupport" "Yes";
BA_DEF_DEF_  "GenMsgDelayTime" 0;
BA_DEF_DEF_  "GenMsgRequestable" 1;
BA_DEF_DEF_  "GenMsgSendType" "noMsgSendType";
BA_DEF_DEF_  "VFrameFormat" "J1939PG";
BA_DEF_DEF_  "GenMsgCycleTime" 0;
BA_DEF_DEF_  "SystemSignalLongSymbol" "";
BA_ "GenMsgCycleTime" BO_ 2566770942 500;
BA_ "GenMsgSendType" BO_ 2566770942 0;
BA_ "GenMsgCycleTime" BO_ 2566845952 500;
BA_ "GenMsgSendType" BO_ 2566845952 0;
BA_ "GenMsgCycleTime" BO_ 2566811134 1000;
BA_ "GenMsgSendType" BO_ 2566811134 0;
BA_ "GenMsgCycleTime" BO_ 2298375934 20;
BA_ "GenMsgSendType" BO_ 2298375934 0;
BA_ "GenMsgCycleTime" BO_ 2565867774 50;
BA_ "GenMsgSendType" BO_ 2565867774 0;
BA_ "GenMsgSendType" BO_ 2566841600 0;
BA_ "GenMsgCycleTime" BO_ 2566841600 100;
BA_ "GenMsgCycleTime" BO_ 2365449982 100;
BA_ "GenMsgSendType" BO_ 2365449982 0;
BA_ "GenMsgCycleTime" BO_ 2566757630 1000;
BA_ "GenMsgSendType" BO_ 2566757630 0;
BA_ "GenMsgCycleTime" BO_ 2566757886 1000;
BA_ "GenMsgSendType" BO_ 2566757886 0;
BA_ "GenMsgCycleTime" BO_ 2566759678 100;
BA_ "GenMsgSendType" BO_ 2566759678 0;
BA_ "GenMsgCycleTime" BO_ 2432541438 500;
BA_ "GenMsgSendType" BO_ 2432541438 0;
BA_ "GenMsgCycleTime" BO_ 2566761214 500;
BA_ "GenMsgSendType" BO_ 2566761214 0;
BA_ "GenMsgCycleTime" BO_ 2432541694 100;
BA_ "GenMsgSendType" BO_ 2432541694 0;
BA_ "GenMsgCycleTime" BO_ 2566759934 100;
BA_ "GenMsgSendType" BO_ 2566759934 0;
BA_ "GenMsgCycleTime" BO_ 2566757374 1000;
BA_ "GenMsgSendType" BO_ 2566757374 0;
BA_ "GenMsgCycleTime" BO_ 2364546302 100;
BA_ "GenMsgSendType" BO_ 2364546302 0;
BA_ "GenMsgCycleTime" BO_ 2431654654 50;
BA_ "GenMsgSendType" BO_ 2431654654 0;
BA_ "GenMsgCycleTime" BO_ 2364545534 5000;
BA_ "GenMsgSendType" BO_ 2364545534 0;
BA_ "GenMsgCycleTime" BO_ 2364545278 5000;
BA_ "GenMsgSendType" BO_ 2364545278 0;
BA_ "GenMsgCycleTime" BO_ 2364545022 5000;
BA_ "GenMsgSendType" BO_ 2364545022 0;
BA_ "GenMsgCycleTime" BO_ 2364544766 5000;
BA_ "GenMsgSendType" BO_ 2364544766 0;
BA_ "GenMsgCycleTime" BO_ 2364544510 100;
BA_ "GenMsgSendType" BO_ 2364544510 0;
BA_ "GenMsgCycleTime" BO_ 2364544254 50;
BA_ "GenMsgSendType" BO_ 2364544254 0;
BA_ "GenMsgCycleTime" BO_ 2348992544 10;
BA_ "GenMsgSendType" BO_ 2348992544 0;
BA_ "GenMsgCycleTime" BO_ 2566834464 100;
BA_ "GenMsgSendType" BO_ 2566834464 0;
BA_ "GenMsgCycleTime" BO_ 2550341832 10;
BA_ "GenMsgSendType" BO_ 2550341832 0;
BA_ "GenMsgCycleTime" BO_ 2566833352 100;
BA_ "GenMsgSendType" BO_ 2566833352 0;
BA_ "GenMsgCycleTime" BO_ 2365507272 100;
BA_ "GenMsgSendType" BO_ 2365507272 0;
BA_ "GenMsgCycleTime" BO_ 2565013246 100;
BA_ "GenMsgSendType" BO_ 2565013246 0;
BA_ "GenMsgCycleTime" BO_ 2566807038 500;
BA_ "GenMsgSendType" BO_ 2566807038 0;
BA_ "GenMsgCycleTime" BO_ 2365480958 50;
BA_ "GenMsgSendType" BO_ 2365480958 0;
BA_ "GenMsgCycleTime" BO_ 2566808062 100;
BA_ "GenMsgSendType" BO_ 2566808062 0;
BA_ "GenMsgCycleTime" BO_ 2566808574 1000;
BA_ "GenMsgSendType" BO_ 2566808574 0;
BA_ "GenMsgCycleTime" BO_ 2566809086 100;
BA_ "GenMsgSendType" BO_ 2566809086 0;
BA_ "GenMsgCycleTime" BO_ 2564947710 100;
BA_ "GenMsgSendType" BO_ 2564947710 0;
BA_ "GenMsgCycleTime" BO_ 2566834430 100;
BA_ "GenMsgSendType" BO_ 2566834430 0;
BA_ "GenMsgCycleTime" BO_ 2365481214 100;
BA_ "GenMsgSendType" BO_ 2365481214 0;
BA_ "GenMsgCycleTime" BO_ 2566808318 100;
BA_ "GenMsgSendType" BO_ 2566808318 0;
BA_ "GenMsgCycleTime" BO_ 2566808830 100;
BA_ "GenMsgSendType" BO_ 2566808830 0;
BA_ "GenMsgCycleTime" BO_ 2565130272 100;
BA_ "GenMsgSendType" BO_ 2565130272 0;
BA_ "GenMsgCycleTime" BO_ 2565209854 100;
BA_ "GenMsgSendType" BO_ 2565209854 0;
BA_ "GenMsgCycleTime" BO_ 2566806782 100;
BA_ "GenMsgSendType" BO_ 2566806782 0;
BA_ "GenMsgCycleTime" BO_ 2566807294 1000;
BA_ "GenMsgSendType" BO_ 2566807294 0;
BA_ "GenMsgCycleTime" BO_ 2349137662 20;
BA_ "GenMsgSendType" BO_ 2349137662 2;
BA_ "GenMsgCycleTime" BO_ 2566848510 10000;
BA_ "GenMsgSendType" BO_ 2566848510 0;
BA_ "GenMsgSendType" BO_ 2566842927 0;
BA_ "GenMsgCycleTime" BO_ 2566842927 100;
BA_ "GenMsgCycleTime" BO_ 2566804222 1000;
BA_ "GenMsgSendType" BO_ 2566804222 0;
BA_ "GenMsgCycleTime" BO_ 2566845438 5000;
BA_ "GenMsgSendType" BO_ 2566845438 0;
BA_ "GenMsgSendType" BO_ 2566843646 2;
BA_ "GenMsgCycleTime" BO_ 2566809854 1000;
BA_ "GenMsgSendType" BO_ 2566809854 0;
BA_ "GenMsgCycleTime" BO_ 2566832638 1000;
BA_ "GenMsgSendType" BO_ 2566832638 0;
BA_ "GenMsgCycleTime" BO_ 2565867787 20;
BA_ "GenMsgSendType" BO_ 2565867787 0;
BA_ "GenMsgCycleTime" BO_ 2566803211 100;
BA_ "GenMsgSendType" BO_ 2566803211 0;
BA_ "GenMsgCycleTime" BO_ 2566840574 100;
BA_ "GenMsgSendType" BO_ 2566840574 0;
BA_ "GenMsgCycleTime" BO_ 2348814347 50;
BA_ "GenMsgSendType" BO_ 2348814347 2;
BA_ "SPN" SG_ 2566770942 EngAirFilter4DiffPress 2811;
BA_ "SigType" SG_ 2566770942 EngAirFilter4DiffPress 1;
BA_ "SPN" SG_ 2566770942 EngAirFilter3DiffPress 2810;
BA_ "SigType" SG_ 2566770942 EngAirFilter3DiffPress 1;
BA_ "SPN" SG_ 2566770942 EngAirFilter2DiffPress 2809;
BA_ "SigType" SG_ 2566770942 EngAirFilter2DiffPress 1;
BA_ "SPN" SG_ 2566770942 EngIntakeManifold1AbsPress 4817;
BA_ "SigType" SG_ 2566770942 EngIntakeManifold1AbsPress 1;
BA_ "SPN" SG_ 2566770942 EngIntakeManifold2AbsPress 5422;
BA_ "SigType" SG_ 2566770942 EngIntakeManifold2AbsPress 1;
BA_ "SPN" SG_ 2566770942 EngIntakeManifold2Press 3562;
BA_ "SigType" SG_ 2566770942 EngIntakeManifold2Press 1;
BA_ "SPN" SG_ 2566770942 EngIntakeManifold1AbsPressHiRes 4817;
BA_ "SigType" SG_ 2566770942 EngIntakeManifold1AbsPressHiRes 1;
BA_ "SPN" SG_ 2566845952 EngCoolantFilterDiffPress 112;
BA_ "SigType" SG_ 2566845952 EngCoolantFilterDiffPress 1;
BA_ "SPN" SG_ 2566845952 EngExhaustGasTemp 173;
BA_ "SigType" SG_ 2566845952 EngExhaustGasTemp 1;
BA_ "SPN" SG_ 2566845952 EngAirFilter1DiffPress 107;
BA_ "SigType" SG_ 2566845952 EngAirFilter1DiffPress 1;
BA_ "SPN" SG_ 2566845952 EngIntakeManifold1Temp 105;
BA_ "SigType" SG_ 2566845952 EngIntakeManifold1Temp 1;
BA_ "SPN" SG_ 2566845952 EngBoostPressure 102;
BA_ "SigType" SG_ 2566845952 EngBoostPressure 1;
BA_ "SPN" SG_ 2566845952 EngPrtcltTrpInletPressure 81;
BA_ "SigType" SG_ 2566845952 EngPrtcltTrpInletPressure 1;
BA_ "SPN" SG_ 2566845952 EngAirInletPressure 106;
BA_ "SigType" SG_ 2566845952 EngAirInletPressure 1;
BA_ "SPN" SG_ 2566811134 CabHeatingZone 1680;
BA_ "SigType" SG_ 2566811134 CabHeatingZone 4;
BA_ "SPN" SG_ 2566811134 EngHeatingZone 1679;
BA_ "SigType" SG_ 2566811134 EngHeatingZone 4;
BA_ "SPN" SG_ 2566811134 CabVentilation 1678;
BA_ "SigType" SG_ 2566811134 CabVentilation 4;
BA_ "SPN" SG_ 2566811134 AuxHeaterOutputPowerPercent 1689;
BA_ "SigType" SG_ 2566811134 AuxHeaterOutputPowerPercent 1;
BA_ "SPN" SG_ 2566811134 AuxHeaterInputAirTemp 1688;
BA_ "SigType" SG_ 2566811134 AuxHeaterInputAirTemp 1;
BA_ "SPN" SG_ 2566811134 AuxHeaterOutputCoolantTemp 1687;
BA_ "SigType" SG_ 2566811134 AuxHeaterOutputCoolantTemp 1;
BA_ "SPN" SG_ 2566811134 AuxHeaterWaterPumpStatus 1676;
BA_ "SigType" SG_ 2566811134 AuxHeaterWaterPumpStatus 4;
BA_ "SPN" SG_ 2298375934 RearAxleRightWheelSpeed 1595;
BA_ "SigType" SG_ 2298375934 RearAxleRightWheelSpeed 1;
BA_ "SPN" SG_ 2298375934 RearAxleLeftWheelSpeed 1594;
BA_ "SigType" SG_ 2298375934 RearAxleLeftWheelSpeed 1;
BA_ "SPN" SG_ 2298375934 FrontAxleRightWheelSpeed 1593;
BA_ "SigType" SG_ 2298375934 FrontAxleRightWheelSpeed 1;
BA_ "SPN" SG_ 2298375934 FrontAxleLeftWheelSpeed 1592;
BA_ "SigType" SG_ 2298375934 FrontAxleLeftWheelSpeed 1;
BA_ "SPN" SG_ 2565867774 FireApparatusPumpEngagement 2599;
BA_ "SigType" SG_ 2565867774 FireApparatusPumpEngagement 4;
BA_ "SPN" SG_ 2565867774 EngHydPressGovernorSwitch 1764;
BA_ "SigType" SG_ 2565867774 EngHydPressGovernorSwitch 4;
BA_ "SPN" SG_ 2565867774 EngHydPrssGovernorModeIndicator 1763;
BA_ "SigType" SG_ 2565867774 EngHydPrssGovernorModeIndicator 4;
BA_ "SPN" SG_ 2565867774 HydPress 1762;
BA_ "SigType" SG_ 2565867774 HydPress 1;
BA_ "SPN" SG_ 2566841600 EngTotalRevolutions 249;
BA_ "SigType" SG_ 2566841600 EngTotalRevolutions 1;
BA_ "SPN" SG_ 2566841600 EngTotalHoursOfOperation 247;
BA_ "SigType" SG_ 2566841600 EngTotalHoursOfOperation 1;
BA_ "SPN" SG_ 2365449982 HydBrakeFluidLevelSwitch 2931;
BA_ "SigType" SG_ 2365449982 HydBrakeFluidLevelSwitch 4;
BA_ "SPN" SG_ 2365449982 HydBrakeSystemAudibleWarningCmd 2930;
BA_ "SigType" SG_ 2365449982 HydBrakeSystemAudibleWarningCmd 4;
BA_ "SPN" SG_ 2365449982 HydBrkePressSupplyStateCircuit2 2583;
BA_ "SigType" SG_ 2365449982 HydBrkePressSupplyStateCircuit2 4;
BA_ "SPN" SG_ 2365449982 HydBrkePressSupplyStateCircuit1 2582;
BA_ "SigType" SG_ 2365449982 HydBrkePressSupplyStateCircuit1 4;
BA_ "SPN" SG_ 2365449982 HydBrkPressWarningStateCircuit2 2585;
BA_ "SigType" SG_ 2365449982 HydBrkPressWarningStateCircuit2 4;
BA_ "SPN" SG_ 2365449982 HydBrkPressWarningStateCircuit1 2584;
BA_ "SigType" SG_ 2365449982 HydBrkPressWarningStateCircuit1 4;
BA_ "SPN" SG_ 2365449982 HydBrakePressCircuit2 2581;
BA_ "SigType" SG_ 2365449982 HydBrakePressCircuit2 1;
BA_ "SPN" SG_ 2365449982 HydBrakePressCircuit1 2580;
BA_ "SigType" SG_ 2365449982 HydBrakePressCircuit1 1;
BA_ "SPN" SG_ 2633939198 TripDriveFuelEconomy 1012;
BA_ "SigType" SG_ 2633939198 TripDriveFuelEconomy 1;
BA_ "SPN" SG_ 2633939198 TrpPTOGovernorNonmovingFuelUsed 1009;
BA_ "SigType" SG_ 2633939198 TrpPTOGovernorNonmovingFuelUsed 1;
BA_ "SPN" SG_ 2633939198 TripVehicleIdleFuelUsed 1010;
BA_ "SigType" SG_ 2633939198 TripVehicleIdleFuelUsed 1;
BA_ "SPN" SG_ 2633939198 TripCruiseFuelUsed 1011;
BA_ "SigType" SG_ 2633939198 TripCruiseFuelUsed 1;
BA_ "SPN" SG_ 2633939198 TripDriveFuelUsed 1007;
BA_ "SigType" SG_ 2633939198 TripDriveFuelUsed 1;
BA_ "SPN" SG_ 2633939198 TripPTOGovernorMovingFuelUsed 1008;
BA_ "SigType" SG_ 2633939198 TripPTOGovernorMovingFuelUsed 1;
BA_ "SPN" SG_ 2633927678 EngFuelValve1OutletAbsPress 2980;
BA_ "SigType" SG_ 2633927678 EngFuelValve1OutletAbsPress 1;
BA_ "SPN" SG_ 2633927678 EngAirToFuelDiffPress 1392;
BA_ "SigType" SG_ 2633927678 EngAirToFuelDiffPress 1;
BA_ "SPN" SG_ 2633927678 EngFuelValveDiffPress 1391;
BA_ "SigType" SG_ 2633927678 EngFuelValveDiffPress 1;
BA_ "SPN" SG_ 2633927678 EngFuelValve1IntakeAbsPress 1390;
BA_ "SigType" SG_ 2633927678 EngFuelValve1IntakeAbsPress 1;
BA_ "SPN" SG_ 2633925118 EngFuelFlowRate2 1441;
BA_ "SigType" SG_ 2633925118 EngFuelFlowRate2 1;
BA_ "SPN" SG_ 2633925118 EngFuelFlowRate1 1440;
BA_ "SigType" SG_ 2633925118 EngFuelFlowRate1 1;
BA_ "SPN" SG_ 2633925118 EngRqedFuelValve2Pos 1766;
BA_ "SigType" SG_ 2633925118 EngRqedFuelValve2Pos 1;
BA_ "SPN" SG_ 2633925118 EngRqedFuelValve1Pos 1765;
BA_ "SigType" SG_ 2633925118 EngRqedFuelValve1Pos 1;
BA_ "SPN" SG_ 2633925118 EngFuelValve2Pos 1443;
BA_ "SigType" SG_ 2633925118 EngFuelValve2Pos 1;
BA_ "SPN" SG_ 2633925118 EngFuelValve1Pos 1442;
BA_ "SigType" SG_ 2633925118 EngFuelValve1Pos 1;
BA_ "SPN" SG_ 2633937662 TotalEngPTOGovernorFuelUsed 1030;
BA_ "SigType" SG_ 2633937662 TotalEngPTOGovernorFuelUsed 1;
BA_ "SPN" SG_ 2633937662 TripAverageFuelRate 1031;
BA_ "SigType" SG_ 2633937662 TripAverageFuelRate 1;
BA_ "SPN" SG_ 2633937662 EngFuelSpecificGravity 1389;
BA_ "SigType" SG_ 2633937662 EngFuelSpecificGravity 1;
BA_ "SPN" SG_ 2566804990 SpecificHeatRatio 1767;
BA_ "SigType" SG_ 2566804990 SpecificHeatRatio 1;
BA_ "SPN" SG_ 2633936894 TotalFuelUsed 1040;
BA_ "SigType" SG_ 2633936894 TotalFuelUsed 1;
BA_ "SPN" SG_ 2633936894 TripFuel 1039;
BA_ "SigType" SG_ 2633936894 TripFuel 1;
BA_ "SPN" SG_ 2566757630 SensorSupplyVoltage6 3514;
BA_ "SigType" SG_ 2566757630 SensorSupplyVoltage6 1;
BA_ "SPN" SG_ 2566757630 SensorSupplyVoltage5 3513;
BA_ "SigType" SG_ 2566757630 SensorSupplyVoltage5 1;
BA_ "SPN" SG_ 2566757630 SensorSupplyVoltage8 5126;
BA_ "SigType" SG_ 2566757630 SensorSupplyVoltage8 1;
BA_ "SPN" SG_ 2566757630 SensorSupplyVoltage7 5125;
BA_ "SigType" SG_ 2566757630 SensorSupplyVoltage7 1;
BA_ "SPN" SG_ 2566757886 SensorSupplyVoltage4 3512;
BA_ "SigType" SG_ 2566757886 SensorSupplyVoltage4 1;
BA_ "SPN" SG_ 2566757886 SensorSupplyVoltage3 3511;
BA_ "SigType" SG_ 2566757886 SensorSupplyVoltage3 1;
BA_ "SPN" SG_ 2566757886 SensorSupplyVoltage2 3510;
BA_ "SigType" SG_ 2566757886 SensorSupplyVoltage2 1;
BA_ "SPN" SG_ 2566757886 SensorSupplyVoltage1 3509;
BA_ "SigType" SG_ 2566757886 SensorSupplyVoltage1 1;
BA_ "SPN" SG_ 2566759678 EnggmntSttusTransInputShaftPTO1 3460;
BA_ "SigType" SG_ 2566759678 EnggmntSttusTransInputShaftPTO1 4;
BA_ "SPN" SG_ 2566759678 EnggmntSttusTransInputShaftPTO2 3461;
BA_ "SigType" SG_ 2566759678 EnggmntSttusTransInputShaftPTO2 4;
BA_ "SPN" SG_ 2566759678 EnggmntSttusTransOutputShaftPTO 3462;
BA_ "SigType" SG_ 2566759678 EnggmntSttusTransOutputShaftPTO 4;
BA_ "SPN" SG_ 2566759678 EnggmntSttsTrnsfrCsOtptShaftPTO 3463;
BA_ "SigType" SG_ 2566759678 EnggmntSttsTrnsfrCsOtptShaftPTO 4;
BA_ "SPN" SG_ 2566759678 EnggmntCnsntTransInputShaftPTO1 3456;
BA_ "SigType" SG_ 2566759678 EnggmntCnsntTransInputShaftPTO1 4;
BA_ "SPN" SG_ 2566759678 EnggmntCnsntTransInputShaftPTO2 3457;
BA_ "SigType" SG_ 2566759678 EnggmntCnsntTransInputShaftPTO2 4;
BA_ "SPN" SG_ 2566759678 EnggmntCnsntTransOutputShaftPTO 3458;
BA_ "SigType" SG_ 2566759678 EnggmntCnsntTransOutputShaftPTO 4;
BA_ "SPN" SG_ 2566759678 EnggmntCnsntTrnsfrCsOtptShftPTO 3459;
BA_ "SigType" SG_ 2566759678 EnggmntCnsntTrnsfrCsOtptShftPTO 4;
BA_ "SPN" SG_ 2566759678 EnableSwitchTransInputShaftPTO1 3452;
BA_ "SigType" SG_ 2566759678 EnableSwitchTransInputShaftPTO1 4;
BA_ "SPN" SG_ 2566759678 EnableSwitchTransInputShaftPTO2 3453;
BA_ "SigType" SG_ 2566759678 EnableSwitchTransInputShaftPTO2 4;
BA_ "SPN" SG_ 2566759678 EnableSwitchTransOutputShaftPTO 3454;
BA_ "SigType" SG_ 2566759678 EnableSwitchTransOutputShaftPTO 4;
BA_ "SPN" SG_ 2566759678 EnblSwtchTrnsfrCsOutputShaftPTO 3455;
BA_ "SigType" SG_ 2566759678 EnblSwtchTrnsfrCsOutputShaftPTO 4;
BA_ "SPN" SG_ 2566759678 EnggmntSttsPTOEngAccssoryDrive2 3947;
BA_ "SigType" SG_ 2566759678 EnggmntSttsPTOEngAccssoryDrive2 4;
BA_ "SPN" SG_ 2566759678 EnggmntSttsPTOEngAccssoryDrive1 3944;
BA_ "SigType" SG_ 2566759678 EnggmntSttsPTOEngAccssoryDrive1 4;
BA_ "SPN" SG_ 2566759678 EnggmntCnsntPTOEngAccssryDrive2 3946;
BA_ "SigType" SG_ 2566759678 EnggmntCnsntPTOEngAccssryDrive2 4;
BA_ "SPN" SG_ 2566759678 EnggmntCnsntPTOEngAccssryDrive1 3943;
BA_ "SigType" SG_ 2566759678 EnggmntCnsntPTOEngAccssryDrive1 4;
BA_ "SPN" SG_ 2566759678 EngagementStatusPTOEngFlywheel 3941;
BA_ "SigType" SG_ 2566759678 EngagementStatusPTOEngFlywheel 4;
BA_ "SPN" SG_ 2566759678 EngagementConsentPTOEngFlywheel 3940;
BA_ "SigType" SG_ 2566759678 EngagementConsentPTOEngFlywheel 4;
BA_ "SPN" SG_ 2566759678 EnblSwitchPTOEngAccessoryDrive2 3945;
BA_ "SigType" SG_ 2566759678 EnblSwitchPTOEngAccessoryDrive2 4;
BA_ "SPN" SG_ 2566759678 EnblSwitchPTOEngAccessoryDrive1 3942;
BA_ "SigType" SG_ 2566759678 EnblSwitchPTOEngAccessoryDrive1 4;
BA_ "SPN" SG_ 2566759678 EnableSwitchPTOEngFlywheel 3939;
BA_ "SigType" SG_ 2566759678 EnableSwitchPTOEngFlywheel 4;
BA_ "SPN" SG_ 2566759678 AtLeastOnePTOEngaged 3948;
BA_ "SigType" SG_ 2566759678 AtLeastOnePTOEngaged 4;
BA_ "SPN" SG_ 2432541438 EngFuelValve2OutletAbsPress 3469;
BA_ "SigType" SG_ 2432541438 EngFuelValve2OutletAbsPress 1;
BA_ "SPN" SG_ 2432541438 EngFuelTemp2 3468;
BA_ "SigType" SG_ 2432541438 EngFuelTemp2 1;
BA_ "SPN" SG_ 2432541438 EngGas2MassFlowRate 3467;
BA_ "SigType" SG_ 2432541438 EngGas2MassFlowRate 1;
BA_ "SPN" SG_ 2432541438 EngFuelValve2IntakeAbsPress 3466;
BA_ "SigType" SG_ 2432541438 EngFuelValve2IntakeAbsPress 1;
BA_ "SPN" SG_ 2566761214 EngCentrifugalOilFilterSpeed 3343;
BA_ "SigType" SG_ 2566761214 EngCentrifugalOilFilterSpeed 1;
BA_ "SPN" SG_ 2566761214 EngCoolantPumpDiffPress 3342;
BA_ "SigType" SG_ 2566761214 EngCoolantPumpDiffPress 1;
BA_ "SPN" SG_ 2566761214 EngChargeAirCooler2IntakePress 3341;
BA_ "SigType" SG_ 2566761214 EngChargeAirCooler2IntakePress 1;
BA_ "SPN" SG_ 2566761214 EngChargeAirCooler1IntakePress 3340;
BA_ "SigType" SG_ 2566761214 EngChargeAirCooler1IntakePress 1;
BA_ "SPN" SG_ 2566761214 EngIntercoolerCoolantLevel 3668;
BA_ "SigType" SG_ 2566761214 EngIntercoolerCoolantLevel 1;
BA_ "SPN" SG_ 2566761214 EngChargeAirCoolerOutletPress 2631;
BA_ "SigType" SG_ 2566761214 EngChargeAirCoolerOutletPress 1;
BA_ "SPN" SG_ 2566761214 EngAftercoolerCoolantLevel 3676;
BA_ "SigType" SG_ 2566761214 EngAftercoolerCoolantLevel 1;
BA_ "SPN" SG_ 2432541694 EngVrableGeometryTurboActuator1 641;
BA_ "SigType" SG_ 2432541694 EngVrableGeometryTurboActuator1 1;
BA_ "SPN" SG_ 2432541694 EngTrbCmprssrBypssActtr1TmpStts 5368;
BA_ "SigType" SG_ 2432541694 EngTrbCmprssrBypssActtr1TmpStts 4;
BA_ "SPN" SG_ 2432541694 EngTrbCmprssrBypssActtr1PrlmnryF 5367;
BA_ "SigType" SG_ 2432541694 EngTrbCmprssrBypssActtr1PrlmnryF 1;
BA_ "SystemSignalLongSymbol" SG_ 2432541694 EngTrbCmprssrBypssActtr1PrlmnryF "EngTrbCmprssrBypssActtr1PrlmnryFMI";
BA_ "SPN" SG_ 2432541694 EngTrbCmprssrBypassActuator2Cmd 5369;
BA_ "SigType" SG_ 2432541694 EngTrbCmprssrBypassActuator2Cmd 1;
BA_ "SPN" SG_ 2432541694 EngTrbCmprssrBypassActuator1Pos 3675;
BA_ "SigType" SG_ 2432541694 EngTrbCmprssrBypassActuator1Pos 1;
BA_ "SPN" SG_ 2432541694 EngTrbCmprssrBypassActuator1Cmd 3470;
BA_ "SigType" SG_ 2432541694 EngTrbCmprssrBypassActuator1Cmd 1;
BA_ "SPN" SG_ 2432541694 EngDsrdTrbCmprssrBypssActtr1Pos 5366;
BA_ "SigType" SG_ 2432541694 EngDsrdTrbCmprssrBypssActtr1Pos 1;
BA_ "SPN" SG_ 2566759934 EnableStatusOfDoor10 3441;
BA_ "SigType" SG_ 2566759934 EnableStatusOfDoor10 4;
BA_ "SPN" SG_ 2566759934 OpenStatusOfDoor10 3440;
BA_ "SigType" SG_ 2566759934 OpenStatusOfDoor10 4;
BA_ "SPN" SG_ 2566759934 LockStatusOfDoor10 3439;
BA_ "SigType" SG_ 2566759934 LockStatusOfDoor10 4;
BA_ "SPN" SG_ 2566759934 EnableStatusOfDoor9 3438;
BA_ "SigType" SG_ 2566759934 EnableStatusOfDoor9 4;
BA_ "SPN" SG_ 2566759934 OpenStatusOfDoor9 3437;
BA_ "SigType" SG_ 2566759934 OpenStatusOfDoor9 4;
BA_ "SPN" SG_ 2566759934 LockStatusOfDoor9 3436;
BA_ "SigType" SG_ 2566759934 LockStatusOfDoor9 4;
BA_ "SPN" SG_ 2566759934 EnableStatusOfDoor8 3435;
BA_ "SigType" SG_ 2566759934 EnableStatusOfDoor8 4;
BA_ "SPN" SG_ 2566759934 OpenStatusOfDoor8 3434;
BA_ "SigType" SG_ 2566759934 OpenStatusOfDoor8 4;
BA_ "SPN" SG_ 2566759934 LockStatusOfDoor8 3433;
BA_ "SigType" SG_ 2566759934 LockStatusOfDoor8 4;
BA_ "SPN" SG_ 2566759934 EnableStatusOfDoor7 3432;
BA_ "SigType" SG_ 2566759934 EnableStatusOfDoor7 4;
BA_ "SPN" SG_ 2566759934 OpenStatusOfDoor7 3431;
BA_ "SigType" SG_ 2566759934 OpenStatusOfDoor7 4;
BA_ "SPN" SG_ 2566759934 LockStatusOfDoor7 3430;
BA_ "SigType" SG_ 2566759934 LockStatusOfDoor7 4;
BA_ "SPN" SG_ 2566759934 EnableStatusOfDoor6 3429;
BA_ "SigType" SG_ 2566759934 EnableStatusOfDoor6 4;
BA_ "SPN" SG_ 2566759934 OpenStatusOfDoor6 3428;
BA_ "SigType" SG_ 2566759934 OpenStatusOfDoor6 4;
BA_ "SPN" SG_ 2566759934 LockStatusOfDoor6 3427;
BA_ "SigType" SG_ 2566759934 LockStatusOfDoor6 4;
BA_ "SPN" SG_ 2566759934 EnableStatusOfDoor5 3426;
BA_ "SigType" SG_ 2566759934 EnableStatusOfDoor5 4;
BA_ "SPN" SG_ 2566759934 OpenStatusOfDoor5 3425;
BA_ "SigType" SG_ 2566759934 OpenStatusOfDoor5 4;
BA_ "SPN" SG_ 2566759934 LockStatusOfDoor5 3424;
BA_ "SigType" SG_ 2566759934 LockStatusOfDoor5 4;
BA_ "SPN" SG_ 2566759934 EnableStatusOfDoor4 3423;
BA_ "SigType" SG_ 2566759934 EnableStatusOfDoor4 4;
BA_ "SPN" SG_ 2566759934 OpenStatusOfDoor4 3422;
BA_ "SigType" SG_ 2566759934 OpenStatusOfDoor4 4;
BA_ "SPN" SG_ 2566759934 LockStatusOfDoor4 3421;
BA_ "SigType" SG_ 2566759934 LockStatusOfDoor4 4;
BA_ "SPN" SG_ 2566759934 EnableStatusOfDoor3 3420;
BA_ "SigType" SG_ 2566759934 EnableStatusOfDoor3 4;
BA_ "SPN" SG_ 2566759934 OpenStatusOfDoor3 3419;
BA_ "SigType" SG_ 2566759934 OpenStatusOfDoor3 4;
BA_ "SPN" SG_ 2566759934 LockStatusOfDoor3 3418;
BA_ "SigType" SG_ 2566759934 LockStatusOfDoor3 4;
BA_ "SPN" SG_ 2566759934 EnableStatusOfDoor2 3417;
BA_ "SigType" SG_ 2566759934 EnableStatusOfDoor2 4;
BA_ "SPN" SG_ 2566759934 OpenStatusOfDoor2 3416;
BA_ "SigType" SG_ 2566759934 OpenStatusOfDoor2 4;
BA_ "SPN" SG_ 2566759934 LockStatusOfDoor2 3415;
BA_ "SigType" SG_ 2566759934 LockStatusOfDoor2 4;
BA_ "SPN" SG_ 2566759934 EnableStatusOfDoor1 3414;
BA_ "SigType" SG_ 2566759934 EnableStatusOfDoor1 4;
BA_ "SPN" SG_ 2566759934 OpenStatusOfDoor1 3413;
BA_ "SigType" SG_ 2566759934 OpenStatusOfDoor1 4;
BA_ "SPN" SG_ 2566759934 LockStatusOfDoor1 3412;
BA_ "SigType" SG_ 2566759934 LockStatusOfDoor1 4;
BA_ "SPN" SG_ 2566757374 Aftrtrtmnt1SCRCtlystRgntTmp2Prlm 3519;
BA_ "SigType" SG_ 2566757374 Aftrtrtmnt1SCRCtlystRgntTmp2Prlm 1;
BA_ "SystemSignalLongSymbol" SG_ 2566757374 Aftrtrtmnt1SCRCtlystRgntTmp2Prlm "Aftrtrtmnt1SCRCtlystRgntTmp2PrlmnryFMI";
BA_ "SPN" SG_ 2566757374 Aftrtrtmnt1SCRCtlystRgntPrprtsPr 3520;
BA_ "SigType" SG_ 2566757374 Aftrtrtmnt1SCRCtlystRgntPrprtsPr 1;
BA_ "SystemSignalLongSymbol" SG_ 2566757374 Aftrtrtmnt1SCRCtlystRgntPrprtsPr "Aftrtrtmnt1SCRCtlystRgntPrprtsPrlmnryFMI";
BA_ "SPN" SG_ 2566757374 Aftrtrtmnt1SCRCtlystRgntCndctvty 3518;
BA_ "SigType" SG_ 2566757374 Aftrtrtmnt1SCRCtlystRgntCndctvty 1;
BA_ "SPN" SG_ 2566757374 Aftrtrtmnt1SCRCtlystRgntCncntrtn 3516;
BA_ "SigType" SG_ 2566757374 Aftrtrtmnt1SCRCtlystRgntCncntrtn 1;
BA_ "SPN" SG_ 2566757374 Aftrtrtmnt1SCRCtlystReagentType 3521;
BA_ "SigType" SG_ 2566757374 Aftrtrtmnt1SCRCtlystReagentType 4;
BA_ "SPN" SG_ 2566757374 Aftrtrtmnt1SCRCtlystRagentTemp2 3515;
BA_ "SigType" SG_ 2566757374 Aftrtrtmnt1SCRCtlystRagentTemp2 1;
BA_ "SPN" SG_ 2364546302 RqdGnrtrAvrgLneLineACRMSVoltage 3386;
BA_ "SigType" SG_ 2364546302 RqdGnrtrAvrgLneLineACRMSVoltage 1;
BA_ "SPN" SG_ 2431654654 EngThrottleActuator2CtrlCmd 3465;
BA_ "SigType" SG_ 2431654654 EngThrottleActuator2CtrlCmd 1;
BA_ "SPN" SG_ 2431654654 EngThrottleActuator1CtrlCmd 3464;
BA_ "SigType" SG_ 2431654654 EngThrottleActuator1CtrlCmd 1;
BA_ "SPN" SG_ 2431654654 EngFuelActuator2CtrlCmd 1244;
BA_ "SigType" SG_ 2431654654 EngFuelActuator2CtrlCmd 1;
BA_ "SPN" SG_ 2431654654 EngFuelActuator1CtrlCmd 633;
BA_ "SigType" SG_ 2431654654 EngFuelActuator1CtrlCmd 1;
BA_ "SPN" SG_ 2364545534 EngCyl24KnockLevel 1375;
BA_ "SigType" SG_ 2364545534 EngCyl24KnockLevel 1;
BA_ "SPN" SG_ 2364545534 EngCyl23KnockLevel 1374;
BA_ "SigType" SG_ 2364545534 EngCyl23KnockLevel 1;
BA_ "SPN" SG_ 2364545534 EngCyl22KnockLevel 1373;
BA_ "SigType" SG_ 2364545534 EngCyl22KnockLevel 1;
BA_ "SPN" SG_ 2364545534 EngCyl21KnockLevel 1372;
BA_ "SigType" SG_ 2364545534 EngCyl21KnockLevel 1;
BA_ "SPN" SG_ 2364545534 EngCyl20KnockLevel 1371;
BA_ "SigType" SG_ 2364545534 EngCyl20KnockLevel 1;
BA_ "SPN" SG_ 2364545534 EngCyl19KnockLevel 1370;
BA_ "SigType" SG_ 2364545534 EngCyl19KnockLevel 1;
BA_ "SPN" SG_ 2364545534 EngCyl18KnockLevel 1369;
BA_ "SigType" SG_ 2364545534 EngCyl18KnockLevel 1;
BA_ "SPN" SG_ 2364545534 EngCyl17KnockLevel 1368;
BA_ "SigType" SG_ 2364545534 EngCyl17KnockLevel 1;
BA_ "SPN" SG_ 2364545278 EngCyl15KnockLevel 1366;
BA_ "SigType" SG_ 2364545278 EngCyl15KnockLevel 1;
BA_ "SPN" SG_ 2364545278 EngCyl14KnockLevel 1365;
BA_ "SigType" SG_ 2364545278 EngCyl14KnockLevel 1;
BA_ "SPN" SG_ 2364545278 EngCyl13KnockLevel 1364;
BA_ "SigType" SG_ 2364545278 EngCyl13KnockLevel 1;
BA_ "SPN" SG_ 2364545278 EngCyl12KnockLevel 1363;
BA_ "SigType" SG_ 2364545278 EngCyl12KnockLevel 1;
BA_ "SPN" SG_ 2364545278 EngCyl11KnockLevel 1362;
BA_ "SigType" SG_ 2364545278 EngCyl11KnockLevel 1;
BA_ "SPN" SG_ 2364545278 EngCyl10KnockLevel 1361;
BA_ "SigType" SG_ 2364545278 EngCyl10KnockLevel 1;
BA_ "SPN" SG_ 2364545278 EngCyl9KnockLevel 1360;
BA_ "SigType" SG_ 2364545278 EngCyl9KnockLevel 1;
BA_ "SPN" SG_ 2364545278 EngCyl16KnockLevel 1367;
BA_ "SigType" SG_ 2364545278 EngCyl16KnockLevel 1;
BA_ "SPN" SG_ 2364545022 EngCyl8KnockLevel 1359;
BA_ "SigType" SG_ 2364545022 EngCyl8KnockLevel 1;
BA_ "SPN" SG_ 2364545022 EngCyl7KnockLevel 1358;
BA_ "SigType" SG_ 2364545022 EngCyl7KnockLevel 1;
BA_ "SPN" SG_ 2364545022 EngCyl6KnockLevel 1357;
BA_ "SigType" SG_ 2364545022 EngCyl6KnockLevel 1;
BA_ "SPN" SG_ 2364545022 EngCyl5KnockLevel 1356;
BA_ "SigType" SG_ 2364545022 EngCyl5KnockLevel 1;
BA_ "SPN" SG_ 2364545022 EngCyl4KnockLevel 1355;
BA_ "SigType" SG_ 2364545022 EngCyl4KnockLevel 1;
BA_ "SPN" SG_ 2364545022 EngCyl3KnockLevel 1354;
BA_ "SigType" SG_ 2364545022 EngCyl3KnockLevel 1;
BA_ "SPN" SG_ 2364545022 EngCyl2KnockLevel 1353;
BA_ "SigType" SG_ 2364545022 EngCyl2KnockLevel 1;
BA_ "SPN" SG_ 2364545022 EngCyl1KnockLevel 1352;
BA_ "SigType" SG_ 2364545022 EngCyl1KnockLevel 1;
BA_ "SPN" SG_ 2364544766 EngCyl9CombustionStatus 3395;
BA_ "SigType" SG_ 2364544766 EngCyl9CombustionStatus 4;
BA_ "SPN" SG_ 2364544766 EngCyl8CombustionStatus 3394;
BA_ "SigType" SG_ 2364544766 EngCyl8CombustionStatus 4;
BA_ "SPN" SG_ 2364544766 EngCyl7CombustionStatus 3393;
BA_ "SigType" SG_ 2364544766 EngCyl7CombustionStatus 4;
BA_ "SPN" SG_ 2364544766 EngCyl6CombustionStatus 3392;
BA_ "SigType" SG_ 2364544766 EngCyl6CombustionStatus 4;
BA_ "SPN" SG_ 2364544766 EngCyl5CombustionStatus 3391;
BA_ "SigType" SG_ 2364544766 EngCyl5CombustionStatus 4;
BA_ "SPN" SG_ 2364544766 EngCyl4CombustionStatus 3390;
BA_ "SigType" SG_ 2364544766 EngCyl4CombustionStatus 4;
BA_ "SPN" SG_ 2364544766 EngCyl3CombustionStatus 3389;
BA_ "SigType" SG_ 2364544766 EngCyl3CombustionStatus 4;
BA_ "SPN" SG_ 2364544766 EngCyl2CombustionStatus 3388;
BA_ "SigType" SG_ 2364544766 EngCyl2CombustionStatus 4;
BA_ "SPN" SG_ 2364544766 EngCyl24CombustionStatus 3410;
BA_ "SigType" SG_ 2364544766 EngCyl24CombustionStatus 4;
BA_ "SPN" SG_ 2364544766 EngCyl23CombustionStatus 3409;
BA_ "SigType" SG_ 2364544766 EngCyl23CombustionStatus 4;
BA_ "SPN" SG_ 2364544766 EngCyl22CombustionStatus 3408;
BA_ "SigType" SG_ 2364544766 EngCyl22CombustionStatus 4;
BA_ "SPN" SG_ 2364544766 EngCyl21CombustionStatus 3407;
BA_ "SigType" SG_ 2364544766 EngCyl21CombustionStatus 4;
BA_ "SPN" SG_ 2364544766 EngCyl20CombustionStatus 3406;
BA_ "SigType" SG_ 2364544766 EngCyl20CombustionStatus 4;
BA_ "SPN" SG_ 2364544766 EngCyl1CombustionStatus 3387;
BA_ "SigType" SG_ 2364544766 EngCyl1CombustionStatus 4;
BA_ "SPN" SG_ 2364544766 EngCyl19CombustionStatus 3405;
BA_ "SigType" SG_ 2364544766 EngCyl19CombustionStatus 4;
BA_ "SPN" SG_ 2364544766 EngCyl18CombustionStatus 3404;
BA_ "SigType" SG_ 2364544766 EngCyl18CombustionStatus 4;
BA_ "SPN" SG_ 2364544766 EngCyl17CombustionStatus 3403;
BA_ "SigType" SG_ 2364544766 EngCyl17CombustionStatus 4;
BA_ "SPN" SG_ 2364544766 EngCyl16CombustionStatus 3402;
BA_ "SigType" SG_ 2364544766 EngCyl16CombustionStatus 4;
BA_ "SPN" SG_ 2364544766 EngCyl15CombustionStatus 3401;
BA_ "SigType" SG_ 2364544766 EngCyl15CombustionStatus 4;
BA_ "SPN" SG_ 2364544766 EngCyl14CombustionStatus 3400;
BA_ "SigType" SG_ 2364544766 EngCyl14CombustionStatus 4;
BA_ "SPN" SG_ 2364544766 EngCyl13CombustionStatus 3399;
BA_ "SigType" SG_ 2364544766 EngCyl13CombustionStatus 4;
BA_ "SPN" SG_ 2364544766 EngCyl12CombustionStatus 3398;
BA_ "SigType" SG_ 2364544766 EngCyl12CombustionStatus 4;
BA_ "SPN" SG_ 2364544766 EngCyl11CombustionStatus 3397;
BA_ "SigType" SG_ 2364544766 EngCyl11CombustionStatus 4;
BA_ "SPN" SG_ 2364544766 EngCyl10CombustionStatus 3396;
BA_ "SigType" SG_ 2364544766 EngCyl10CombustionStatus 4;
BA_ "SPN" SG_ 2364544510 RqGenOverallPowerFactorLagging 3385;
BA_ "SigType" SG_ 2364544510 RqGenOverallPowerFactorLagging 4;
BA_ "SPN" SG_ 2364544510 RqGeneratorOverallPowerFactor 3384;
BA_ "SigType" SG_ 2364544510 RqGeneratorOverallPowerFactor 1;
BA_ "SPN" SG_ 2364544510 RqGeneratorTotalACReactivePower 3383;
BA_ "SigType" SG_ 2364544510 RqGeneratorTotalACReactivePower 1;
BA_ "SPN" SG_ 2364544254 RltvBldHghtAndBldRttnAnglMsrmntL 3366;
BA_ "SigType" SG_ 2364544254 RltvBldHghtAndBldRttnAnglMsrmntL 1;
BA_ "SystemSignalLongSymbol" SG_ 2364544254 RltvBldHghtAndBldRttnAnglMsrmntL "RltvBldHghtAndBldRttnAnglMsrmntLtncy";
BA_ "SPN" SG_ 2364544254 RlativeBladeHeightFigureOfMerit 3367;
BA_ "SigType" SG_ 2364544254 RlativeBladeHeightFigureOfMerit 4;
BA_ "SPN" SG_ 2364544254 BladeRotationAngleFigureOfMerit 3332;
BA_ "SigType" SG_ 2364544254 BladeRotationAngleFigureOfMerit 4;
BA_ "SPN" SG_ 2364544254 BladeRotationAngle 3331;
BA_ "SigType" SG_ 2364544254 BladeRotationAngle 1;
BA_ "SPN" SG_ 2364544254 RelativeBladeHeight 3365;
BA_ "SigType" SG_ 2364544254 RelativeBladeHeight 1;
BA_ "SigType" SG_ 2348992544 BrakeLightSwitch 4;
BA_ "SigType" SG_ 2348992544 ASREngineControlActive 4;
BA_ "SigType" SG_ 2348992544 ASRBreakControlActive 4;
BA_ "SigType" SG_ 2348992544 VehicleRetarderCtrlActive 4;
BA_ "SigType" SG_ 2348992544 VehicleABSActive 4;
BA_ "SPN" SG_ 2566834464 RoadCurvature 1591;
BA_ "SigType" SG_ 2566834464 RoadCurvature 1;
BA_ "SigType" SG_ 2566834464 PneumaticControlLine 4;
BA_ "SigType" SG_ 2566834464 ABSOffroadRequest 4;
BA_ "SigType" SG_ 2566834464 TwoElCircuitsBrakeDemand 4;
BA_ "SigType" SG_ 2566834464 VehicleRetarderCtrlActive 4;
BA_ "SigType" SG_ 2550341832 ActualRetarderPercTorque 1;
BA_ "SigType" SG_ 2550341832 Wheel_BasedVehicleSpeed 1;
BA_ "SigType" SG_ 2550341832 SupplyLineBrakingRequest 4;
BA_ "SigType" SG_ 2550341832 VDCActive 4;
BA_ "SigType" SG_ 2550341832 AutomTowedVehBreakActive 4;
BA_ "SigType" SG_ 2550341832 VehicleServiceBrakeActive 4;
BA_ "SigType" SG_ 2550341832 VehicleRetarderCtrlActive 4;
BA_ "SigType" SG_ 2550341832 VehicleABSActive 4;
BA_ "SPN" SG_ 2566833352 ReferenceRetarderTorque 556;
BA_ "SigType" SG_ 2566833352 ReferenceRetarderTorque 1;
BA_ "SigType" SG_ 2566833352 SupplyLineBrakingRequest 4;
BA_ "SigType" SG_ 2566833352 LoadingRampApproachAssist 4;
BA_ "SigType" SG_ 2566833352 SpringBrakeEngaged 4;
BA_ "SigType" SG_ 2566833352 ElectrLoadPropFunc 4;
BA_ "SigType" SG_ 2566833352 SpringBrakeInstalled 4;
BA_ "SigType" SG_ 2566833352 ElecSupplyOfNonBrakingSys 4;
BA_ "SigType" SG_ 2566833352 AmberWarningSignalReq 4;
BA_ "SigType" SG_ 2566833352 RedWarningSignalRequest 4;
BA_ "SigType" SG_ 2566833352 VehicleElectrSupplySuff 4;
BA_ "SigType" SG_ 2566833352 AutomTowedVehBreakActive 4;
BA_ "SigType" SG_ 2566833352 VehicleServiceBrakeActive 4;
BA_ "SigType" SG_ 2566833352 VehicleRetarderCtrlActive 4;
BA_ "SigType" SG_ 2566833352 VehicleABSActive 4;
BA_ "SigType" SG_ 2365507272 VehiclePneumSupplySuff 4;
BA_ "SigType" SG_ 2365507272 BrakeTemperatureStatus 4;
BA_ "SigType" SG_ 2365507272 BrakeLiningSufficient 4;
BA_ "SigType" SG_ 2365507272 TyrePressureSufficient 4;
BA_ "SigType" SG_ 2565013246 ODDRequest 4;
BA_ "SigType" SG_ 2565013246 AntiTheftDeviceReq 4;
BA_ "SPN" SG_ 2566807038 MaxVehicleSpeedLimit 74;
BA_ "SigType" SG_ 2566807038 MaxVehicleSpeedLimit 1;
BA_ "SigType" SG_ 2365480958 VehicleSpeed 1;
BA_ "SigType" SG_ 2365480958 PercentLoadAtCurrentSpeed 1;
BA_ "SigType" SG_ 2365480958 EngineSpeed 1;
BA_ "SigType" SG_ 2365480958 ActualEngine_PercTorque 1;
BA_ "SigType" SG_ 2365480958 DriversDemandEngine_PercTorque 1;
BA_ "SigType" SG_ 2365480958 EngineRunning 4;
BA_ "SigType" SG_ 2365480958 EngineControlAllowed 4;
BA_ "SigType" SG_ 2566808062 ClutchIndptdPTOFeedback 4;
BA_ "SigType" SG_ 2566808062 AccelPedalPosition 1;
BA_ "SigType" SG_ 2566808062 AccelPedalLowIdleSwitch 4;
BA_ "SigType" SG_ 2566808062 StarterActive 4;
BA_ "SigType" SG_ 2566808062 PTOControlAllowed 4;
BA_ "SigType" SG_ 2566808062 SecEngineMtdPTOFeedback 4;
BA_ "SigType" SG_ 2566808062 FirstEngineMtdPTOFeedback 4;
BA_ "SigType" SG_ 2566808062 SecClutchDptdPTOFeedback 4;
BA_ "SigType" SG_ 2566808062 FirstClutchDpdtPTOFeedback 4;
BA_ "SigType" SG_ 2566808062 CurrentGear 1;
BA_ "SPN" SG_ 2566808062 PercentClutchSlip 522;
BA_ "SigType" SG_ 2566808062 PercentClutchSlip 1;
BA_ "SigType" SG_ 2566808574 ReferenceEngineTorque 1;
BA_ "SigType" SG_ 2566808574 FuelLevelWarning 4;
BA_ "SigType" SG_ 2566808574 EngineOilPressureWarning 4;
BA_ "SigType" SG_ 2566808574 EngineOilPressure 1;
BA_ "SPN" SG_ 2566808574 EngineCoolantTemperature 110;
BA_ "SigType" SG_ 2566808574 EngineCoolantTemperature 1;
BA_ "SigType" SG_ 2566808574 EngineOilTemperature 1;
BA_ "SigType" SG_ 2566809086 AmbientAirTemperature 1;
BA_ "SigType" SG_ 2566834430 AntiTheftDeviceStatus 4;
BA_ "SigType" SG_ 2566834430 ODDStatus 4;
BA_ "SigType" SG_ 2566808318 SecEngineMtdPTOSwitch 4;
BA_ "SigType" SG_ 2566808318 SecClutchDpdtPTOSwitch 4;
BA_ "SigType" SG_ 2566808318 FirstClutchDpdtPTOSwitch 4;
BA_ "SigType" SG_ 2566808318 OperatingPanelActive 4;
BA_ "SigType" SG_ 2566808318 RefusePackerStepSwitch 4;
BA_ "SigType" SG_ 2566808318 EngineStopSwitch 4;
BA_ "SigType" SG_ 2566808318 EngineStartSwitch 4;
BA_ "SigType" SG_ 2566808318 StarterLockoutSwitch 4;
BA_ "SigType" SG_ 2566808318 RqstedPercentClutchSlip 1;
BA_ "SigType" SG_ 2566808318 FirstEngineMtdPTOSwitch 4;
BA_ "SigType" SG_ 2566808318 ClutchIndpdtPTOSwitch 4;
BA_ "SigType" SG_ 2566808830 TrailerLeftSideMarkerLight 4;
BA_ "SigType" SG_ 2566808830 TrailerLeftReversingLight 4;
BA_ "SigType" SG_ 2566808830 TrailerLeftRearWidIndLight 4;
BA_ "SigType" SG_ 2566808830 TrailerLeftRearRegPltLight 4;
BA_ "SigType" SG_ 2566808830 TrailerLeftRearLight 4;
BA_ "SigType" SG_ 2566808830 TrailerLeftRearFogLight 4;
BA_ "SigType" SG_ 2566808830 TrailerLeftDirIndLight 4;
BA_ "SigType" SG_ 2566808830 TrailerLeftCrnMarkerLight 4;
BA_ "SigType" SG_ 2566808830 TrailerInteriorLight 4;
BA_ "SigType" SG_ 2566808830 TrailerWorkLamp 4;
BA_ "SigType" SG_ 2566808830 TrailerRotatingIdentLight 4;
BA_ "SigType" SG_ 2566808830 TrailerRightStopLight 4;
BA_ "SigType" SG_ 2566808830 TrailerRightSideMrkLight 4;
BA_ "SigType" SG_ 2566808830 TrailerRightReversingLight 4;
BA_ "SigType" SG_ 2566808830 TrailRightRearWidIndLight 4;
BA_ "SigType" SG_ 2566808830 TrailerRightRearRegPltLight 4;
BA_ "SigType" SG_ 2566808830 TrailerRightRearLight 4;
BA_ "SigType" SG_ 2566808830 TrailerRightRearFogLight 4;
BA_ "SigType" SG_ 2566808830 TrailerRightDirIndLight 4;
BA_ "SigType" SG_ 2566808830 TrailerRightCrnMarkerLight 4;
BA_ "SigType" SG_ 2566808830 TrailerRearWarningLight 4;
BA_ "SigType" SG_ 2566808830 TrailerLeftStopLight 4;
BA_ "SigType" SG_ 2565734142 ControlByte 1;
BA_ "SigType" SG_ 2565734142 FilterMode 1;
BA_ "SigType" SG_ 2565130272 ParkingAndTrailerAirPress 1;
BA_ "SigType" SG_ 2565130272 StopLevelChangeReq 4;
BA_ "SigType" SG_ 2565130272 RampLevelStorageReq 4;
BA_ "SigType" SG_ 2565130272 LevelControlReq 4;
BA_ "SigType" SG_ 2565130272 RampLevelReq 4;
BA_ "SigType" SG_ 2565130272 SteeringAxleLockingReq 4;
BA_ "SigType" SG_ 2565130272 LiftAxle2PositionReq 4;
BA_ "SigType" SG_ 2565130272 LiftAxle1PositionReq 4;
BA_ "SigType" SG_ 2565130272 TractionHelpReq 4;
BA_ "SigType" SG_ 2565130272 LevelChangeReqRearAxle 4;
BA_ "SigType" SG_ 2565130272 LevelChangeReqFrontAxle 4;
BA_ "SigType" SG_ 2565130272 RideHeightRequest_RGE11 4;
BA_ "SigType" SG_ 2565209854 LevelControl 4;
BA_ "SigType" SG_ 2565209854 RampLevel 4;
BA_ "SigType" SG_ 2565209854 NormalLevel 4;
BA_ "SigType" SG_ 2565209854 StopLevelChangeAcknowledge 4;
BA_ "SigType" SG_ 2565209854 LevelChangeRearAxle 4;
BA_ "SigType" SG_ 2565209854 LevelChangeFrontAxle 4;
BA_ "SigType" SG_ 2565209854 RampLevelStorage 4;
BA_ "SigType" SG_ 2565209854 SteeringAxleLocking 4;
BA_ "SPN" SG_ 2565209854 LiftAxle2Pos 1822;
BA_ "SigType" SG_ 2565209854 LiftAxle2Pos 4;
BA_ "SPN" SG_ 2565209854 LiftAxle1Pos 1743;
BA_ "SigType" SG_ 2565209854 LiftAxle1Pos 4;
BA_ "SigType" SG_ 2565209854 RampLevelPosition 4;
BA_ "SigType" SG_ 2565209854 TractionHelp 4;
BA_ "SigType" SG_ 2565209854 LevelCtrlSysRideHeightLevel 4;
BA_ "SigType" SG_ 2566807294 TyreModulePowerSupply 4;
BA_ "SystemSignalLongSymbol" SG_ 2566764798 NOxConvertingCatalystAdsorberCom "NOxConvertingCatalystAdsorberCompleted";
BA_ "SystemSignalLongSymbol" SG_ 2566764798 NOxConvertingCatalystAdsorberEna "NOxConvertingCatalystAdsorberEnabled";
BA_ "SystemSignalLongSymbol" SG_ 2566764798 BoostPressureControlSystemComple "BoostPressureControlSystemCompleted";
BA_ "SPN" SG_ 2566764798 MisfireMonitoringComplete 3152;
BA_ "SPN" SG_ 2566764798 MisfireMonitoringEnabled 3152;
BA_ "SPN" SG_ 2566764798 FuelSystemMonitoringEnabled 3152;
BA_ "SPN" SG_ 2566764798 ComprehensiveComptMonComplete 3152;
BA_ "SPN" SG_ 2566764798 ComprehensiveCompMonEnabled 3152;
BA_ "SPN" SG_ 2566764798 SecondAirSystemMonComplete 3153;
BA_ "SPN" SG_ 2566764798 SecondAirSystemMonEnabled 3153;
BA_ "SPN" SG_ 2566764798 OxygenSensorMonComplete 3154;
BA_ "SPN" SG_ 2566764798 OxygenSensorMonEnabled 3153;
BA_ "SPN" SG_ 2566764798 OxygenSensorHeaterMonComplete 3154;
BA_ "SPN" SG_ 2566764798 OxygenSensorHeaterMonEnabled 3153;
BA_ "SPN" SG_ 2566764798 HeatedCatalystMonComplete 3154;
BA_ "SPN" SG_ 2566764798 HeatedCatalystMonEnabled 3153;
BA_ "SPN" SG_ 2566764798 EvaporativeSystemMonComplete 3154;
BA_ "SPN" SG_ 2566764798 EvaporativeSystemMonEnabled 3153;
BA_ "SPN" SG_ 2566764798 EGRSystemMonitoringComplete 3154;
BA_ "SPN" SG_ 2566764798 EGRSystemMonitoringEnabled 3153;
BA_ "SPN" SG_ 2566764798 ColdStartAidSystemMonComplete 3154;
BA_ "SPN" SG_ 2566764798 ColdStartAidSystemMonEnabled 3153;
BA_ "SPN" SG_ 2566764798 CatalystMonComplete 3153;
BA_ "SPN" SG_ 2566764798 CatalystMonEnabled 3153;
BA_ "SPN" SG_ 2566764798 ACSystemRefrigerantMonComplete 3153;
BA_ "SPN" SG_ 2566764798 ACSystemRefrigerantMonEnabled 3153;
BA_ "SPN" SG_ 2566764798 FuelSystemMonitoringComplete 3152;
BA_ "SPN" SG_ 2566764798 NumOfWarmUpsSinceDTCsCleared 3151;
BA_ "SPN" SG_ 2566764798 TimeSinceEngineStart 3150;
BA_ "SPN" SG_ 2564095742 SecurityEntityLengthHigh 1596;
BA_ "SPN" SG_ 2564095742 SecurityEntityType 1479;
BA_ "SPN" SG_ 2564095742 SecurityEntityLength 1596;
BA_ "SPN" SG_ 2349137662 XBRMessageChecksum 3188;
BA_ "SigType" SG_ 2349137662 XBRMessageChecksum 4;
BA_ "SPN" SG_ 2349137662 XBRMessageCounter 3189;
BA_ "SigType" SG_ 2349137662 XBRMessageCounter 4;
BA_ "SPN" SG_ 2349137662 XBRCtrlMode 2916;
BA_ "SigType" SG_ 2349137662 XBRCtrlMode 4;
BA_ "SPN" SG_ 2349137662 XBRPriority 2915;
BA_ "SigType" SG_ 2349137662 XBRPriority 4;
BA_ "SPN" SG_ 2349137662 XBREBIMode 2914;
BA_ "SigType" SG_ 2349137662 XBREBIMode 4;
BA_ "SPN" SG_ 2349137662 ExtlAccelerationDemand 2920;
BA_ "SigType" SG_ 2349137662 ExtlAccelerationDemand 1;
BA_ "SPN" SG_ 2349137662 XBRUrgency 4099;
BA_ "SigType" SG_ 2349137662 XBRUrgency 1;
BA_ "SPN" SG_ 2566848510 WaterInFuelIndicator 97;
BA_ "SigType" SG_ 2566848510 WaterInFuelIndicator 4;
BA_ "SPN" SG_ 2566842927 AxleLocation 928;
BA_ "SigType" SG_ 2566842927 AxleLocation 1;
BA_ "SPN" SG_ 2566842927 CargoWeight_30 522230;
BA_ "SigType" SG_ 2566842927 CargoWeight_30 1;
BA_ "SPN" SG_ 2566842927 CargoWeight_20 522220;
BA_ "SigType" SG_ 2566842927 CargoWeight_20 1;
BA_ "SPN" SG_ 2566842927 CargoWeight_10 522210;
BA_ "SigType" SG_ 2566842927 CargoWeight_10 1;
BA_ "SPN" SG_ 2566842927 CargoWeight_00 522200;
BA_ "SigType" SG_ 2566842927 CargoWeight_00 1;
BA_ "SPN" SG_ 2566842927 TrailerWeight_30 522130;
BA_ "SigType" SG_ 2566842927 TrailerWeight_30 1;
BA_ "SPN" SG_ 2566842927 TrailerWeight_20 522120;
BA_ "SigType" SG_ 2566842927 TrailerWeight_20 1;
BA_ "SPN" SG_ 2566842927 TrailerWeight_10 522110;
BA_ "SigType" SG_ 2566842927 TrailerWeight_10 1;
BA_ "SPN" SG_ 2566842927 TrailerWeight_00 522100;
BA_ "SigType" SG_ 2566842927 TrailerWeight_00 1;
BA_ "SPN" SG_ 2566842927 AxleWeight_00 522000;
BA_ "SigType" SG_ 2566842927 AxleWeight_00 1;
BA_ "SPN" SG_ 2566804222 NetBatteryCurrentHiRes 2579;
BA_ "SigType" SG_ 2566804222 NetBatteryCurrentHiRes 1;
BA_ "SPN" SG_ 2566804222 AltCurrentHiRes 1795;
BA_ "SigType" SG_ 2566804222 AltCurrentHiRes 1;
BA_ "SPN" SG_ 2633928190 ECUPowerOutputSupplyVoltage3 3599;
BA_ "SigType" SG_ 2633928190 ECUPowerOutputSupplyVoltage3 1;
BA_ "SPN" SG_ 2633928190 ECUPowerOutputSupplyVoltage2 3598;
BA_ "SigType" SG_ 2633928190 ECUPowerOutputSupplyVoltage2 1;
BA_ "SPN" SG_ 2633928190 ECUPowerOutputSupplyVoltage1 3597;
BA_ "SigType" SG_ 2633928190 ECUPowerOutputSupplyVoltage1 1;
BA_ "SPN" SG_ 2633928190 BatteryPotential_PowerInput2 444;
BA_ "SigType" SG_ 2633928190 BatteryPotential_PowerInput2 1;
BA_ "SPN" SG_ 2566845438 Longitude 585;
BA_ "SigType" SG_ 2566845438 Longitude 1;
BA_ "SPN" SG_ 2566845438 Latitude 584;
BA_ "SigType" SG_ 2566845438 Latitude 1;
BA_ "SPN" SG_ 2566843646 VehicleIdentificationNumber 237;
BA_ "SigType" SG_ 2566843646 VehicleIdentificationNumber 8;
BA_ "SPN" SG_ 2566842112 TotalPowerTakeoffHours 248;
BA_ "SigType" SG_ 2566842112 TotalPowerTakeoffHours 1;
BA_ "SPN" SG_ 2566842112 TotalVehicleHours 246;
BA_ "SigType" SG_ 2566842112 TotalVehicleHours 1;
BA_ "SPN" SG_ 2566809854 WinchOilPressSwitch 1857;
BA_ "SigType" SG_ 2566809854 WinchOilPressSwitch 4;
BA_ "SPN" SG_ 2566809854 HydOilLevel 2602;
BA_ "SigType" SG_ 2566809854 HydOilLevel 1;
BA_ "SPN" SG_ 2566809854 HydOilFilterRestrictionSwitch 1713;
BA_ "SigType" SG_ 2566809854 HydOilFilterRestrictionSwitch 4;
BA_ "SPN" SG_ 2566809854 HydTemp 1638;
BA_ "SigType" SG_ 2566809854 HydTemp 1;
BA_ "SPN" SG_ 2566842622 Altitude 580;
BA_ "SigType" SG_ 2566842622 Altitude 1;
BA_ "SPN" SG_ 2566842622 Pitch 583;
BA_ "SigType" SG_ 2566842622 Pitch 1;
BA_ "SPN" SG_ 2566842622 NavigationBasedVehicleSpeed 517;
BA_ "SigType" SG_ 2566842622 NavigationBasedVehicleSpeed 1;
BA_ "SPN" SG_ 2566842622 CompassBearing 165;
BA_ "SigType" SG_ 2566842622 CompassBearing 1;
BA_ "SPN" SG_ 2566832638 HighResolutionTripDistance 918;
BA_ "SigType" SG_ 2566832638 HighResolutionTripDistance 1;
BA_ "SPN" SG_ 2566832638 HghRslutionTotalVehicleDistance 917;
BA_ "SigType" SG_ 2566832638 HghRslutionTotalVehicleDistance 1;
BA_ "SPN" SG_ 2565867787 SteerWheelAngleSensorType 1812;
BA_ "SigType" SG_ 2565867787 SteerWheelAngleSensorType 4;
BA_ "SPN" SG_ 2565867787 SteerWheelAngle 1807;
BA_ "SigType" SG_ 2565867787 SteerWheelAngle 1;
BA_ "SPN" SG_ 2565867787 LongitudinalAcceleration 1810;
BA_ "SigType" SG_ 2565867787 LongitudinalAcceleration 1;
BA_ "SPN" SG_ 2565867787 LateralAcceleration 1809;
BA_ "SigType" SG_ 2565867787 LateralAcceleration 1;
BA_ "SPN" SG_ 2565867787 YawRate 1808;
BA_ "SigType" SG_ 2565867787 YawRate 1;
BA_ "SPN" SG_ 2565867787 SteerWheelTurnCounter 1811;
BA_ "SPN" SG_ 2566803211 YCBrakeCtrlActive 1819;
BA_ "SigType" SG_ 2566803211 YCBrakeCtrlActive 4;
BA_ "SPN" SG_ 2566803211 YCEngCtrlActive 1817;
BA_ "SigType" SG_ 2566803211 YCEngCtrlActive 4;
BA_ "SPN" SG_ 2566803211 ROPBrakeCtrlActive 1818;
BA_ "SigType" SG_ 2566803211 ROPBrakeCtrlActive 4;
BA_ "SPN" SG_ 2566803211 ROPEngCtrlActive 1816;
BA_ "SigType" SG_ 2566803211 ROPEngCtrlActive 4;
BA_ "SPN" SG_ 2566803211 VDCBrakeLightRq 1815;
BA_ "SigType" SG_ 2566803211 VDCBrakeLightRq 4;
BA_ "SPN" SG_ 2566803211 VDCFullyOperational 1814;
BA_ "SigType" SG_ 2566803211 VDCFullyOperational 4;
BA_ "SPN" SG_ 2566803211 VDCInformationSignal 1813;
BA_ "SigType" SG_ 2566803211 VDCInformationSignal 4;
BA_ "SPN" SG_ 2566840574 TotalVehicleDistance 245;
BA_ "SigType" SG_ 2566840574 TotalVehicleDistance 1;
BA_ "SPN" SG_ 2566840574 TripDistance 244;
BA_ "SigType" SG_ 2566840574 TripDistance 1;
BA_ "SPN" SG_ 2633938686 TripCruiseDistance 1019;
BA_ "SigType" SG_ 2633938686 TripCruiseDistance 1;
BA_ "SPN" SG_ 2633938686 TripMaxVehicleSpeed 1018;
BA_ "SigType" SG_ 2633938686 TripMaxVehicleSpeed 1;
BA_ "SPN" SG_ 2633937150 TripAirCompressorOnTime 1038;
BA_ "SigType" SG_ 2633937150 TripAirCompressorOnTime 1;
BA_ "SPN" SG_ 2633937150 TripIdleTime 1037;
BA_ "SigType" SG_ 2633937150 TripIdleTime 1;
BA_ "SPN" SG_ 2633937150 TripEngRunningTime 1036;
BA_ "SigType" SG_ 2633937150 TripEngRunningTime 1;
BA_ "SPN" SG_ 2633937150 TripCruiseTime 1034;
BA_ "SigType" SG_ 2633937150 TripCruiseTime 1;
BA_ "SPN" SG_ 2633937150 TripPTOGovernorTime 1035;
BA_ "SigType" SG_ 2633937150 TripPTOGovernorTime 1;
BA_ "SPN" SG_ 2633938174 TripTimeInDerateByEng 1027;
BA_ "SigType" SG_ 2633938174 TripTimeInDerateByEng 1;
BA_ "SPN" SG_ 2633938174 TripTimeInGearDown 1026;
BA_ "SigType" SG_ 2633938174 TripTimeInGearDown 1;
BA_ "SPN" SG_ 2633938174 TripTimeInTopGear 1025;
BA_ "SigType" SG_ 2633938174 TripTimeInTopGear 1;
BA_ "SPN" SG_ 2633938174 TripTimeInVSL 1024;
BA_ "SigType" SG_ 2633938174 TripTimeInVSL 1;
BA_ "SPN" SG_ 2633938430 TripSuddenDecelerations 1023;
BA_ "SigType" SG_ 2633938430 TripSuddenDecelerations 1;
BA_ "SPN" SG_ 2633938430 TrpNmberOfIdleShutdownOverrides 1022;
BA_ "SigType" SG_ 2633938430 TrpNmberOfIdleShutdownOverrides 1;
BA_ "SPN" SG_ 2633938430 TripNumberOfIdleShutdowns 1021;
BA_ "SigType" SG_ 2633938430 TripNumberOfIdleShutdowns 1;
BA_ "SPN" SG_ 2633938430 TripNumberOfHotShutdowns 1020;
BA_ "SigType" SG_ 2633938430 TripNumberOfHotShutdowns 1;
BA_ "SPN" SG_ 2348814347 EngRqedTorque_TorqueLimit_Int 518;
BA_ "SigType" SG_ 2348814347 EngRqedTorque_TorqueLimit_Int 1;
BA_ "SPN" SG_ 2348814347 EngRqedSpeed_SpeedLimit_Int 898;
BA_ "SigType" SG_ 2348814347 EngRqedSpeed_SpeedLimit_Int 1;
BA_ "SPN" SG_ 2348814347 OverrideCtrlModePriority_Int 897;
BA_ "SPN" SG_ 2348814347 EngRqedSpeedCtrlConditions_Int 696;
BA_ "SPN" SG_ 2348814347 EngOverrideCtrlMode_Int 695;
BA_ "SPN" SG_ 2566766846 TransitRunStatus 3046;
BA_ "SigType" SG_ 2566766846 TransitRunStatus 4;
BA_ "SPN" SG_ 2566766846 VehicleUseStatus 3045;
BA_ "SigType" SG_ 2566766846 VehicleUseStatus 4;
BA_ "SPN" SG_ 2566766846 SilentAlarmStatus 3044;
BA_ "SigType" SG_ 2566766846 SilentAlarmStatus 4;
BA_ "SPN" SG_ 2566766846 PatronCount 3047;
BA_ "SigType" SG_ 2566766846 PatronCount 1;
BA_ "SPN" SG_ 2566766846 TypeOfPassengerCount 3043;
BA_ "SigType" SG_ 2566766846 TypeOfPassengerCount 1;
BA_ "SPN" SG_ 2566765310 FareboxAlarmIdentifier 3181;
BA_ "SPN" SG_ 2566765310 FareboxEmergencyStatus 3179;
BA_ "SigType" SG_ 2566765310 FareboxEmergencyStatus 4;
BA_ "SPN" SG_ 2566765566 TransferSold 3168;
BA_ "SigType" SG_ 2566765566 TransferSold 1;
BA_ "SPN" SG_ 2566765566 RouteNumber 3169;
BA_ "SigType" SG_ 2566765566 RouteNumber 1;
BA_ "SPN" SG_ 2566765566 TransferType 3173;
BA_ "SPN" SG_ 2566765566 TypeOfService 3172;
BA_ "SPN" SG_ 2566765566 InitialFareAgency 3167;
BA_ "SPN" SG_ 2566765566 PassCategory 3166;
BA_ "SigType" SG_ 2566765566 PassCategory 4;
BA_ "SPN" SG_ 2566765566 FareValidity 3165;
BA_ "SigType" SG_ 2566765566 FareValidity 4;
BA_ "SPN" SG_ 2566765566 PaymentDetails 3177;
BA_ "SigType" SG_ 2566765566 PaymentDetails 4;
BA_ "SPN" SG_ 2566765566 TypeOfFare 3176;
BA_ "SigType" SG_ 2566765566 TypeOfFare 4;
BA_ "SPN" SG_ 2566765566 PassengerType 3171;
BA_ "SigType" SG_ 2566765566 PassengerType 4;
BA_ "SPN" SG_ 2566765566 TransactionType 3170;
BA_ "SigType" SG_ 2566765566 TransactionType 4;
BA_ "SPN" SG_ 2566765822 DriversFareboxSecurityCode 3164;
BA_ "SigType" SG_ 2566765822 DriversFareboxSecurityCode 1;
BA_ "SPN" SG_ 2566765822 AssignedBlock 3163;
BA_ "SigType" SG_ 2566765822 AssignedBlock 1;
BA_ "SPN" SG_ 2566765822 AssignedRun 3162;
BA_ "SigType" SG_ 2566765822 AssignedRun 1;
BA_ "SPN" SG_ 2566765822 AssignedRoute 3160;
BA_ "SigType" SG_ 2566765822 AssignedRoute 1;
BA_ "SPN" SG_ 2566765822 PatternNumber 3161;
BA_ "SigType" SG_ 2566765822 PatternNumber 1;
BA_ "SPN" SG_ 2566765822 TripNumber 3159;
BA_ "SigType" SG_ 2566765822 TripNumber 1;
BA_ "SPN" SG_ 2566765822 FarePresets 3175;
BA_ "SigType" SG_ 2566765822 FarePresets 1;
BA_ "SPN" SG_ 2566765822 TripDirection 3174;
BA_ "SigType" SG_ 2566765822 TripDirection 4;
BA_ "SPN" SG_ 2566765822 TripStatus 3180;
BA_ "SPN" SG_ 2566765822 FareboxServiceStatus 3178;
BA_ "SigType" SG_ 2566765822 FareboxServiceStatus 4;
BA_ "SPN" SG_ 2566766078 VehicleID 3085;
BA_ "SigType" SG_ 2566766078 VehicleID 1;
BA_ "SPN" SG_ 2566766078 StrobeActivationCtrlStatus 3082;
BA_ "SigType" SG_ 2566766078 StrobeActivationCtrlStatus 4;
BA_ "SPN" SG_ 2566766078 TransitDoorEnable 3083;
BA_ "SigType" SG_ 2566766078 TransitDoorEnable 4;
BA_ "SPN" SG_ 2566766078 PriorityOfRespSentByEmitter 3084;
BA_ "SigType" SG_ 2566766078 PriorityOfRespSentByEmitter 4;
BA_ "SPN" SG_ 2566766078 IntersectionPreemptionRq_Resp 3079;
BA_ "SigType" SG_ 2566766078 IntersectionPreemptionRq_Resp 4;
BA_ "SPN" SG_ 2566766078 TransitRouteIDUsage 3080;
BA_ "SigType" SG_ 2566766078 TransitRouteIDUsage 4;
BA_ "SPN" SG_ 2566766078 RangeCodeEnable 3081;
BA_ "SigType" SG_ 2566766078 RangeCodeEnable 4;
BA_ "SPN" SG_ 2566766590 NmbrOfBytsInMlpstIdentification 3070;
BA_ "SigType" SG_ 2566766590 NmbrOfBytsInMlpstIdentification 1;
VAL_ 2566811134 CabHeatingZone 3 "NotAvailable" 2 "Reserved" 1 "CabHeatingZoneOn" 0 "CabHeatingZoneOff" ;
VAL_ 2566811134 EngHeatingZone 3 "NotAvailable" 2 "Reserved" 1 "EngHeatingZoneOn" 0 "EngHeatingZoneOff" ;
VAL_ 2566811134 CabVentilation 3 "NotAvailable" 2 "Reserved" 1 "CabIsVentilated" 0 "CabNotVentilated" ;
VAL_ 2566811134 AuxHeaterWaterPumpStatus 3 "NotAvailable" 2 "Reserved" 1 "WaterPumpIsRunning" 0 "WaterPumpIsNotRunning" ;
VAL_ 2565867774 FireApparatusPumpEngagement 3 "NotAvailableNotInstalled" 2 "Error" 1 "PumpEngaged" 0 "PumpNotEngaged" ;
VAL_ 2565867774 EngHydPressGovernorSwitch 3 "NotAvailable" 2 "ErrorIndicator" 1 "PressModeActive" 0 "PressModeInactive" ;
VAL_ 2565867774 EngHydPrssGovernorModeIndicator 3 "NotAvailable" 2 "ErrorIndicator" 1 "Enabled" 0 "Disabled" ;
VAL_ 2365449982 HydBrakeFluidLevelSwitch 3 "NotAvailable" 2 "ErrorIndicator" 1 "FluidLevelIsSufficient" 0 "FluidLevelIsNotSufficient" ;
VAL_ 2365449982 HydBrakeSystemAudibleWarningCmd 3 "DontCare" 2 "Reserved" 1 "AudibleWarningOn" 0 "AudibleWarningOff" ;
VAL_ 2365449982 HydBrkePressSupplyStateCircuit2 3 "NotAvailable" 2 "ErrorIndicator" 1 "SupplyIsReliable" 0 "SupplyIsNotReliable" ;
VAL_ 2365449982 HydBrkePressSupplyStateCircuit1 3 "NotAvailable" 2 "ErrorIndicator" 1 "SupplyIsReliable" 0 "SupplyIsNotReliable" ;
VAL_ 2365449982 HydBrkPressWarningStateCircuit2 3 "NotAvailable" 2 "ErrorIndicator" 1 "PressLevelBelowWarningLevel" 0 "PressLevelSufficient" ;
VAL_ 2365449982 HydBrkPressWarningStateCircuit1 3 "NotAvailable" 2 "ErrorIndicator" 1 "PressLevelBelowWarningLevel" 0 "PressLevelSufficient" ;
VAL_ 2566759678 EnggmntSttusTransInputShaftPTO1 3 "NotAvailable" 2 "Error" 1 "DriveIsEngaged" 0 "DriveNotEngaged" ;
VAL_ 2566759678 EnggmntSttusTransInputShaftPTO2 3 "NotAvailable" 2 "Error" 1 "DriveIsEngaged" 0 "DriveNotEngaged" ;
VAL_ 2566759678 EnggmntSttusTransOutputShaftPTO 3 "NotAvailable" 2 "Error" 1 "DriveIsEngaged" 0 "DriveNotEngaged" ;
VAL_ 2566759678 EnggmntSttsTrnsfrCsOtptShaftPTO 3 "NotAvailable" 2 "Error" 1 "DriveIsEngaged" 0 "DriveNotEngaged" ;
VAL_ 2566759678 EnggmntCnsntTransInputShaftPTO1 3 "NotAvailable" 2 "Error" 1 "CnsentGivenPTODriveMayBeEngaged" 0 "CnsntNtGvnPTODrvShldNtBeEngaged" ;
VAL_ 2566759678 EnggmntCnsntTransInputShaftPTO2 3 "NotAvailable" 2 "Error" 1 "CnsentGivenPTODriveMayBeEngaged" 0 "CnsntNtGvnPTODrvShldNtBeEngaged" ;
VAL_ 2566759678 EnggmntCnsntTransOutputShaftPTO 3 "NotAvailable" 2 "Error" 1 "CnsentGivenPTODriveMayBeEngaged" 0 "CnsntNtGvnPTODrvShldNtBeEngaged" ;
VAL_ 2566759678 EnggmntCnsntTrnsfrCsOtptShftPTO 3 "NotAvailable" 2 "Error" 1 "CnsentGivenPTODriveMayBeEngaged" 0 "CnsntNtGvnPTODrvShldNtBeEngaged" ;
VAL_ 2566759678 EnableSwitchTransInputShaftPTO1 3 "NotAvailable" 2 "Error" 1 "EnblSwtchOffPTOOperationDesired" 0 "EnblSwtchOffPTOOprtonNotDesired" ;
VAL_ 2566759678 EnableSwitchTransInputShaftPTO2 3 "NotAvailable" 2 "Error" 1 "EnblSwtchOffPTOOperationDesired" 0 "EnblSwtchOffPTOOprtonNotDesired" ;
VAL_ 2566759678 EnableSwitchTransOutputShaftPTO 3 "NotAvailable" 2 "Error" 1 "EnblSwtchOffPTOOperationDesired" 0 "EnblSwtchOffPTOOprtonNotDesired" ;
VAL_ 2566759678 EnblSwtchTrnsfrCsOutputShaftPTO 3 "NotAvailable" 2 "Error" 1 "EnblSwtchOffPTOOperationDesired" 0 "EnblSwtchOffPTOOprtonNotDesired" ;
VAL_ 2566759678 EnggmntSttsPTOEngAccssoryDrive2 3 "NotAvailable" 2 "Error" 1 "DriveEngaged" 0 "DriveNotEngaged" ;
VAL_ 2566759678 EnggmntSttsPTOEngAccssoryDrive1 3 "NotAvailable" 2 "Error" 1 "DriveEngaged" 0 "DriveNotEngaged" ;
VAL_ 2566759678 EnggmntCnsntPTOEngAccssryDrive2 3 "NotAvailable" 2 "Error" 1 "CnsentGivenPTODriveMayBeEngaged" 0 "CnsntNtGvnPTODrvMayNotBeEngaged" ;
VAL_ 2566759678 EnggmntCnsntPTOEngAccssryDrive1 3 "NotAvailable" 2 "Error" 1 "CnsentGivenPTODriveMayBeEngaged" 0 "CnsntNtGvnPTODrvMayNotBeEngaged" ;
VAL_ 2566759678 EngagementStatusPTOEngFlywheel 3 "NotAvailable" 2 "Error" 1 "DriveEngaged" 0 "DriveNotEngaged" ;
VAL_ 2566759678 EngagementConsentPTOEngFlywheel 3 "NotAvailable" 2 "Error" 1 "CnsentGivenPTODriveMayBeEngaged" 0 "CnsntNtGvnPTODrvMayNotBeEngaged" ;
VAL_ 2566759678 EnblSwitchPTOEngAccessoryDrive2 3 "NotAvailable" 2 "Error" 1 "EnblSwitchOnPTOOperationDesired" 0 "EnblSwtchOffPTOOprtonNotDesired" ;
VAL_ 2566759678 EnblSwitchPTOEngAccessoryDrive1 3 "NotAvailable" 2 "Error" 1 "EnblSwitchOnPTOOperationDesired" 0 "EnblSwtchOffPTOOprtonNotDesired" ;
VAL_ 2566759678 EnableSwitchPTOEngFlywheel 3 "NotAvailable" 2 "Error" 1 "EnblSwitchOnPTOOperationDesired" 0 "EnblSwtchOffPTOOprtonNotDesired" ;
VAL_ 2566759678 AtLeastOnePTOEngaged 3 "NotAvailable" 2 "Error" 1 "AtLeastOnePTODriveIsEngaged" 0 "NoPTODriveIsEngaged" ;
VAL_ 2432541694 EngTrbCmprssrBypssActtr1TmpStts 7 "NotAvailable" 6 "Error" 5 "NotDefined" 4 "LowMostSevere" 3 "LowLeastSevere" 2 "InRange" 1 "HighLeastSevere" 0 "HighMostSevere" ;
VAL_ 2432541694 EngTrbCmprssrBypassActuator2Cmd 4 "RprsntsFllyOpnTypcllyTrbCmprssr" ;
VAL_ 2432541694 EngTrbCmprssrBypassActuator1Pos 4 "RprsntsBypssFllyOpnTypcllyCmprs" ;
VAL_ 2432541694 EngTrbCmprssrBypassActuator1Cmd 4 "RprsntsFllyOpnTypcllyTrbCmprssr" ;
VAL_ 2566759934 EnableStatusOfDoor10 3 "notAvailable" 2 "error" 1 "doorEnabled" 0 "doorDisabled" ;
VAL_ 2566759934 OpenStatusOfDoor10 3 "notAvailable" 2 "error" 1 "doorOpened" 0 "doorClosed" ;
VAL_ 2566759934 LockStatusOfDoor10 3 "notAvailable" 2 "error" 1 "locked" 0 "unlocked" ;
VAL_ 2566759934 EnableStatusOfDoor9 3 "notAvailable" 2 "error" 1 "doorEnabled" 0 "doorDisabled" ;
VAL_ 2566759934 OpenStatusOfDoor9 3 "notAvailable" 2 "error" 1 "doorOpened" 0 "doorClosed" ;
VAL_ 2566759934 LockStatusOfDoor9 3 "notAvailable" 2 "error" 1 "locked" 0 "unlocked" ;
VAL_ 2566759934 EnableStatusOfDoor8 3 "notAvailable" 2 "error" 1 "doorEnabled" 0 "doorDisabled" ;
VAL_ 2566759934 OpenStatusOfDoor8 3 "notAvailable" 2 "error" 1 "doorOpened" 0 "doorClosed" ;
VAL_ 2566759934 LockStatusOfDoor8 3 "notAvailable" 2 "error" 1 "locked" 0 "unlocked" ;
VAL_ 2566759934 EnableStatusOfDoor7 3 "notAvailable" 2 "error" 1 "doorEnabled" 0 "doorDisabled" ;
VAL_ 2566759934 OpenStatusOfDoor7 3 "notAvailable" 2 "error" 1 "doorOpened" 0 "doorClosed" ;
VAL_ 2566759934 LockStatusOfDoor7 3 "notAvailable" 2 "error" 1 "locked" 0 "unlocked" ;
VAL_ 2566759934 EnableStatusOfDoor6 3 "notAvailable" 2 "error" 1 "doorEnabled" 0 "doorDisabled" ;
VAL_ 2566759934 OpenStatusOfDoor6 3 "notAvailable" 2 "error" 1 "doorOpened" 0 "doorClosed" ;
VAL_ 2566759934 LockStatusOfDoor6 3 "notAvailable" 2 "error" 1 "locked" 0 "unlocked" ;
VAL_ 2566759934 EnableStatusOfDoor5 3 "notAvailable" 2 "error" 1 "doorEnabled" 0 "doorDisabled" ;
VAL_ 2566759934 OpenStatusOfDoor5 3 "notAvailable" 2 "error" 1 "doorOpened" 0 "doorClosed" ;
VAL_ 2566759934 LockStatusOfDoor5 3 "notAvailable" 2 "error" 1 "locked" 0 "unlocked" ;
VAL_ 2566759934 EnableStatusOfDoor4 3 "notAvailable" 2 "error" 1 "doorEnabled" 0 "doorDisabled" ;
VAL_ 2566759934 OpenStatusOfDoor4 3 "notAvailable" 2 "error" 1 "doorOpened" 0 "doorClosed" ;
VAL_ 2566759934 LockStatusOfDoor4 3 "notAvailable" 2 "error" 1 "locked" 0 "unlocked" ;
VAL_ 2566759934 EnableStatusOfDoor3 3 "notAvailable" 2 "error" 1 "doorEnabled" 0 "doorDisabled" ;
VAL_ 2566759934 OpenStatusOfDoor3 3 "notAvailable" 2 "error" 1 "doorOpened" 0 "doorClosed" ;
VAL_ 2566759934 LockStatusOfDoor3 3 "notAvailable" 2 "error" 1 "locked" 0 "unlocked" ;
VAL_ 2566759934 EnableStatusOfDoor2 3 "notAvailable" 2 "error" 1 "doorEnabled" 0 "doorDisabled" ;
VAL_ 2566759934 OpenStatusOfDoor2 3 "notAvailable" 2 "error" 1 "doorOpened" 0 "doorClosed" ;
VAL_ 2566759934 LockStatusOfDoor2 3 "notAvailable" 2 "error" 1 "locked" 0 "unlocked" ;
VAL_ 2566759934 EnableStatusOfDoor1 3 "notAvailable" 2 "error" 1 "doorEnabled" 0 "doorDisabled" ;
VAL_ 2566759934 OpenStatusOfDoor1 3 "notAvailable" 2 "error" 1 "doorOpened" 0 "doorClosed" ;
VAL_ 2566759934 LockStatusOfDoor1 3 "notAvailable" 2 "error" 1 "locked" 0 "unlocked" ;
VAL_ 2566757374 Aftrtrtmnt1SCRCtlystReagentType 15 "NotAvailable" 14 "ErrrDtctdWthUrRgntTypeDetection" 13 "NtAblTDtrmneCatalystReagentType" 5 "to1100ReservedForSAEAssignment" 3 "CatalystReagentIsProperMixture" 2 "CatalystReagentIsDiesel" 1 "CtlystRgntIsUrCncntrationTooLow" 0 "CtlystRgntIsUrCncntrtionTooHigh" ;
VAL_ 2364544766 EngCyl9CombustionStatus 3 "NotAvailable" 2 "Error" 1 "CombustionExists" 0 "NoCombustion" ;
VAL_ 2364544766 EngCyl8CombustionStatus 3 "NotAvailable" 2 "Error" 1 "CombustionExists" 0 "NoCombustion" ;
VAL_ 2364544766 EngCyl7CombustionStatus 3 "NotAvailable" 2 "Error" 1 "CombustionExists" 0 "NoCombustion" ;
VAL_ 2364544766 EngCyl6CombustionStatus 3 "NotAvailable" 2 "Error" 1 "CombustionExists" 0 "NoCombustion" ;
VAL_ 2364544766 EngCyl5CombustionStatus 1 "CombustionExists" 0 "NoCombustion" 3 "NotAvailable" 2 "Error" ;
VAL_ 2364544766 EngCyl4CombustionStatus 3 "NotAvailable" 2 "Error" 1 "CombustionExists" 0 "NoCombustion" ;
VAL_ 2364544766 EngCyl3CombustionStatus 3 "NotAvailable" 2 "Error" 1 "CombustionExists" 0 "NoCombustion" ;
VAL_ 2364544766 EngCyl2CombustionStatus 3 "NotAvailable" 2 "Error" 1 "CombustionExists" 0 "NoCombustion" ;
VAL_ 2364544766 EngCyl24CombustionStatus 3 "NotAvailable" 2 "Error" 1 "CombustionExists" 0 "NoCombustion" ;
VAL_ 2364544766 EngCyl23CombustionStatus 3 "NotAvailable" 2 "Error" 1 "CombustionExists" 0 "NoCombustion" ;
VAL_ 2364544766 EngCyl22CombustionStatus 3 "NotAvailable" 2 "Error" 1 "CombustionExists" 0 "NoCombustion" ;
VAL_ 2364544766 EngCyl21CombustionStatus 3 "NotAvailable" 2 "Error" 1 "CombustionExists" 0 "NoCombustion" ;
VAL_ 2364544766 EngCyl20CombustionStatus 3 "NotAvailable" 2 "Error" 1 "CombustionExists" 0 "NoCombustion" ;
VAL_ 2364544766 EngCyl1CombustionStatus 3 "NotAvailable" 2 "Error" 1 "CombustionExists" 0 "NoCombustion" ;
VAL_ 2364544766 EngCyl19CombustionStatus 3 "NotAvailable" 2 "Error" 1 "CombustionExists" 0 "NoCombustion" ;
VAL_ 2364544766 EngCyl18CombustionStatus 3 "NotAvailable" 2 "Error" 1 "CombustionExists" 0 "NoCombustion" ;
VAL_ 2364544766 EngCyl17CombustionStatus 3 "NotAvailable" 2 "Error" 1 "CombustionExists" 0 "NoCombustion" ;
VAL_ 2364544766 EngCyl16CombustionStatus 3 "NotAvailable" 2 "Error" 1 "CombustionExists" 0 "NoCombustion" ;
VAL_ 2364544766 EngCyl15CombustionStatus 3 "NotAvailable" 2 "Error" 1 "CombustionExists" 0 "NoCombustion" ;
VAL_ 2364544766 EngCyl14CombustionStatus 3 "NotAvailable" 2 "Error" 1 "CombustionExists" 0 "NoCombustion" ;
VAL_ 2364544766 EngCyl13CombustionStatus 3 "NotAvailable" 2 "Error" 1 "CombustionExists" 0 "NoCombustion" ;
VAL_ 2364544766 EngCyl12CombustionStatus 3 "NotAvailable" 2 "Error" 1 "CombustionExists" 0 "NoCombustion" ;
VAL_ 2364544766 EngCyl11CombustionStatus 3 "NotAvailable" 2 "Error" 1 "CombustionExists" 0 "NoCombustion" ;
VAL_ 2364544766 EngCyl10CombustionStatus 3 "NotAvailable" 2 "Error" 1 "CombustionExists" 0 "NoCombustion" ;
VAL_ 2364544510 RqGenOverallPowerFactorLagging 3 "NotAvailable" 2 "Error" 1 "Lagging" 0 "Leading" ;
VAL_ 2364544254 RlativeBladeHeightFigureOfMerit 3 "RelativeBladeHeightNotAvailable" 2 "RelativeBladeHeightFailed" 1 "RltvBldHghtDgrddDtIsSspctDTEnvr" 0 "RltvBldHghtFllyFnctnlDtIsWthnSn" ;
VAL_ 2364544254 BladeRotationAngleFigureOfMerit 3 "BladeRotationAngleNotAvailable" 2 "BldRttnAnglFldRllSnsrFldTOprtCr" 1 "BldRttnAnglDgrddDtIsSspctDTEnvr" 0 "BldRttnAnglFllyFnctnlDtIsWthnSn" ;
VAL_ 2348992544 VehicleType 1 "Dolly axle" 0 "Towing or towed vehicle" ;
VAL_ 2348992544 BrakeLightSwitch 1 "Switch on" 0 "Switch off" ;
VAL_ 2348992544 ASREngineControlActive 3 "NotAvailable" 2 "Reserved" 1 "ASREngineControlActive" 0 "ASREngnCntrlPassiveButInstalled" ;
VAL_ 2348992544 ASRBreakControlActive 1 "Active" 0 "Passive, but installed" ;
VAL_ 2348992544 VehicleRetarderCtrlActive 1 "Active" 0 "Passive" ;
VAL_ 2348992544 VehicleABSActive 1 "Active" 0 "Passiv, but installed" ;
VAL_ 2566834464 PneumaticControlLine 1 "Towing veh with pn ctrl line" 0 "Towing veh without pn ctrl line" ;
VAL_ 2566834464 ABSOffroadRequest 1 "ABS off-road switch on" 0 "ABS off-road switch off" ;
VAL_ 2566834464 TwoElCircuitsBrakeDemand 1 "Two el. circuit brake available" 0 "One el. circuit brake available" ;
VAL_ 2566834464 VehicleRetarderCtrlActive 1 "Active" 0 "Passive" ;
VAL_ 2550341832 SupplyLineBrakingRequest 1 "Supply line braking request" 0 "No supply line braking request" ;
VAL_ 2550341832 VDCActive 1 "Active" 0 "Passive, but installed" ;
VAL_ 2550341832 AutomTowedVehBreakActive 1 "Active" 0 "Passive" ;
VAL_ 2550341832 VehicleServiceBrakeActive 1 "Active" 0 "Passive" ;
VAL_ 2550341832 VehicleRetarderCtrlActive 1 "Active" 0 "Passive" ;
VAL_ 2550341832 VehicleABSActive 1 "Active" 0 "Passiv, but installed" ;
VAL_ 2566833352 SupplyLineBrakingRequest 1 "Supply line braking request" 0 "No supply line braking request" ;
VAL_ 2566833352 LoadingRampApproachAssist 1 "Assistance active" 0 "Assistance not active" ;
VAL_ 2566833352 SpringBrakeEngaged 1 "Vehicle spring brake is engaged" 0 "Vehicle spring brake is released" ;
VAL_ 2566833352 ElectrLoadPropFunc 1 "Vehicle with el. load proportion" 0 "Vehicle without el. load proport" ;
VAL_ 2566833352 SpringBrakeInstalled 1 "Vehicle with spring brakes" 0 "Vehicle without spring brakes" ;
VAL_ 2566833352 VehicleType 1 "Dolly axle" 0 "Towing or towed vehicle" ;
VAL_ 2566833352 ElecSupplyOfNonBrakingSys 1 "Supply switched on" 0 "Supply switched off" ;
VAL_ 2566833352 AmberWarningSignalReq 1 "Towed vehicle failure indicated" 0 "No towed vehicle failure indicat" ;
VAL_ 2566833352 RedWarningSignalRequest 1 "Towed vehicle failure indicated" 0 "No towed vehicle failure indicat" ;
VAL_ 2566833352 VehicleElectrSupplySuff 1 "Vehicle el. supply sufficient" 0 "Vehicle el. supply insufficient" ;
VAL_ 2566833352 AutomTowedVehBreakActive 1 "Active" 0 "Passive" ;
VAL_ 2566833352 VehicleServiceBrakeActive 1 "Active" 0 "Passive" ;
VAL_ 2566833352 VehicleRetarderCtrlActive 1 "Active" 0 "Passive" ;
VAL_ 2566833352 VehicleABSActive 1 "Active" 0 "Passiv, but installed" ;
VAL_ 2365507272 TyreWheelIdentTemp2 15 "Axle position 15" 14 "Axle position 14" 13 "Axle position 13" 12 "Axle position 12" 11 "Axle position 11" 10 "Axle position 10" 9 "Axle position 9" 8 "Axle position 8" 7 "Axle position 7" 6 "Axle position 6" 5 "Axle position 5" 4 "Axle position 4" 3 "Axle position 3" 2 "Axle position 2" 1 "Axle position 1" 0 "Axle position not identified" ;
VAL_ 2365507272 TyreWheelIdentTemp1 15 "Wheel position 15" 14 "Wheel position 14" 13 "Wheel position 13" 12 "Wheel position 12" 11 "Wheel position 11" 10 "Wheel position 10" 9 "Wheel position 9" 8 "Wheel position 8" 7 "Wheel position 7" 6 "Wheel position 6" 5 "Wheel position 5" 4 "Wheel position 4" 3 "Wheel position 3" 2 "Wheel position 2" 1 "Wheel position 1" 0 "Wheel position not identified" ;
VAL_ 2365507272 TyreWheelIdentPressure2 15 "Axle position 15" 14 "Axle position 14" 13 "Axle position 13" 12 "Axle position 12" 11 "Axle position 11" 10 "Axle position 10" 9 "Axle position 9" 8 "Axle position 8" 7 "Axle position 7" 6 "Axle position 6" 5 "Axle position 5" 4 "Axle position 4" 3 "Axle position 3" 2 "Axle position 2" 1 "Axle position 1" 0 "Axle position not identified" ;
VAL_ 2365507272 TyreWheelIdentPressure1 15 "Wheel position 15" 14 "Wheel position 14" 13 "Wheel position 13" 12 "Wheel position 12" 11 "Wheel position 11" 10 "Wheel position 10" 9 "Wheel position 9" 8 "Wheel position 8" 7 "Wheel position 7" 6 "Wheel position 6" 5 "Wheel position 5" 4 "Wheel position 4" 3 "Wheel position 3" 2 "Wheel position 2" 1 "Wheel position 1" 0 "Wheel position not identified" ;
VAL_ 2365507272 TyreWheelIdentLining2 15 "Axle position 15" 14 "Axle position 14" 13 "Axle position 13" 12 "Axle position 12" 11 "Axle position 11" 10 "Axle position 10" 9 "Axle position 9" 8 "Axle position 8" 7 "Axle position 7" 6 "Axle position 6" 5 "Axle position 5" 4 "Axle position 4" 3 "Axle position 3" 2 "Axle position 2" 1 "Axle position 1" 0 "Axle position not identified" ;
VAL_ 2365507272 TyreWheelIdentLining1 15 "Wheel position 15" 14 "Wheel position 14" 13 "Wheel position 13" 12 "Wheel position 12" 11 "Wheel position 11" 10 "Wheel position 10" 9 "Wheel position 9" 8 "Wheel position 8" 7 "Wheel position 7" 6 "Wheel position 6" 5 "Wheel position 5" 4 "Wheel position 4" 3 "Wheel position 3" 2 "Wheel position 2" 1 "Wheel position 1" 0 "Wheel position not identified" ;
VAL_ 2365507272 VehiclePneumSupplySuff 1 "Pneumatic supply sufficient" 0 "Pneumatic supply insufficient" ;
VAL_ 2365507272 BrakeTemperatureStatus 1 "Brake temperature normal" 0 "Brake temperature out of range" ;
VAL_ 2365507272 BrakeLiningSufficient 1 "Brake linings sufficient" 0 "Brake linings insufficient" ;
VAL_ 2365507272 TyrePressureSufficient 1 "Tyre pressure sufficient" 0 "Tyre pressure insufficient" ;
VAL_ 2565013246 ODDRequest 3 "Take no action" 1 "ODD on" 0 "ODD off" ;
VAL_ 2565013246 AntiTheftDeviceReq 3 "Take no action" 1 "Anti-theft device on" 0 "Anti-theft device off" ;
VAL_ 2565013246 VehicleType 1 "Dolly axle" 0 "Towing or towed vehicle" ;
VAL_ 2365480958 EngineTorqueMode 15 "Not available" 11 "Remote accelerator" 10 "Braking system" 9 "High speed governor" 8 "Torque limiting" 7 "ABS control" 6 "Transmission control" 5 "ASR control" 4 "Road speed governor" 3 "PTO governor" 2 "Cruise control" 1 "Accelerator pedal/operator selec" 0 "Low idle governor/no request (de" ;
VAL_ 2365480958 EngineRunning 1 "Engine running" 0 "Engine not running" ;
VAL_ 2365480958 EngineControlAllowed 1 "Engine control allowed" 0 "Engine control not allowed" ;
VAL_ 2566808062 ClutchIndptdPTOFeedback 1 "Engaged" 0 "Not engaged" ;
VAL_ 2566808062 AccelPedalLowIdleSwitch 1 "In low idle condition" 0 "Not in low idle condition" ;
VAL_ 2566808062 StarterActive 1 "Starter active" 0 "Starter not active" ;
VAL_ 2566808062 TorqueConvtOilTempWarning 2 "Warning" 1 "Prewarning" 0 "No warning" ;
VAL_ 2566808062 PTOControlAllowed 1 "PTO control allowed" 0 "PTO control not allowed" ;
VAL_ 2566808062 SecEngineMtdPTOFeedback 1 "Limits activated" 0 "Limits not activated" ;
VAL_ 2566808062 FirstEngineMtdPTOFeedback 1 "Limits activated" 0 "Limits not activated" ;
VAL_ 2566808062 SecClutchDptdPTOFeedback 1 "Engaged" 0 "Not engaged" ;
VAL_ 2566808062 FirstClutchDpdtPTOFeedback 1 "Engaged" 0 "Not engaged" ;
VAL_ 2566808574 FuelLevelWarning 1 "Fuel level warning on" 0 "Fuel level warning off" ;
VAL_ 2566808574 EngineOilPressureWarning 1 "Warning" 0 "No warning" ;
VAL_ 2566808574 EngineCoolantTempWarning 2 "Warning" 1 "Prewarning" 0 "No warning" ;
VAL_ 2564947710 VehicleType 1 "Dolly axle" 0 "Towing or towed vehicle" ;
VAL_ 2566834430 AntiTheftDeviceStatus 1 "Anti-theft device on" 0 "Anti-theft device off" ;
VAL_ 2566834430 ODDStatus 1 "ODD active" 0 "ODD inactive" ;
VAL_ 2566808318 SecEngineMtdPTOSwitch 1 "Switched on" 0 "Switched off" ;
VAL_ 2566808318 SecClutchDpdtPTOSwitch 1 "Switched on" 0 "Switched off" ;
VAL_ 2566808318 FirstClutchDpdtPTOSwitch 1 "Switched on" 0 "Switched off" ;
VAL_ 2566808318 OperatingPanelActive 1 "Operating panel active" 0 "Operating panel not active" ;
VAL_ 2566808318 RefusePackerStepSwitch 1 "Switched on" 0 "Switched off" ;
VAL_ 2566808318 EngineStopSwitch 1 "Switched on" 0 "Switched off" ;
VAL_ 2566808318 EngineStartSwitch 1 "Switched on" 0 "Switched off" ;
VAL_ 2566808318 StarterLockoutSwitch 1 "Switched on" 0 "Switched off" ;
VAL_ 2566808318 FirstEngineMtdPTOSwitch 1 "Switched on" 0 "Switched off" ;
VAL_ 2566808318 ClutchIndpdtPTOSwitch 1 "Switched on" 0 "Switched off" ;
VAL_ 2566808830 TrailerLeftSideMarkerLight 1 "Lamp(s) lit" 0 "Lamp(s) not lit" ;
VAL_ 2566808830 TrailerLeftReversingLight 1 "Lamp(s) lit" 0 "Lamp(s) not lit" ;
VAL_ 2566808830 TrailerLeftRearWidIndLight 1 "Lamp(s) lit" 0 "Lamp(s) not lit" ;
VAL_ 2566808830 TrailerLeftRearRegPltLight 1 "Lamp(s) lit" 0 "Lamp(s) not lit" ;
VAL_ 2566808830 TrailerLeftRearLight 1 "Lamp(s) lit" 0 "Lamp(s) not lit" ;
VAL_ 2566808830 TrailerLeftRearFogLight 1 "Lamp(s) lit" 0 "Lamp(s) not lit" ;
VAL_ 2566808830 TrailerLeftDirIndLight 1 "Lamp(s) lit" 0 "Lamp(s) not lit" ;
VAL_ 2566808830 TrailerLeftCrnMarkerLight 1 "Lamp(s) lit" 0 "Lamp(s) not lit" ;
VAL_ 2566808830 TrailerInteriorLight 1 "Lamp(s) lit" 0 "Lamp(s) not lit" ;
VAL_ 2566808830 TrailerWorkLamp 1 "Lamp(s) lit" 0 "Lamp(s) not lit" ;
VAL_ 2566808830 TrailerRotatingIdentLight 1 "Lamp(s) lit" 0 "Lamp(s) not lit" ;
VAL_ 2566808830 TrailerRightStopLight 1 "Lamp(s) lit" 0 "Lamp(s) not lit" ;
VAL_ 2566808830 TrailerRightSideMrkLight 1 "Lamp(s) lit" 0 "Lamp(s) not lit" ;
VAL_ 2566808830 TrailerRightReversingLight 1 "Lamp(s) lit" 0 "Lamp(s) not lit" ;
VAL_ 2566808830 TrailRightRearWidIndLight 1 "Lamp(s) lit" 0 "Lamp(s) not lit" ;
VAL_ 2566808830 TrailerRightRearRegPltLight 1 "Lamp(s) lit" 0 "Lamp(s) not lit" ;
VAL_ 2566808830 TrailerRightRearLight 1 "Lamp(s) lit" 0 "Lamp(s) not lit" ;
VAL_ 2566808830 TrailerRightRearFogLight 1 "Lamp(s) lit" 0 "Lamp(s) not lit" ;
VAL_ 2566808830 TrailerRightDirIndLight 1 "Lamp(s) lit" 0 "Lamp(s) not lit" ;
VAL_ 2566808830 TrailerRightCrnMarkerLight 1 "Lamp(s) lit" 0 "Lamp(s) not lit" ;
VAL_ 2566808830 TrailerRearWarningLight 1 "Lamp(s) lit" 0 "Lamp(s) not lit" ;
VAL_ 2566808830 TrailerLeftStopLight 1 "Lamp(s) lit" 0 "Lamp(s) not lit" ;
VAL_ 2565734142 ControlByte 6 "MFDB_CreateEntry" 5 "MFDB_SetMode" 4 "MFDB_Clear" 3 "MFDB_Delete" 2 "MFDB_Add" 1 "MFDB_Response" 0 "MFDB_Request" ;
VAL_ 2565734142 FilterMode 1 "PassSpecificPGNs" 0 "BlockSpecificPGNs" ;
VAL_ 2565130272 StopLevelChangeReq 3 "Take no action" 1 "Stop request" 0 "No stop request" ;
VAL_ 2565130272 RampLevelStorageReq 3 "Take no action" 1 "Store ramp level 2" 0 "Store ramp level 1" ;
VAL_ 2565130272 LevelControlReq 3 "Take no action" 1 "Enable level control" 0 "Disable level control" ;
VAL_ 2565130272 RampLevelReq 3 "Take no action" 1 "Ramp level 2" 0 "Ramp level 1" ;
VAL_ 2565130272 SteeringAxleLockingReq 3 "Take no action" 1 "Lock steering axle" 0 "Unlock steering axle" ;
VAL_ 2565130272 LiftAxle2PositionReq 3 "Take no action" 1 "Position up / tag axle unladen" 0 "Position down / tag axle laden" ;
VAL_ 2565130272 LiftAxle1PositionReq 3 "Don't care/take no action" 2 "Reserved" 1 "Position up / tag axle unladen" 0 "Position down / tag axle laden" ;
VAL_ 2565130272 TractionHelpReq 3 "Take no action" 1 "Traction help request" 0 "No traction help request" ;
VAL_ 2565130272 LevelChangeReqRearAxle 3 "Take no action" 1 "Vehicle body down (lowering)" 0 "Vehicle body up (lifting)" ;
VAL_ 2565130272 LevelChangeReqFrontAxle 3 "Take no action" 1 "Vehicle body down (lowering)" 0 "Vehicle body up (lifting)" ;
VAL_ 2565130272 RideHeightRequest_RGE11 3 "Take no action" 1 "Normal level 2" 0 "Normal level 1" ;
VAL_ 2565209854 LevelControl 1 "Level control enabled" 0 "Level control disabled" ;
VAL_ 2565209854 RampLevel 1 "Body at requested ramp level" 0 "Body not at requested ramp level" ;
VAL_ 2565209854 NormalLevel 3 "Not available" 1 "Normal level 2" 0 "Normal level 1" ;
VAL_ 2565209854 StopLevelChangeAcknowledge 1 "Level change stopped" 0 "No stop request" ;
VAL_ 2565209854 LevelChangeRearAxle 1 "Body lifting/lowering active" 0 "Body lifting/lowering not active" ;
VAL_ 2565209854 LevelChangeFrontAxle 1 "Body lifting/lowering active" 0 "Body lifting/lowering not active" ;
VAL_ 2565209854 RampLevelStorage 1 "New ramp level stored" 0 "No new storage request" ;
VAL_ 2565209854 SteeringAxleLocking 1 "Steering axle locked" 0 "Steering axle unlocked" ;
VAL_ 2565209854 LiftAxle2Pos 3 "NotAvailable" 2 "Error" 1 "LiftAxlePosUp_TagAxleUnladen" 0 "LiftAxlePosDown_TagAxleLaden" ;
VAL_ 2565209854 LiftAxle1Pos 3 "NotAvailable" 2 "Error" 1 "LiftAxlePosUp_TagAxleUnladen" 0 "LiftAxlePosDown_TagAxleLaden" ;
VAL_ 2565209854 RampLevelPosition 3 "Not available" 1 "Ramp level 2" 0 "Ramp level 1" ;
VAL_ 2565209854 TractionHelp 1 "Traction help active" 0 "Traction help inactive" ;
VAL_ 2565209854 LevelCtrlSysRideHeightLevel 1 "Vehicle body at requested level" 0 "Vehicle body not at req. level" ;
VAL_ 2566807294 TyrePressThresholdDetect 7 "Not available" 6 "Error indicator" 5 "Not defined" 4 "Extreme under pressure" 3 "Under pressure" 2 "No warning pressure" 1 "Over pressure" 0 "Extreme over pressure" ;
VAL_ 2566807294 TyreModulePowerSupply 1 "Sufficient power supply" 0 "Insufficient power supply" ;
VAL_ 2566807294 TyreWheelIdentification2 15 "Axle position 15" 14 "Axle position 14" 13 "Axle position 13" 12 "Axle position 12" 11 "Axle position 11" 10 "Axle position 10" 9 "Axle position 9" 8 "Axle position 8" 7 "Axle position 7" 6 "Axle position 6" 5 "Axle position 5" 4 "Axle position 4" 3 "Axle position 3" 2 "Axle position 2" 1 "Axle position 1" 0 "Axle position not identified" ;
VAL_ 2566807294 TyreWheelIdentification1 15 "Wheel position 15" 14 "Wheel position 14" 13 "Wheel position 13" 12 "Wheel position 12" 11 "Wheel position 11" 10 "Wheel position 10" 9 "Wheel position 9" 8 "Wheel position 8" 7 "Wheel position 7" 6 "Wheel position 6" 5 "Wheel position 5" 4 "Wheel position 4" 3 "Wheel position 3" 2 "Wheel position 2" 1 "Wheel position 1" 0 "Wheel position not identified" ;
VAL_ 2566764798 NMHCConvertingCatalystCompleted 1 "NotCompleteCycle" 0 "CompleteCycleOrNotSupported" ;
VAL_ 2566764798 NMHCConvertingCatalystEnabled 1 "EnabledForCycle" 0 "DisabledForRestOfCycle" ;
VAL_ 2566764798 NOxConvertingCatalystAdsorberCom 1 "NotCompleteCycle" 0 "CompleteCycleOrNotSupported" ;
VAL_ 2566764798 NOxConvertingCatalystAdsorberEna 1 "EnabledForCycle" 0 "DisabledForRestOfCycle" ;
VAL_ 2566764798 DieselParticulateFilterCompleted 1 "NotCompleteCycle" 0 "CompleteCycleOrNotSupported" ;
VAL_ 2566764798 DieselParticulateFilterEnabled 1 "EnabledForCycle" 0 "DisabledForRestOfCycle" ;
VAL_ 2566764798 BoostPressureControlSystemComple 1 "NotCompleteCycle" 0 "CompleteCycleOrNotSupported" ;
VAL_ 2566764798 BoostPressureCtrlSystemEnabled 1 "EnabledForCycle" 0 "DisabledForRestOfCycle" ;
VAL_ 2566764798 MisfireMonitoringComplete 1 "EnabledForCycle" 0 "DisabledForRestOfCycle" ;
VAL_ 2566764798 MisfireMonitoringEnabled 1 "EnabledForCycle" 0 "DisabledForRestOfCycle" ;
VAL_ 2566764798 FuelSystemMonitoringEnabled 1 "NotCompleteCycle" 0 "CompleteCycleOrNotSupported" ;
VAL_ 2566764798 ComprehensiveComptMonComplete 1 "NotCompleteCycle" 0 "CompleteCycleOrNotSupported" ;
VAL_ 2566764798 ComprehensiveCompMonEnabled 1 "NotCompleteCycle" 0 "CompleteCycleOrNotSupported" ;
VAL_ 2566764798 SecondAirSystemMonComplete 1 "EnabledForCycle" 0 "DisabledForRestOfCycle" ;
VAL_ 2566764798 SecondAirSystemMonEnabled 1 "EnabledForCycle" 0 "DisabledForRestOfCycle" ;
VAL_ 2566764798 OxygenSensorMonComplete 1 "EnabledForCycle" 0 "DisabledForRestOfCycle" ;
VAL_ 2566764798 OxygenSensorMonEnabled 1 "NotCompleteCycle" 0 "CompleteCycleOrNotSupported" ;
VAL_ 2566764798 OxygenSensorHeaterMonComplete 1 "EnabledForCycle" 0 "DisabledForRestOfCycle" ;
VAL_ 2566764798 OxygenSensorHeaterMonEnabled 1 "NotCompleteCycle" 0 "CompleteCycleOrNotSupported" ;
VAL_ 2566764798 HeatedCatalystMonComplete 1 "EnabledForCycle" 0 "DisabledForRestOfCycle" ;
VAL_ 2566764798 HeatedCatalystMonEnabled 1 "EnabledForCycle" 0 "DisabledForRestOfCycle" ;
VAL_ 2566764798 EvaporativeSystemMonComplete 1 "NotCompleteCycle" 0 "CompleteCycleOrNotSupported" ;
VAL_ 2566764798 EvaporativeSystemMonEnabled 1 "NotCompleteCycle" 0 "CompleteCycleOrNotSupported" ;
VAL_ 2566764798 EGRSystemMonitoringComplete 1 "NotCompleteCycle" 0 "CompleteCycleOrNotSupported" ;
VAL_ 2566764798 EGRSystemMonitoringEnabled 1 "EnabledForCycle" 0 "DisabledForRestOfCycle" ;
VAL_ 2566764798 ColdStartAidSystemMonComplete 1 "NotCompleteCycle" 0 "CompleteCycleOrNotSupported" ;
VAL_ 2566764798 ColdStartAidSystemMonEnabled 1 "EnabledForCycle" 0 "DisabledForRestOfCycle" ;
VAL_ 2566764798 CatalystMonComplete 1 "NotCompleteCycle" 0 "CompleteCycleOrNotSupported" ;
VAL_ 2566764798 CatalystMonEnabled 1 "NotCompleteCycle" 0 "CompleteCycleOrNotSupported" ;
VAL_ 2566764798 ACSystemRefrigerantMonComplete 1 "NotCompleteCycle" 0 "CompleteCycleOrNotSupported" ;
VAL_ 2566764798 ACSystemRefrigerantMonEnabled 1 "NotCompleteCycle" 0 "CompleteCycleOrNotSupported" ;
VAL_ 2566764798 FuelSystemMonitoringComplete 1 "NotCompleteCycle" 0 "CompleteCycleOrNotSupported" ;
VAL_ 2564095742 SecurityEntityType 3 "Data is Certificate" 2 "Data is Session Key" 1 "Data is Long Key" 0 "Data is Long Seed" ;
VAL_ 2349137662 XBRCtrlMode 3 "NotDefined" 2 "AccelerationControlWithMaxMode" 1 "AccelerationControlWithAddMode" 0 "OverrideDisabled" ;
VAL_ 2349137662 XBRPriority 3 "LwPrrtyUsdInOvrrdDsbldXBRCtrlMd" 2 "MdmPrrtyUsdFrACCSystmsThsMdDsNt" 1 "HighPriorityNotDefined" 0 "HghstPrrtyUsdFrEmrgncySttnsEgFr" ;
VAL_ 2349137662 XBREBIMode 3 "NotDefined" 2 "EndranceBrakeIntegrationAllowed" 1 "OnlyEnduranceBrakesAllowed" 0 "NEndrnceBrakeIntegrationAllowed" ;
VAL_ 2349137662 XBRUrgency 4 "LwRtrdrDynmcsShllBFllyCmpnstdBy" 0 "SttnNtCrtclLwRtrdrDynmcsArTlrtd" ;
VAL_ 2566848510 WaterInFuelIndicator 3 "NotAvailable" 2 "Error" 1 "Yes" 0 "No" ;
VAL_ 2566842927 AxleLocation 48 "Axle3_Position0" 32 "Axle2_Position0" 16 "Axle1_Position0" 0 "Axle0_Position0" ;
VAL_ 2566809854 WinchOilPressSwitch 3 "NotAvailable" 2 "ErrrSwtchStteCannotBeDetermined" 1 "OKOilPressIsAboveMin" 0 "NOTOKOilPressIsTooLow" ;
VAL_ 2566809854 HydOilFilterRestrictionSwitch 3 "NotAvailable" 2 "Error" 1 "RestrictionExistsOnOilFilter" 0 "NoRestriction" ;
VAL_ 2565867787 SteerWheelAngleSensorType 3 "NotAvailable" 2 "Reserved" 1 "AbsMeasuringPrinciple" 0 "RelativeMeasuringPrinciple" ;
VAL_ 2565867787 SteerWheelAngle 255 "Not available" 254 "Error" ;
VAL_ 2565867787 LongitudinalAcceleration 255 "Not available" 254 "Error" ;
VAL_ 2565867787 LateralAcceleration 255 "Not available" 254 "Error" ;
VAL_ 2565867787 YawRate 255 "Not available" 254 "Error" ;
VAL_ 2566803211 YCBrakeCtrlActive 3 "DontCare_TakeNoAction" 2 "Reserved" 1 "YCBrakeCtrlActive" 0 "YCBrakeCtrlPassiveButInstalled" ;
VAL_ 2566803211 YCEngCtrlActive 3 "DontCare_TakeNoAction" 2 "Reserved" 1 "YCEngCtrlActive" 0 "YCEngCtrlPassiveButInstalled" ;
VAL_ 2566803211 ROPBrakeCtrlActive 3 "DontCare_TakeNoAction" 2 "Reserved" 1 "ROPBrakeCtrlActive" 0 "ROPBrakeCtrlPassiveButInstalled" ;
VAL_ 2566803211 ROPEngCtrlActive 3 "DontCare_TakeNoAction" 2 "Reserved" 1 "ROPEngCtrlActive" 0 "ROPEngCtrlPassiveButInstalled" ;
VAL_ 2566803211 VDCBrakeLightRq 3 "DontCare_TakeNoAction" 2 "Reserved" 1 "TurnBrakeLightOn" 0 "TurnBrakeLightNotOn" ;
VAL_ 2566803211 VDCFullyOperational 3 "DontCare_TakeNoAction" 2 "Reserved" 1 "FullyOperational" 0 "NotFullyOperational" ;
VAL_ 2566803211 VDCInformationSignal 3 "DontCare_TakeNoAction" 2 "Reserved" 1 "On" 0 "Off" ;
VAL_ 2348814347 OverrideCtrlModePriority_Int 3 "LowPriority" 2 "MdmPrrtyUsdFrPwrtrnCtrlOprtnsWh" 1 "HighPriority" 0 "HghstPrrtyUsdFrSttnsThtRqrImmdt" ;
VAL_ 2348814347 EngRqedSpeedCtrlConditions_Int 3 "XStbOptDrvEngaged" 2 "StbOptDrvEngaged" 1 "StbOptDrvDisengaged" 0 "TrnstOptDrvDisengaged" ;
VAL_ 2348814347 EngOverrideCtrlMode_Int 3 "Spd_TrqLmtCtrlLmtSpdAnd_OrTrqBs" 2 "TrqCtrlCntrlTrqTInclddDsrdTrqVl" 1 "SpdCtrlGvrnSpdTInclddDsrdSpdVle" 0 "OvrrdDsbldDsblAnyExstngCtrlCmdd" ;
VAL_ 2566766846 TransitRunStatus 3 "NotAvailable" 2 "ErrorCondition" 1 "On" 0 "Off" ;
VAL_ 2566766846 VehicleUseStatus 3 "NotAvailable" 2 "ErrorCondition" 1 "UnauthorizedUse" 0 "NormalUse" ;
VAL_ 2566766846 SilentAlarmStatus 3 "NotAvailable" 2 "ErrorCondition" 1 "On" 0 "Off" ;
VAL_ 2566766846 TypeOfPassengerCount 1 "BoardingPassenger" 0 "AbsPassengerCount" 4 "Exiting Passenger (second passenger stream)" 3 "Boarding Passenger (second passenger stream)" 2 "Exiting Passenger" ;
VAL_ 2566765310 FareboxAlarmIdentifier 97 "1111111AgencyDefined" 26 "1100000ReservedToBeAssigned" 25 "MaintenanceAccessOutOfService" 24 "MntnncAccssInSrvcCnsdrdAnAlrmCn" 23 "PaperCurrencyJamCleared" 22 "PaperCurrencyJam" 21 "Pass_TransferJamCleared" 20 "Pass_TransferJam" 19 "FareboxResetToAutomaticMode" 18 "FareboxSetInManualBypass" 17 "CoinDejamOperated" 16 "Card_PassBoxFull" 15 "Card_PassBoxLessThan75Full" 14 "Card_PassBox75Full" 13 "CurrencyBoxFull" 12 "CurrencyBoxLessThan75Full" 11 "CurrencyBox75Full" 10 "CoinboxFull" 9 "Coinbox75Full" 8 "InsufficientFareAccepted" 7 "CshbxOpndInSrvcCnsdrdAnAlrmCndt" 6 "CashboxDoorTimeout" 5 "CashboxRestored" 4 "CashboxRemoved" 3 "ProbeCompleted" 2 "ProbeStarted" 1 "VoltageRestored" 0 "VoltageDropout" ;
VAL_ 2566765310 FareboxEmergencyStatus 3 "NotAvailable" 2 "ErrorCondition" 1 "EmergencyCondition" 0 "NonemergencyCondition" ;
VAL_ 2566765566 TransferType 6 "11111AgencyDefined" 5 "Out" 4 "In" 3 "West" 2 "East" 1 "South" 0 "North" ;
VAL_ 2566765566 TypeOfService 2 "111AgencyDefined" 1 "ExpressService" 0 "LocalService" ;
VAL_ 2566765566 PaymentDetails 11 "1111AgencyDefined" 6 "1010ReservedForAssignment" 5 "Card" 4 "Pass" 3 "Ticket" 2 "Token" 1 "Cash" 0 "NotAnUpgrade" ;
VAL_ 2566765566 TypeOfFare 11 "1111AgencyDefined" 7 "1010ReservedForAssignment" 6 "PassB" 5 "PassA" 4 "TicketB" 3 "TicketA" 2 "TokenB" 1 "TokenA" 0 "Cash_NoDetail" ;
VAL_ 2566765566 TransactionType 12 "1111AgencyDefined" 8 "1011ReservedForAssignment" 7 "Free" 6 "Transfer" 5 "Permit" 4 "Card" 3 "Pass" 2 "Ticket" 1 "Token" 0 "Cash" ;
VAL_ 2566765822 DriversFareboxSecurityCode 1 "SecurityCode" 0 "Farebox is in reporting status" ;
VAL_ 2566765822 FarePresets 16 "to11111111ReservedForAssignment" 0 "to00001111AgencyDefined" ;
VAL_ 2566765822 TripDirection 6 "1111AgencyDefined" 5 "Out" 4 "In" 3 "West" 2 "East" 1 "South" 0 "North" ;
VAL_ 2566765822 TripStatus 6 "LayoverEnd" 5 "LayoverStart" 2 "TripEnd" 1 "TripStart" 7 "Undefined" ;
VAL_ 2566765822 FareboxServiceStatus 3 "NotAvailable" 2 "ErrorCondition" 1 "FareboxInService" 0 "FareboxOutOfService" ;
VAL_ 2566766078 StrobeActivationCtrlStatus 3 "NotAvailable" 2 "ErrorCondition" 1 "ActivateStrobe" 0 "DeactivateStrobe" ;
VAL_ 2566766078 TransitDoorEnable 3 "NotAvailable" 2 "ErrorCondition" 1 "TrnstDrSttsWllOvrrdStrbActvtion" 0 "IgnoreTransitDoorStatus" ;
VAL_ 2566766078 PriorityOfRespSentByEmitter 15 "NotAvailable" 14 "ErrorCondition" 12 "to1101Reserved" 11 "PrrtyStByHardwareToHighPriority" 10 "PrrtyStByHrdwareToProbePriority" 9 "PrrtySetByHardwareToLowPriority" 4 "to1000Reserved" 3 "HighPriority" 2 "ProbePriority" 1 "LowPriority" 0 "Reserved" ;
VAL_ 2566766078 IntersectionPreemptionRq_Resp 3 "NotAvailable" 2 "ErrorCondition" 1 "MessageIsARespFromEmitter" 0 "MessageIsARqDirectedToEmitter" ;
VAL_ 2566766078 TransitRouteIDUsage 3 "NotAvailable" 2 "ErrorCondition" 1 "TrnstRtIDUsedForInterleavedData" 0 "TrnstRtIDNtUsdFrInterleavedData" ;
VAL_ 2566766078 RangeCodeEnable 3 "NotAvailable" 2 "ErrorCondition" 1 "RangeCodeUsedForInterleavedData" 0 "RngCdeNotUsedForInterleavedData" ;
